VERSION "0.2"

NS_ :

BS_:

BU_: IFV_CWMP IFV_VFP External ExternalX

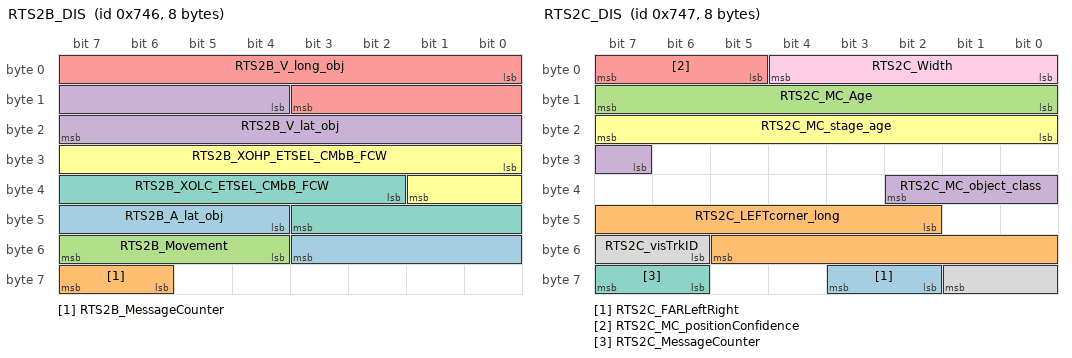
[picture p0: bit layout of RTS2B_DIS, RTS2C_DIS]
BO_ 1862 RTS2B_DIS: 8 IFV_CWMP
 SG_ RTS2B_A_lat_obj : 44|8@1+ (0.1,-10) [-10|10] "m/s^2"  External
 SG_ RTS2B_MessageCounter : 62|2@1+ (1,0) [0|3] ""  External
 SG_ RTS2B_Movement : 52|4@1+ (1,0) [0|15] ""  External
 SG_ RTS2B_V_lat_obj : 12|12@1+ (0.025,-20) [-20|20] "m/s"  External
 SG_ RTS2B_V_long_obj : 0|12@1+ (0.05,-100) [-100|100] "m/s"  External
 SG_ RTS2B_XOHP_ETSEL_CMbB_FCW : 24|10@1+ (0.1,-50) [-50|50] "m"  External
 SG_ RTS2B_XOLC_ETSEL_CMbB_FCW : 34|10@1+ (0.1,-50) [-50|50] "m"  External

BO_ 1863 RTS2C_DIS: 8 IFV_CWMP
 SG_ RTS2C_FARLeftRight : 58|2@1+ (1,0) [0|2] ""  External
 SG_ RTS2C_LEFTcorner_long : 42|12@1+ (0.1,-50) [-50|160] "m"  External
 SG_ RTS2C_MC_Age : 8|8@1+ (1,0) [0|255] ""  External
 SG_ RTS2C_MC_object_class : 31|4@1+ (1,0) [0|10] ""  External
 SG_ RTS2C_MC_positionConfidence : 5|3@1+ (1,0) [0|2] ""  External
 SG_ RTS2C_MC_stage_age : 16|8@1+ (1,0) [0|255] ""  External
 SG_ RTS2C_MessageCounter : 62|2@1+ (1,0) [0|3] ""  External
 SG_ RTS2C_visTrkID : 54|4@1+ (1,0) [0|15] ""  External
 SG_ RTS2C_Width : 0|5@1+ (0.1,0) [0|3] "m"  External

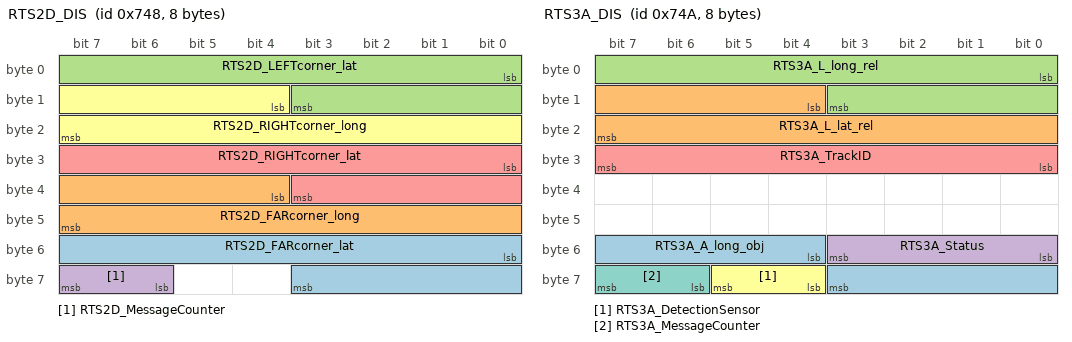
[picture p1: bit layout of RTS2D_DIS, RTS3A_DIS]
BO_ 1864 RTS2D_DIS: 8 IFV_CWMP
 SG_ RTS2D_FARcorner_lat : 48|12@1+ (0.1,-50) [-50|50] "m"  External
 SG_ RTS2D_FARcorner_long : 36|12@1+ (0.1,-50) [-50|160] "m"  External
 SG_ RTS2D_LEFTcorner_lat : 0|12@1+ (0.1,-50) [-50|50] "m"  External
 SG_ RTS2D_MessageCounter : 62|2@1+ (1,0) [0|3] ""  External
 SG_ RTS2D_RIGHTcorner_lat : 24|12@1+ (0.1,-50) [-50|50] "m"  External
 SG_ RTS2D_RIGHTcorner_long : 12|12@1+ (0.1,-50) [-50|160] "m"  External

BO_ 1866 RTS3A_DIS: 8 IFV_CWMP
 SG_ RTS3A_A_long_obj : 52|8@1+ (0.1,-12.5) [-12.5|12.5] "m/s^2"  External
 SG_ RTS3A_L_lat_rel : 12|12@1+ (0.1,-50) [-50|50] "m"  External
 SG_ RTS3A_L_long_rel : 0|12@1+ (0.1,0) [0|180] "m"  External
 SG_ RTS3A_Status : 48|4@1+ (1,0) [0|7] ""  External
 SG_ RTS3A_TrackID : 24|8@1+ (1,0) [0|64] ""  External
 SG_ RTS3A_DetectionSensor : 60|2@1+ (1,0) [0|3] ""  External
 SG_ RTS3A_MessageCounter : 62|2@1+ (1,0) [0|3] ""  External

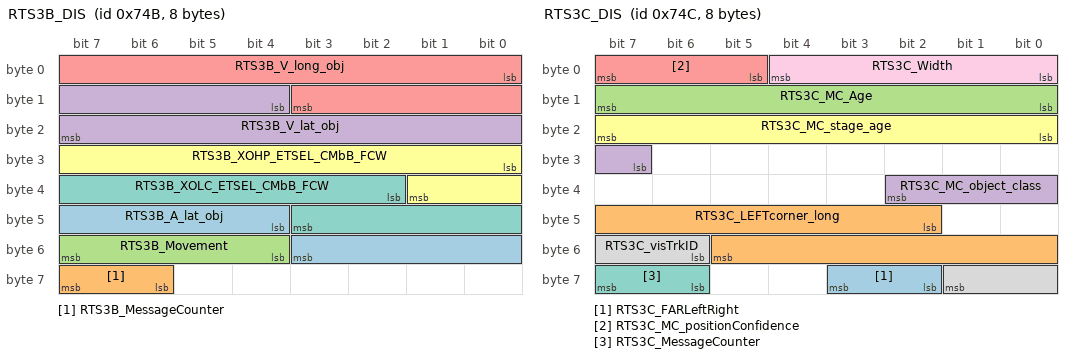
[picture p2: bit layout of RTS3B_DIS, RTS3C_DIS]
BO_ 1867 RTS3B_DIS: 8 IFV_CWMP
 SG_ RTS3B_A_lat_obj : 44|8@1+ (0.1,-10) [-10|10] "m/s^2"  External
 SG_ RTS3B_MessageCounter : 62|2@1+ (1,0) [0|3] ""  External
 SG_ RTS3B_Movement : 52|4@1+ (1,0) [0|15] ""  External
 SG_ RTS3B_V_lat_obj : 12|12@1+ (0.025,-20) [-20|20] "m/s"  External
 SG_ RTS3B_V_long_obj : 0|12@1+ (0.05,-100) [-100|100] "m/s"  External
 SG_ RTS3B_XOHP_ETSEL_CMbB_FCW : 24|10@1+ (0.1,-50) [-50|50] "m"  External
 SG_ RTS3B_XOLC_ETSEL_CMbB_FCW : 34|10@1+ (0.1,-50) [-50|50] "m"  External

BO_ 1868 RTS3C_DIS: 8 IFV_CWMP
 SG_ RTS3C_FARLeftRight : 58|2@1+ (1,0) [0|2] ""  External
 SG_ RTS3C_LEFTcorner_long : 42|12@1+ (0.1,-50) [-50|160] "m"  External
 SG_ RTS3C_MC_Age : 8|8@1+ (1,0) [0|255] ""  External
 SG_ RTS3C_MC_object_class : 31|4@1+ (1,0) [0|10] ""  External
 SG_ RTS3C_MC_positionConfidence : 5|3@1+ (1,0) [0|2] ""  External
 SG_ RTS3C_MC_stage_age : 16|8@1+ (1,0) [0|255] ""  External
 SG_ RTS3C_MessageCounter : 62|2@1+ (1,0) [0|3] ""  External
 SG_ RTS3C_visTrkID : 54|4@1+ (1,0) [0|15] ""  External
 SG_ RTS3C_Width : 0|5@1+ (0.1,0) [0|3] "m"  External

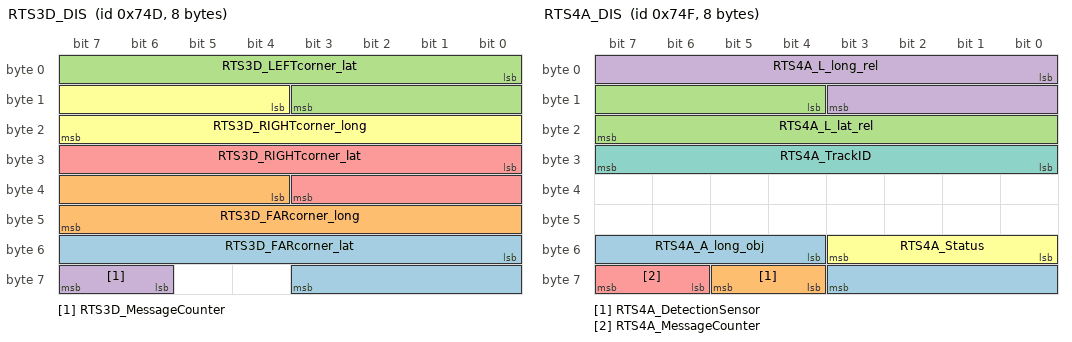
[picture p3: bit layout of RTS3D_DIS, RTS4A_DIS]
BO_ 1869 RTS3D_DIS: 8 IFV_CWMP
 SG_ RTS3D_FARcorner_lat : 48|12@1+ (0.1,-50) [-50|50] "m"  External
 SG_ RTS3D_FARcorner_long : 36|12@1+ (0.1,-50) [-50|160] "m"  External
 SG_ RTS3D_LEFTcorner_lat : 0|12@1+ (0.1,-50) [-50|50] "m"  External
 SG_ RTS3D_MessageCounter : 62|2@1+ (1,0) [0|3] ""  External
 SG_ RTS3D_RIGHTcorner_lat : 24|12@1+ (0.1,-50) [-50|50] "m"  External
 SG_ RTS3D_RIGHTcorner_long : 12|12@1+ (0.1,-50) [-50|160] "m"  External

BO_ 1871 RTS4A_DIS: 8 IFV_CWMP
 SG_ RTS4A_A_long_obj : 52|8@1+ (0.1,-12.5) [-12.5|12.5] "m/s^2"  External
 SG_ RTS4A_DetectionSensor : 60|2@1+ (1,0) [0|3] ""  External
 SG_ RTS4A_L_lat_rel : 12|12@1+ (0.1,-50) [-50|50] "m"  External
 SG_ RTS4A_L_long_rel : 0|12@1+ (0.1,0) [0|180] "m"  External
 SG_ RTS4A_MessageCounter : 62|2@1+ (1,0) [0|3] ""  External
 SG_ RTS4A_Status : 48|4@1+ (1,0) [0|7] ""  External
 SG_ RTS4A_TrackID : 24|8@1+ (1,0) [0|64] ""  External

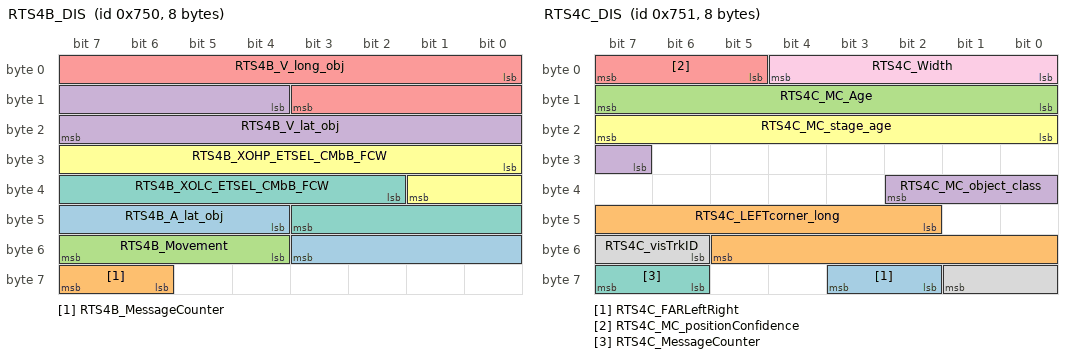
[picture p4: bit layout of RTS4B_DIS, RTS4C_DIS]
BO_ 1872 RTS4B_DIS: 8 IFV_CWMP
 SG_ RTS4B_A_lat_obj : 44|8@1+ (0.1,-10) [-10|10] "m/s^2"  External
 SG_ RTS4B_MessageCounter : 62|2@1+ (1,0) [0|3] ""  External
 SG_ RTS4B_Movement : 52|4@1+ (1,0) [0|15] ""  External
 SG_ RTS4B_V_lat_obj : 12|12@1+ (0.025,-20) [-20|20] "m/s"  External
 SG_ RTS4B_V_long_obj : 0|12@1+ (0.05,-100) [-100|100] "m/s"  External
 SG_ RTS4B_XOHP_ETSEL_CMbB_FCW : 24|10@1+ (0.1,-50) [-50|50] "m"  External
 SG_ RTS4B_XOLC_ETSEL_CMbB_FCW : 34|10@1+ (0.1,-50) [-50|50] "m"  External

BO_ 1873 RTS4C_DIS: 8 IFV_CWMP
 SG_ RTS4C_FARLeftRight : 58|2@1+ (1,0) [0|2] ""  External
 SG_ RTS4C_LEFTcorner_long : 42|12@1+ (0.1,-50) [-50|160] "m"  External
 SG_ RTS4C_MC_Age : 8|8@1+ (1,0) [0|255] ""  External
 SG_ RTS4C_MC_object_class : 31|4@1+ (1,0) [0|10] ""  External
 SG_ RTS4C_MC_positionConfidence : 5|3@1+ (1,0) [0|2] ""  External
 SG_ RTS4C_MC_stage_age : 16|8@1+ (1,0) [0|255] ""  External
 SG_ RTS4C_MessageCounter : 62|2@1+ (1,0) [0|3] ""  External
 SG_ RTS4C_visTrkID : 54|4@1+ (1,0) [0|15] ""  External
 SG_ RTS4C_Width : 0|5@1+ (0.1,0) [0|3] "m"  External

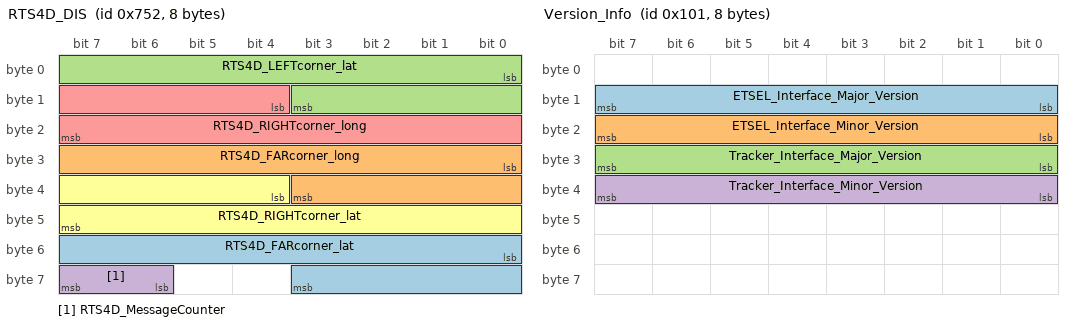
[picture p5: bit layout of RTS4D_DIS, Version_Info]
BO_ 1874 RTS4D_DIS: 8 IFV_CWMP
 SG_ RTS4D_FARcorner_lat : 48|12@1+ (0.1,-50) [-50|50] "m"  External
 SG_ RTS4D_FARcorner_long : 24|12@1+ (0.1,-50) [-50|160] "m"  External
 SG_ RTS4D_LEFTcorner_lat : 0|12@1+ (0.1,-50) [-50|50] "m"  External
 SG_ RTS4D_MessageCounter : 62|2@1+ (1,0) [0|3] ""  External
 SG_ RTS4D_RIGHTcorner_long : 12|12@1+ (0.1,-50) [-50|160] "m"  External
 SG_ RTS4D_RIGHTcorner_lat : 36|12@1+ (0.1,-50) [-50|50] "m"  External

BO_ 257 Version_Info: 8 IFV_VFP
 SG_ ETSEL_Interface_Major_Version : 8|8@1+ (1,0) [0|255] ""  External
 SG_ ETSEL_Interface_Minor_Version : 16|8@1+ (1,0) [0|255] ""  External
 SG_ Tracker_Interface_Major_Version : 24|8@1+ (1,0) [0|255] ""  External
 SG_ Tracker_Interface_Minor_Version : 32|8@1+ (1,0) [0|255] ""  External

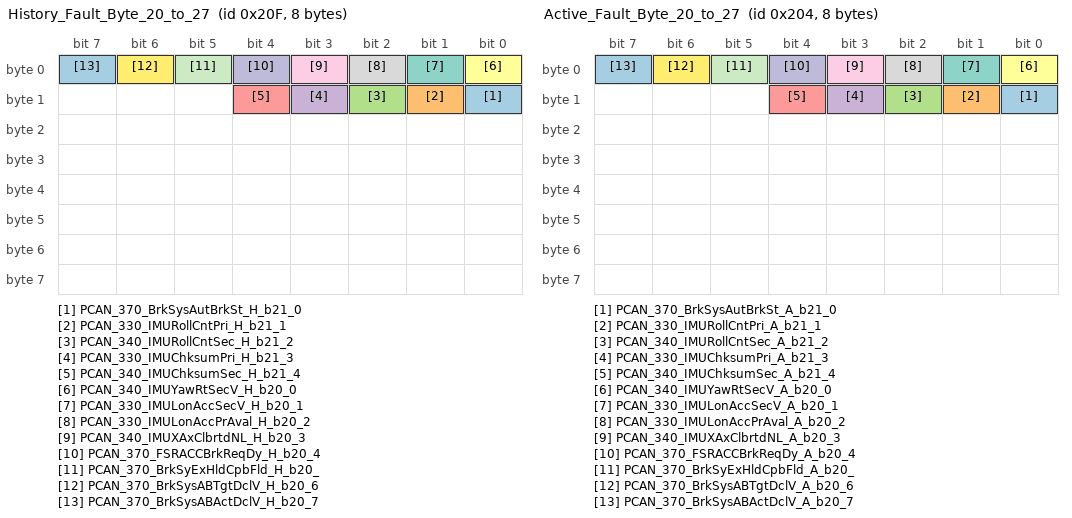
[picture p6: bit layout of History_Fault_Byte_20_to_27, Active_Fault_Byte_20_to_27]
BO_ 527 History_Fault_Byte_20_to_27: 8 IFV_CWMP
 SG_ PCAN_370_BrkSysAutBrkSt_H_b21_0 : 8|1@1+ (1,0) [0|1] ""  External
 SG_ PCAN_330_IMURollCntPri_H_b21_1 : 9|1@1+ (1,0) [0|1] ""  External
 SG_ PCAN_340_IMURollCntSec_H_b21_2 : 10|1@1+ (1,0) [0|1] ""  External
 SG_ PCAN_330_IMUChksumPri_H_b21_3 : 11|1@1+ (1,0) [0|1] ""  External
 SG_ PCAN_340_IMUChksumSec_H_b21_4 : 12|1@1+ (1,0) [0|1] ""  External
 SG_ PCAN_340_IMUYawRtSecV_H_b20_0 : 0|1@1+ (1,0) [0|1] ""  External
 SG_ PCAN_330_IMULonAccSecV_H_b20_1 : 1|1@1+ (1,0) [0|1] ""  External
 SG_ PCAN_330_IMULonAccPrAval_H_b20_2 : 2|1@1+ (1,0) [0|1] ""  External
 SG_ PCAN_340_IMUXAxClbrtdNL_H_b20_3 : 3|1@1+ (1,0) [0|1] ""  External
 SG_ PCAN_370_FSRACCBrkReqDy_H_b20_4 : 4|1@1+ (1,0) [0|1] ""  External
 SG_ PCAN_370_BrkSyExHldCpbFld_H_b20_ : 5|1@1+ (1,0) [0|1] ""  External
 SG_ PCAN_370_BrkSysABTgtDclV_H_b20_6 : 6|1@1+ (1,0) [0|1] ""  External
 SG_ PCAN_370_BrkSysABActDclV_H_b20_7 : 7|1@1+ (1,0) [0|1] ""  External

BO_ 522 History_Fault_Byte_18_to_1F: 8 IFV_CWMP
 SG_ PCAN_330_IMUYawLatAccCB_H_b1F_0 : 56|1@1+ (1,0) [0|1] ""  External
 SG_ PCAN_340_IMUYawLonAccCB_H_b1F_1 : 57|1@1+ (1,0) [0|1] ""  External
 SG_ PCAN_370_AutoBrkStatCB_H_b1F_2 : 58|1@1+ (1,0) [0|1] ""  External
 SG_ PCAN_330_IMULatAccPrimV_H_b1F_3 : 59|1@1+ (1,0) [0|1] ""  External
 SG_ PCAN_330_IMUYawRtPriV_H_b1F_4 : 60|1@1+ (1,0) [0|1] ""  External
 SG_ PCAN_340_IMULonAccPriV_H_b1F_5 : 61|1@1+ (1,0) [0|1] ""  External
 SG_ PCAN_340_IMUDataMsk_H_b1F_6 : 62|1@1+ (1,0) [0|1] ""  External
 SG_ PCAN_340_IMULatACCSecV_H_b1F_7 : 63|1@1+ (1,0) [0|1] ""  External
 SG_ PB_0F1_BrkPedPosARC_H_b1E_0 : 48|1@1+ (1,0) [0|1] ""  External
 SG_ PB_1E1_CrsCntrlSwStARC_H_b1E_1 : 49|1@1+ (1,0) [0|1] ""  External
 SG_ PB_1E1_CrsSpdLmtrSwStARC_H_b1E_2 : 50|1@1+ (1,0) [0|1] ""  External
 SG_ PB_0F1_BrkPdlInTrvPrt_H_b1E_3 : 51|1@1+ (1,0) [0|1] ""  External
 SG_ PB_0F1_BrkPdlChkData_H_b1E_4 : 52|1@1+ (1,0) [0|1] ""  External
 SG_ PB_1E1_CrsCtlSwStProtVal_H_b1E_5 : 53|1@1+ (1,0) [0|1] ""  External
 SG_ PB_1E1_CrsSpdLmtrSwStPVal_H_b1E_ : 54|1@1+ (1,0) [0|1] ""  External
 SG_ PB_12A_DDAjrSwAtvM_H_b1D_0 : 40|1@1+ (1,0) [0|1] ""  External
 SG_ PB_1F1_AirbgVDA_H_b1D_1 : 41|1@1+ (1,0) [0|1] ""  External
 SG_ PB_135_StWhAnVDA_H_b1D_2 : 42|1@1+ (1,0) [0|1] ""  External
 SG_ PB_0F1_BrkPedTrvlAchvdV_H_b1C_0 : 32|1@1+ (1,0) [0|1] ""  External
 SG_ PB_12A_DrSbltAtcV_H_b1C_1 : 33|1@1+ (1,0) [0|1] ""  External
 SG_ PB_1E1_CrsSpdLmtrSwStat_H_b1C_2 : 34|1@1+ (1,0) [0|1] ""  External
 SG_ PB_0F1_BrkAppSnsrHmPosLrnd_H_b1C : 35|1@1+ (1,0) [0|1] ""  External
 SG_ PB_12A_ChmMstrVDA_H_b1C_4 : 36|1@1+ (1,0) [0|1] ""  External
 SG_ PB_12A_IPCVDA_H_b1C_5 : 37|1@1+ (1,0) [0|1] ""  External
 SG_ PB_12A_HeadUpDispVDA_H_b1C_6 : 38|1@1+ (1,0) [0|1] ""  External
 SG_ PB_0F1_BrkAppStMiss_H_b1B_0 : 24|1@1+ (1,0) [0|1] ""  External
 SG_ PB_12A_BodyInfoMiss_H_b1B_1 : 25|1@1+ (1,0) [0|1] ""  External
 SG_ PB_135_BodyInfo2Miss_H_b1B_2 : 26|1@1+ (1,0) [0|1] ""  External
 SG_ PB_1E1_PPEICrCtSwStMiss_H_b1B_3 : 27|1@1+ (1,0) [0|1] ""  External
 SG_ PB_1F1_PPEIPlGStMiss_H_b1B_4 : 28|1@1+ (1,0) [0|1] ""  External
 SG_ PB_140_ExtLgtMiss_H_b1B_5 : 29|1@1+ (1,0) [0|1] ""  External
 SG_ PB_120_VehOdoMiss_H_b1B_6 : 30|1@1+ (1,0) [0|1] ""  External
 SG_ PB_139_BodyInfo4Miss_H_b1B_7 : 31|1@1+ (1,0) [0|1] ""  External
 SG_ PB_1E5_StrWhAngMsk_H_b1A_0 : 16|1@1+ (1,0) [0|1] ""  External
 SG_ PB_1E5_StrWhAngGrdV_H_b1A_1 : 17|1@1+ (1,0) [0|1] ""  External
 SG_ PB_1E5_StrWhlASCalNL_H_b1A_2 : 18|1@1+ (1,0) [0|1] ""  External
 SG_ PB_184_LKATrqOvrlDlvdRC_H_b1A_4 : 20|1@1+ (1,0) [0|1] ""  External
 SG_ PB_1E5_StWhlAngARC_H_b1A_5 : 21|1@1+ (1,0) [0|1] ""  External
 SG_ PB_184_LKATrqOvrlChksm_H_b1A_6 : 22|1@1+ (1,0) [0|1] ""  External
 SG_ PB_1E5_StrAngSnsChksm_H_b1A_7 : 23|1@1+ (1,0) [0|1] ""  External
 SG_ PB_184_LKAStTrqOvMiss_H_b19_0 : 8|1@1+ (1,0) [0|1] ""  External
 SG_ PB_1E5_PPEIStWhlAglMiss_H_b19_1 : 9|1@1+ (1,0) [0|1] ""  External
 SG_ PB_184_HndOffStrWhlDtStV_H_b19_2 : 10|1@1+ (1,0) [0|1] ""  External
 SG_ PB_184_LKADrvAppldTrqV_H_b19_3 : 11|1@1+ (1,0) [0|1] ""  External
 SG_ PB_184_HndsOffStrWhlDtMd_H_b19_4 : 12|1@1+ (1,0) [0|1] ""  External
 SG_ PB_184_LKATrqOvrlTrqDSt_H_b19_5 : 13|1@1+ (1,0) [0|1] ""  External
 SG_ PB_1E5_StrWhAngV_H_b19_6 : 14|1@1+ (1,0) [0|1] ""  External
 SG_ PB_1E5_StrWhAngGrdMsk_H_b19_7 : 15|1@1+ (1,0) [0|1] ""  External
 SG_ PB_0C5_WWhlDistVal_H_b18_0 : 0|1@1+ (1,0) [0|1] ""  External
 SG_ PB_0C5_WWhlDistVal_H_b18_1 : 1|1@1+ (1,0) [0|1] ""  External
 SG_ PB_230_ElecPrkBrkStat_H_b18_2 : 2|1@1+ (1,0) [0|1] ""  External
 SG_ PB_214_BPDrvAppPrsAlRC_H_b18_4 : 4|1@1+ (1,0) [0|1] ""  External
 SG_ PB_2F9_HillDCStARC_H_b18_5 : 5|1@1+ (1,0) [0|1] ""  External
 SG_ PB_214_BPDAPrsStaPVal_H_b18_6 : 6|1@1+ (1,0) [0|1] ""  External
 SG_ PB_2F9_HillDCStatPVal_H_b18_7 : 7|1@1+ (1,0) [0|1] ""  External

BO_ 521 History_Fault_Byte_10_to_17: 8 IFV_CWMP
 SG_ PB_348_WhlGVLftDrvnV_H_b17_0 : 56|1@1+ (1,0) [0|1] ""  External
 SG_ PB_348_WhlGVRtDrvnV_H_b17_1 : 57|1@1+ (1,0) [0|1] ""  External
 SG_ PB_1E9_VhDynCntlSysSt_H_b17_2 : 58|1@1+ (1,0) [0|1] ""  External
 SG_ PB_17D_TCSysOpStat_H_b17_3 : 59|1@1+ (1,0) [0|1] ""  External
 SG_ PB_17D_VehStabEnhSt_H_b17_4 : 60|1@1+ (1,0) [0|1] ""  External
 SG_ PB_214_BrkSAutBrkFld_H_b17_5 : 61|1@1+ (1,0) [0|1] ""  External
 SG_ PB_0C1_WWhlDistVal_H_b17_6 : 62|1@1+ (1,0) [0|1] ""  External
 SG_ PB_0C1_WWhlDistVal_H_b17_7 : 63|1@1+ (1,0) [0|1] ""  External
 SG_ PB_1C7_PPEIChETrq1Miss_H_b16_0 : 48|1@1+ (1,0) [0|1] ""  External
 SG_ PB_2F9_PPEIChGen2Miss_H_b16_1 : 49|1@1+ (1,0) [0|1] ""  External
 SG_ PB_17D_ActVehAccelV_H_b16_3 : 51|1@1+ (1,0) [0|1] ""  External
 SG_ PB_214_BkPDrvApPV_H_b16_4 : 52|1@1+ (1,0) [0|1] ""  External
 SG_ PB_1E9_BPDAPrsDetcdV_H_b16_5 : 53|1@1+ (1,0) [0|1] ""  External
 SG_ PB_34A_WhlGVLftNnDrvnV_H_b16_6 : 54|1@1+ (1,0) [0|1] ""  External
 SG_ PB_34A_WhlGVRtNnDrvnV_H_b16_7 : 55|1@1+ (1,0) [0|1] ""  External
 SG_ PB_17D_ABTCStMiss_H_b15_0 : 40|1@1+ (1,0) [0|1] ""  External
 SG_ PB_1E9_PPEIChsGSt1Miss_H_b15_2 : 42|1@1+ (1,0) [0|1] ""  External
 SG_ PB_214_BPDrvStMiss_H_b15_3 : 43|1@1+ (1,0) [0|1] ""  External
 SG_ PB_348_DrWhlGVelMiss_H_b15_4 : 44|1@1+ (1,0) [0|1] ""  External
 SG_ PB_34A_NDrWhlGVelMiss_H_b15_5 : 45|1@1+ (1,0) [0|1] ""  External
 SG_ PB_0C1_PPEIDrWhlRotMiss_H_b15_6 : 46|1@1+ (1,0) [0|1] ""  External
 SG_ PB_0C5_PPEINDrWhlRotMiss_H_b15_7 : 47|1@1+ (1,0) [0|1] ""  External
 SG_ PB_0C9_EngSpdStat_H_b14_0 : 32|1@1+ (1,0) [0|1] ""  External
 SG_ PB_1C4_AccPdlOvrrdAtvARC_H_b14_4 : 36|1@1+ (1,0) [0|1] ""  External
 SG_ PB_1C4_AutBrkAccActPsRC_H_b14_5 : 37|1@1+ (1,0) [0|1] ""  External
 SG_ PB_1C4_AccPdlOvAtvProtVal_H_b14_ : 38|1@1+ (1,0) [0|1] ""  External
 SG_ PB_1C4_AutBrkAccActPsPVal_H_b14_ : 39|1@1+ (1,0) [0|1] ""  External
 SG_ PB_2C3_EngTrqMinExtRngV_H_b13_0 : 24|1@1+ (1,0) [0|1] ""  External
 SG_ PB_0C9_PT_BPdDscrtInpStV_H_b13_1 : 25|1@1+ (1,0) [0|1] ""  External
 SG_ PB_1F5_TopTrvICltSwActV_H_b13_2 : 26|1@1+ (1,0) [0|1] ""  External
 SG_ PB_1F5_TransEstGearV_H_b13_3 : 27|1@1+ (1,0) [0|1] ""  External
 SG_ PB_1F5_TrnsEngdStateV_H_b13_4 : 28|1@1+ (1,0) [0|1] ""  External
 SG_ PB_3E9_VehSpdAvgDrvnV_H_b13_5 : 29|1@1+ (1,0) [0|1] ""  External
 SG_ PB_3E9_VehSpdAvgNDrvnV_H_b13_6 : 30|1@1+ (1,0) [0|1] ""  External
 SG_ PB_1C4_ACCATCS_RqStat_H_b13_7 : 31|1@1+ (1,0) [0|1] ""  External
 SG_ PB_4F3_PPEIPTCfg2Miss_H_b12_0 : 16|1@1+ (1,0) [0|1] ""  External
 SG_ PB_1C4_ABAAPS_AccPosV_H_b12_1 : 17|1@1+ (1,0) [0|1] ""  External
 SG_ PB_1C5_DrvIAxlTrqMaxV_H_b12_2 : 18|1@1+ (1,0) [0|1] ""  External
 SG_ PB_1C5_DrvIAxlTrqMinV_H_b12_3 : 19|1@1+ (1,0) [0|1] ""  External
 SG_ PB_1C5_DrvIntndAxlTrqV_H_b12_4 : 20|1@1+ (1,0) [0|1] ""  External
 SG_ PB_1C3_EngTrqActExtRngV_H_b12_5 : 21|1@1+ (1,0) [0|1] ""  External
 SG_ PB_1C3_EngTqDrRqExtRngV_H_b12_6 : 22|1@1+ (1,0) [0|1] ""  External
 SG_ PB_2C3_EngTrqMaxExtRngV_H_b12_7 : 23|1@1+ (1,0) [0|1] ""  External
 SG_ PB_0C9_PPEIEngGSt1Miss_H_b11_0 : 8|1@1+ (1,0) [0|1] ""  External
 SG_ PB_1C3_PPEIEngTrqSt2Miss_H_b11_1 : 9|1@1+ (1,0) [0|1] ""  External
 SG_ PB_1C4_PPEITrqReqStMiss_H_b11_2 : 10|1@1+ (1,0) [0|1] ""  External
 SG_ PB_1C5_PPEIDrIAxTqStMiss_H_b11_3 : 11|1@1+ (1,0) [0|1] ""  External
 SG_ PB_1F5_PPEITrGenSt2Miss_H_b11_4 : 12|1@1+ (1,0) [0|1] ""  External
 SG_ PB_2C3_PPEIEngTrqSt3Miss_H_b11_5 : 13|1@1+ (1,0) [0|1] ""  External
 SG_ PB_3E9_PPEIVehSpdDisMiss_H_b11_6 : 14|1@1+ (1,0) [0|1] ""  External
 SG_ PB_4F1_PPEIPTConfMiss_H_b11_7 : 15|1@1+ (1,0) [0|1] ""  External
 SG_ MRRPCANIntComp_H_b10_0 : 0|1@1+ (1,0) [0|1] ""  External
 SG_ PCAN_330_IMULonAccSecAval_H_b10_ : 1|1@1+ (1,0) [0|1] ""  External
 SG_ PCAN_340_IMUYawRtSecAval_H_b10_2 : 2|1@1+ (1,0) [0|1] ""  External
 SG_ PCAN_340_IMULatAccSecAval_H_b10_ : 3|1@1+ (1,0) [0|1] ""  External
 SG_ PB_1E5_StrWhlAngSenTyp_H_b10_5 : 5|1@1+ (1,0) [0|1] ""  External

BO_ 520 History_Fault_Byte_8_to_F: 8 IFV_CWMP
 SG_ FCMIndSTB_H_bF_0 : 56|1@1+ (1,0) [0|1] ""  External
 SG_ FCMIndSTGorOPN_H_bF_1 : 57|1@1+ (1,0) [0|1] ""  External
 SG_ LKASwtchSTG_H_bF_2 : 58|1@1+ (1,0) [0|1] ""  External
 SG_ MRRPCANMissingMsgHOST_H_bF_4 : 60|1@1+ (1,0) [0|1] ""  External
 SG_ MRRPCANMissingMsgVFP_H_bF_5 : 61|1@1+ (1,0) [0|1] ""  External
 SG_ MRRPCANRangeCheckVFP_H_bF_6 : 62|1@1+ (1,0) [0|1] ""  External
 SG_ MRRPCANInvalidDataVFP_H_bF_7 : 63|1@1+ (1,0) [0|1] ""  External
 SG_ VisionInternalError_H_bE_0 : 48|1@1+ (1,0) [0|1] ""  External
 SG_ VINMismatch_H_bE_1 : 49|1@1+ (1,0) [0|1] ""  External
 SG_ ECUSWCalDataSetNotProg_H_bE_2 : 50|1@1+ (1,0) [0|1] ""  External
 SG_ VehConfNotProg_H_bE_3 : 51|1@1+ (1,0) [0|1] ""  External
 SG_ VINNotProg_H_bE_4 : 52|1@1+ (1,0) [0|1] ""  External
 SG_ CameraCalNotLearnt_H_bE_5 : 53|1@1+ (1,0) [0|1] ""  External
 SG_ HostVCANBusOff_H_bE_6 : 54|1@1+ (1,0) [0|1] ""  External
 SG_ SysDisabledInfoStored_H_bE_7 : 55|1@1+ (1,0) [0|1] ""  External
 SG_ HostCoreSelftestFault_H_bD_0 : 40|1@1+ (1,0) [0|1] ""  External
 SG_ ECCSelfTestCheckFault_H_bD_1 : 41|1@1+ (1,0) [0|1] ""  External
 SG_ HostCoreExceptionFault_H_bD_2 : 42|1@1+ (1,0) [0|1] ""  External
 SG_ HostCtrConfigRegFault_H_bD_3 : 43|1@1+ (1,0) [0|1] ""  External
 SG_ HostADCSelfTestFault_H_bD_4 : 44|1@1+ (1,0) [0|1] ""  External
 SG_ HostADCMonitorFault_H_bD_5 : 45|1@1+ (1,0) [0|1] ""  External
 SG_ HostCVMResetFault_H_bD_6 : 46|1@1+ (1,0) [0|1] ""  External
 SG_ HostCVMSTsetFault_H_bD_7 : 47|1@1+ (1,0) [0|1] ""  External
 SG_ AlignAdjustIncorrect_H_bC_0 : 32|1@1+ (1,0) [0|1] ""  External
 SG_ VisionRadar_Missaligned_H_bC_1 : 33|1@1+ (1,0) [0|1] ""  External
 SG_ Vision_OutOfFocus_Fault_H_bC_2 : 34|1@1+ (1,0) [0|1] ""  External
 SG_ Vision_OutOfCalibration_H_bC_3 : 35|1@1+ (1,0) [0|1] ""  External
 SG_ HostISRConsistencyCheck_H_bC_5 : 37|1@1+ (1,0) [0|1] ""  External
 SG_ ECCSelfTest_CF_H_bC_6 : 38|1@1+ (1,0) [0|1] ""  External
 SG_ ECCSelfTest_RAM_H_bC_7 : 39|1@1+ (1,0) [0|1] ""  External
 SG_ Smeared_Spots_fault_H_bB_0 : 24|1@1+ (1,0) [0|1] ""  External
 SG_ SelfGlare_fault_H_bB_1 : 25|1@1+ (1,0) [0|1] ""  External
 SG_ Low_Visibility_fault_H_bB_2 : 26|1@1+ (1,0) [0|1] ""  External
 SG_ imager_pattern_fault_H_bB_4 : 28|1@1+ (1,0) [0|1] ""  External
 SG_ HostSWP2RAMCRCFlt_H_bB_5 : 29|1@1+ (1,0) [0|1] ""  External
 SG_ VisionAlignIncomplete_H_bB_6 : 30|1@1+ (1,0) [0|1] ""  External
 SG_ Full_Blockage_fault_H_bA_0 : 16|1@1+ (1,0) [0|1] ""  External
 SG_ Blurred_Image_fault_H_bA_1 : 17|1@1+ (1,0) [0|1] ""  External
 SG_ TD_Blockage_Fault_H_bA_2 : 18|1@1+ (1,0) [0|1] ""  External
 SG_ Splashes_fault_H_bA_3 : 19|1@1+ (1,0) [0|1] ""  External
 SG_ Low_Sun_fault_H_bA_4 : 20|1@1+ (1,0) [0|1] ""  External
 SG_ Sun_Rays_faults_H_bA_5 : 21|1@1+ (1,0) [0|1] ""  External
 SG_ Foggy_Spots_fault_H_bA_6 : 22|1@1+ (1,0) [0|1] ""  External
 SG_ Spot_Rays_fault_H_bA_7 : 23|1@1+ (1,0) [0|1] ""  External
 SG_ HostPLLStoppedFault_H_b9_0 : 8|1@1+ (1,0) [0|1] ""  External
 SG_ HostWatchDogSelftestFault_H_b9_1 : 9|1@1+ (1,0) [0|1] ""  External
 SG_ VfpCamMalFunc_H_b9_2 : 10|1@1+ (1,0) [0|1] ""  External
 SG_ VfpCamCtrlFlt_H_b9_3 : 11|1@1+ (1,0) [0|1] ""  External
 SG_ VfpCamVdoFlt_H_b9_5 : 13|1@1+ (1,0) [0|1] ""  External
 SG_ Partial_Blockage_fault_H_b9_7 : 15|1@1+ (1,0) [0|1] ""  External
 SG_ CMBB_ACC_ValFault_H_b8_2 : 2|1@1+ (1,0) [0|1] ""  External
 SG_ HostSWResetMismatchFault_H_b8_3 : 3|1@1+ (1,0) [0|1] ""  External
 SG_ CAN_BDU_Msg_Invalid_H_b8_4 : 4|1@1+ (1,0) [0|1] ""  External
 SG_ HostCSIHPeripheralFault_H_b8_5 : 5|1@1+ (1,0) [0|1] ""  External
 SG_ HostCANPeripheralFault_H_b8_6 : 6|1@1+ (1,0) [0|1] ""  External
 SG_ HostHighSpdOscStopFault_H_b8_7 : 7|1@1+ (1,0) [0|1] ""  External

BO_ 519 History_Fault_Byte_0_to_7: 8 IFV_CWMP
 SG_ grab_issue_failure_H_b7_0 : 56|1@1+ (1,0) [0|1] ""  External
 SG_ grab_acquire_failure_H_b7_1 : 57|1@1+ (1,0) [0|1] ""  External
 SG_ grab_release_failure_H_b7_2 : 58|1@1+ (1,0) [0|1] ""  External
 SG_ VFP_subsystem_comm_fault_H_b7_3 : 59|1@1+ (1,0) [0|1] ""  External
 SG_ parameters_invalid_H_b7_4 : 60|1@1+ (1,0) [0|1] ""  External
 SG_ ThermistorOutOfRange_H_b7_5 : 61|1@1+ (1,0) [0|1] ""  External
 SG_ BatteryHighFault_H_b7_6 : 62|1@1+ (1,0) [0|1] ""  External
 SG_ BatteryLowFault_H_b7_7 : 63|1@1+ (1,0) [0|1] ""  External
 SG_ VFPCoreDumpFault_H_b6_0 : 48|1@1+ (1,0) [0|1] ""  External
 SG_ DDROverTemp_H_b6_1 : 49|1@1+ (1,0) [0|1] ""  External
 SG_ BusOffPCAN_H_b6_3 : 51|1@1+ (1,0) [0|1] ""  External
 SG_ init_vdi_failure_H_b6_5 : 53|1@1+ (1,0) [0|1] ""  External
 SG_ init_I2C_failure_H_b6_6 : 54|1@1+ (1,0) [0|1] ""  External
 SG_ grab_no_free_header_failure_H_b6 : 55|1@1+ (1,0) [0|1] ""  External
 SG_ HostSpiCRC_H_b5_0 : 40|1@1+ (1,0) [0|1] ""  External
 SG_ VFPSpiFrameFormatError_H_b5_1 : 41|1@1+ (1,0) [0|1] ""  External
 SG_ VFPSpiMsgFormatError_H_b5_2 : 42|1@1+ (1,0) [0|1] ""  External
 SG_ VFPSpiMsgTimeout_H_b5_3 : 43|1@1+ (1,0) [0|1] ""  External
 SG_ VFPModeFault_H_b5_4 : 44|1@1+ (1,0) [0|1] ""  External
 SG_ VFPSpiCRC_H_b5_5 : 45|1@1+ (1,0) [0|1] ""  External
 SG_ SpiIpcCommReset_H_b5_6 : 46|1@1+ (1,0) [0|1] ""  External
 SG_ VFPInitTimeout_H_b5_7 : 47|1@1+ (1,0) [0|1] ""  External
 SG_ v2_8_ImagerInterfaceFault_H_b4_0 : 32|1@1+ (1,0) [0|1] ""  External
 SG_ v1_8_SupplyOutOfRangeFault_H_b4_ : 33|1@1+ (1,0) [0|1] ""  External
 SG_ v1_2_SupplyOutOfRangeFault_H_b4_ : 34|1@1+ (1,0) [0|1] ""  External
 SG_ HostSpiFrameFormatError_H_b4_3 : 35|1@1+ (1,0) [0|1] ""  External
 SG_ HostSpiMsgFormatError_H_b4_4 : 36|1@1+ (1,0) [0|1] ""  External
 SG_ HostSpiMsgTimeout_H_b4_5 : 37|1@1+ (1,0) [0|1] ""  External
 SG_ SPIVersionMismatch_H_b4_6 : 38|1@1+ (1,0) [0|1] ""  External
 SG_ HostSpiTxError_H_b4_7 : 39|1@1+ (1,0) [0|1] ""  External
 SG_ VFPBootOverTemp_H_b3_0 : 24|1@1+ (1,0) [0|1] ""  External
 SG_ HostRAMECC_H_b3_1 : 25|1@1+ (1,0) [0|1] ""  External
 SG_ HostInstructionSetCheckFault_H_b : 26|1@1+ (1,0) [0|1] ""  External
 SG_ VfpBistMemRFlt_H_b3_3 : 27|1@1+ (1,0) [0|1] ""  External
 SG_ HostOscillatorStopped_H_b3_4 : 28|1@1+ (1,0) [0|1] ""  External
 SG_ HostStackOverflowFault_H_b3_5 : 29|1@1+ (1,0) [0|1] ""  External
 SG_ HostCOPFault_H_b3_6 : 30|1@1+ (1,0) [0|1] ""  External
 SG_ v5_0_SupplyOutOfRangeFault_H_b3_ : 31|1@1+ (1,0) [0|1] ""  External
 SG_ VfpDDRFlt_H_b2_0 : 16|1@1+ (1,0) [0|1] ""  External
 SG_ DdrRamCrc_H_b2_1 : 17|1@1+ (1,0) [0|1] ""  External
 SG_ VfpBootFlt_H_b2_2 : 18|1@1+ (1,0) [0|1] ""  External
 SG_ VfpCoreFlt_H_b2_3 : 19|1@1+ (1,0) [0|1] ""  External
 SG_ HostCodeFlashECC_H_b2_4 : 20|1@1+ (1,0) [0|1] ""  External
 SG_ HostDataFlashECC_H_b2_5 : 21|1@1+ (1,0) [0|1] ""  External
 SG_ SerialFlashPowerUpFail_H_b2_6 : 22|1@1+ (1,0) [0|1] ""  External
 SG_ HostRamFault_H_b2_7 : 23|1@1+ (1,0) [0|1] ""  External
 SG_ KAMChecksumFault_H_b1_0 : 8|1@1+ (1,0) [0|1] ""  External
 SG_ HostApplicationCRC_H_b1_1 : 9|1@1+ (1,0) [0|1] ""  External
 SG_ HostCalibrationCRC_H_b1_2 : 10|1@1+ (1,0) [0|1] ""  External
 SG_ VFPApplicationChecksum_H_b1_3 : 11|1@1+ (1,0) [0|1] ""  External
 SG_ VFPCalibrationChecksum_H_b1_4 : 12|1@1+ (1,0) [0|1] ""  External
 SG_ HostCalComplAndCompat_H_b1_5 : 13|1@1+ (1,0) [0|1] ""  External
 SG_ VFPAppComplAndCompat_H_b1_6 : 14|1@1+ (1,0) [0|1] ""  External
 SG_ InvalidAHBCSensParams_H_b1_7 : 15|1@1+ (1,0) [0|1] ""  External
 SG_ VFPCalComplCompatSWP3_H_b0_1 : 1|1@1+ (1,0) [0|1] ""  External
 SG_ VFPCalComplCompatSWP5_H_b0_2 : 2|1@1+ (1,0) [0|1] ""  External
 SG_ SystemOverTemperature_H_b0_3 : 3|1@1+ (1,0) [0|1] ""  External
 SG_ OnBdThermOvrTemp_H_b0_4 : 4|1@1+ (1,0) [0|1] ""  External
 SG_ VFPMIPSOverTemp_H_b0_5 : 5|1@1+ (1,0) [0|1] ""  External
 SG_ VFPVMPOverTemp_H_b0_6 : 6|1@1+ (1,0) [0|1] ""  External
 SG_ VFPImagerOverTemp_H_b0_7 : 7|1@1+ (1,0) [0|1] ""  External

BO_ 516 Active_Fault_Byte_20_to_27: 8 IFV_CWMP
 SG_ PCAN_370_BrkSysAutBrkSt_A_b21_0 : 8|1@1+ (1,0) [0|1] ""  External
 SG_ PCAN_330_IMURollCntPri_A_b21_1 : 9|1@1+ (1,0) [0|1] ""  External
 SG_ PCAN_340_IMURollCntSec_A_b21_2 : 10|1@1+ (1,0) [0|1] ""  External
 SG_ PCAN_330_IMUChksumPri_A_b21_3 : 11|1@1+ (1,0) [0|1] ""  External
 SG_ PCAN_340_IMUChksumSec_A_b21_4 : 12|1@1+ (1,0) [0|1] ""  External
 SG_ PCAN_340_IMUYawRtSecV_A_b20_0 : 0|1@1+ (1,0) [0|1] ""  External
 SG_ PCAN_330_IMULonAccSecV_A_b20_1 : 1|1@1+ (1,0) [0|1] ""  External
 SG_ PCAN_330_IMULonAccPrAval_A_b20_2 : 2|1@1+ (1,0) [0|1] ""  External
 SG_ PCAN_340_IMUXAxClbrtdNL_A_b20_3 : 3|1@1+ (1,0) [0|1] ""  External
 SG_ PCAN_370_FSRACCBrkReqDy_A_b20_4 : 4|1@1+ (1,0) [0|1] ""  External
 SG_ PCAN_370_BrkSyExHldCpbFld_A_b20_ : 5|1@1+ (1,0) [0|1] ""  External
 SG_ PCAN_370_BrkSysABTgtDclV_A_b20_6 : 6|1@1+ (1,0) [0|1] ""  External
 SG_ PCAN_370_BrkSysABActDclV_A_b20_7 : 7|1@1+ (1,0) [0|1] ""  External

BO_ 515 Active_Fault_Byte_18_to_1F: 8 IFV_CWMP
 SG_ PCAN_330_IMUYawLatAccCB_A_b1F_0 : 56|1@1+ (1,0) [0|1] ""  External
 SG_ PCAN_340_IMUYawLonAccCB_A_b1F_1 : 57|1@1+ (1,0) [0|1] ""  External
 SG_ PCAN_370_AutoBrkStatCB_A_b1F_2 : 58|1@1+ (1,0) [0|1] ""  External
 SG_ PCAN_330_IMULatAccPrimV_A_b1F_3 : 59|1@1+ (1,0) [0|1] ""  External
 SG_ PCAN_330_IMUYawRtPriV_A_b1F_4 : 60|1@1+ (1,0) [0|1] ""  External
 SG_ PCAN_340_IMULonAccPriV_A_b1F_5 : 61|1@1+ (1,0) [0|1] ""  External
 SG_ PCAN_340_IMUDataMsk_A_b1F_6 : 62|1@1+ (1,0) [0|1] ""  External
 SG_ PCAN_340_IMULatACCSecV_A_b1F_7 : 63|1@1+ (1,0) [0|1] ""  External
 SG_ PB_0F1_BrkPedPosARC_A_b1E_0 : 48|1@1+ (1,0) [0|1] ""  External
 SG_ PB_1E1_CrsCntrlSwStARC_A_b1E_1 : 49|1@1+ (1,0) [0|1] ""  External
 SG_ PB_1E1_CrsSpdLmtrSwStARC_A_b1E_2 : 50|1@1+ (1,0) [0|1] ""  External
 SG_ PB_0F1_BrkPdlInTrvPrt_A_b1E_3 : 51|1@1+ (1,0) [0|1] ""  External
 SG_ PB_0F1_BrkPdlChkData_A_b1E_4 : 52|1@1+ (1,0) [0|1] ""  External
 SG_ PB_1E1_CrsCtlSwStProtVal_A_b1E_5 : 53|1@1+ (1,0) [0|1] ""  External
 SG_ PB_1E1_CrsSpdLmtrSwStPVal_A_b1E_ : 54|1@1+ (1,0) [0|1] ""  External
 SG_ PB_12A_DDAjrSwAtvM_A_b1D_0 : 40|1@1+ (1,0) [0|1] ""  External
 SG_ PB_1F1_AirbgVDA_A_b1D_1 : 41|1@1+ (1,0) [0|1] ""  External
 SG_ PB_135_StWhAnVDA_A_b1D_2 : 42|1@1+ (1,0) [0|1] ""  External
 SG_ PB_0F1_BrkPedTrvlAchvdV_A_b1C_0 : 32|1@1+ (1,0) [0|1] ""  External
 SG_ PB_12A_DrSbltAtcV_A_b1C_1 : 33|1@1+ (1,0) [0|1] ""  External
 SG_ PB_1E1_CrsSpdLmtrSwStat_A_b1C_2 : 34|1@1+ (1,0) [0|1] ""  External
 SG_ PB_0F1_BrkAppSnsrHmPosLrnd_A_b1C : 35|1@1+ (1,0) [0|1] ""  External
 SG_ PB_12A_ChmMstrVDA_A_b1C_4 : 36|1@1+ (1,0) [0|1] ""  External
 SG_ PB_12A_IPCVDA_A_b1C_5 : 37|1@1+ (1,0) [0|1] ""  External
 SG_ PB_12A_HeadUpDispVDA_A_b1C_6 : 38|1@1+ (1,0) [0|1] ""  External
 SG_ PB_0F1_BrkAppStMiss_A_b1B_0 : 24|1@1+ (1,0) [0|1] ""  External
 SG_ PB_12A_BodyInfoMiss_A_b1B_1 : 25|1@1+ (1,0) [0|1] ""  External
 SG_ PB_135_BodyInfo2Miss_A_b1B_2 : 26|1@1+ (1,0) [0|1] ""  External
 SG_ PB_1E1_PPEICrCtSwStMiss_A_b1B_3 : 27|1@1+ (1,0) [0|1] ""  External
 SG_ PB_1F1_PPEIPlGStMiss_A_b1B_4 : 28|1@1+ (1,0) [0|1] ""  External
 SG_ PB_140_ExtLgtMiss_A_b1B_5 : 29|1@1+ (1,0) [0|1] ""  External
 SG_ PB_120_VehOdoMiss_A_b1B_6 : 30|1@1+ (1,0) [0|1] ""  External
 SG_ PB_139_BodyInfo4Miss_A_b1B_7 : 31|1@1+ (1,0) [0|1] ""  External
 SG_ PB_1E5_StrWhAngMsk_A_b1A_0 : 16|1@1+ (1,0) [0|1] ""  External
 SG_ PB_1E5_StrWhAngGrdV_A_b1A_1 : 17|1@1+ (1,0) [0|1] ""  External
 SG_ PB_1E5_StrWhlASCalNL_A_b1A_2 : 18|1@1+ (1,0) [0|1] ""  External
 SG_ PB_184_LKATrqOvrlDlvdRC_A_b1A_4 : 20|1@1+ (1,0) [0|1] ""  External
 SG_ PB_1E5_StWhlAngARC_A_b1A_5 : 21|1@1+ (1,0) [0|1] ""  External
 SG_ PB_184_LKATrqOvrlChksm_A_b1A_6 : 22|1@1+ (1,0) [0|1] ""  External
 SG_ PB_1E5_StrAngSnsChksm_A_b1A_7 : 23|1@1+ (1,0) [0|1] ""  External
 SG_ PB_184_LKAStTrqOvMiss_A_b19_0 : 8|1@1+ (1,0) [0|1] ""  External
 SG_ PB_1E5_PPEIStWhlAglMiss_A_b19_1 : 9|1@1+ (1,0) [0|1] ""  External
 SG_ PB_184_HndOffStrWhlDtStV_A_b19_2 : 10|1@1+ (1,0) [0|1] ""  External
 SG_ PB_184_LKADrvAppldTrqV_A_b19_3 : 11|1@1+ (1,0) [0|1] ""  External
 SG_ PB_184_HndsOffStrWhlDtMd_A_b19_4 : 12|1@1+ (1,0) [0|1] ""  External
 SG_ PB_184_LKATrqOvrlTrqDSt_A_b19_5 : 13|1@1+ (1,0) [0|1] ""  External
 SG_ PB_1E5_StrWhAngV_A_b19_6 : 14|1@1+ (1,0) [0|1] ""  External
 SG_ PB_1E5_StrWhAngGrdMsk_A_b19_7 : 15|1@1+ (1,0) [0|1] ""  External
 SG_ PB_0C5_WWhlDistVal_A_b18_0 : 0|1@1+ (1,0) [0|1] ""  External
 SG_ PB_0C5_WWhlDistVal_A_b18_1 : 1|1@1+ (1,0) [0|1] ""  External
 SG_ PB_230_ElecPrkBrkStat_A_b18_2 : 2|1@1+ (1,0) [0|1] ""  External
 SG_ PB_214_BPDrvAppPrsAlRC_A_b18_4 : 4|1@1+ (1,0) [0|1] ""  External
 SG_ PB_2F9_HillDCStARC_A_b18_5 : 5|1@1+ (1,0) [0|1] ""  External
 SG_ PB_214_BPDAPrsStaPVal_A_b18_6 : 6|1@1+ (1,0) [0|1] ""  External
 SG_ PB_2F9_HillDCStatPVal_A_b18_7 : 7|1@1+ (1,0) [0|1] ""  External

BO_ 514 Active_Fault_Byte_10_to_17: 8 IFV_CWMP
 SG_ PB_348_WhlGVLftDrvnV_A_b17_0 : 56|1@1+ (1,0) [0|1] ""  External
 SG_ PB_348_WhlGVRtDrvnV_A_b17_1 : 57|1@1+ (1,0) [0|1] ""  External
 SG_ PB_1E9_VhDynCntlSysSt_A_b17_2 : 58|1@1+ (1,0) [0|1] ""  External
 SG_ PB_17D_TCSysOpStat_A_b17_3 : 59|1@1+ (1,0) [0|1] ""  External
 SG_ PB_17D_VehStabEnhSt_A_b17_4 : 60|1@1+ (1,0) [0|1] ""  External
 SG_ PB_214_BrkSAutBrkFld_A_b17_5 : 61|1@1+ (1,0) [0|1] ""  External
 SG_ PB_0C1_WWhlDistVal_A_b17_6 : 62|1@1+ (1,0) [0|1] ""  External
 SG_ PB_0C1_WWhlDistVal_A_b17_7 : 63|1@1+ (1,0) [0|1] ""  External
 SG_ PB_1C7_PPEIChETrq1Miss_A_b16_0 : 48|1@1+ (1,0) [0|1] ""  External
 SG_ PB_2F9_PPEIChGen2Miss_A_b16_1 : 49|1@1+ (1,0) [0|1] ""  External
 SG_ PB_17D_ActVehAccelV_A_b16_3 : 51|1@1+ (1,0) [0|1] ""  External
 SG_ PB_214_BkPDrvApPV_A_b16_4 : 52|1@1+ (1,0) [0|1] ""  External
 SG_ PB_1E9_BPDAPrsDetcdV_A_b16_5 : 53|1@1+ (1,0) [0|1] ""  External
 SG_ PB_34A_WhlGVLftNnDrvnV_A_b16_6 : 54|1@1+ (1,0) [0|1] ""  External
 SG_ PB_34A_WhlGVRtNnDrvnV_A_b16_7 : 55|1@1+ (1,0) [0|1] ""  External
 SG_ PB_17D_ABTCStMiss_A_b15_0 : 40|1@1+ (1,0) [0|1] ""  External
 SG_ PB_1E9_PPEIChsGSt1Miss_A_b15_2 : 42|1@1+ (1,0) [0|1] ""  External
 SG_ PB_214_BPDrvStMiss_A_b15_3 : 43|1@1+ (1,0) [0|1] ""  External
 SG_ PB_348_DrWhlGVelMiss_A_b15_4 : 44|1@1+ (1,0) [0|1] ""  External
 SG_ PB_34A_NDrWhlGVelMiss_A_b15_5 : 45|1@1+ (1,0) [0|1] ""  External
 SG_ PB_0C1_PPEIDrWhlRotMiss_A_b15_6 : 46|1@1+ (1,0) [0|1] ""  External
 SG_ PB_0C5_PPEINDrWhlRotMiss_A_b15_7 : 47|1@1+ (1,0) [0|1] ""  External
 SG_ PB_0C9_EngSpdStat_A_b14_0 : 32|1@1+ (1,0) [0|1] ""  External
 SG_ PB_1C4_AccPdlOvrrdAtvARC_A_b14_4 : 36|1@1+ (1,0) [0|1] ""  External
 SG_ PB_1C4_AutBrkAccActPsRC_A_b14_5 : 37|1@1+ (1,0) [0|1] ""  External
 SG_ PB_1C4_AccPdlOvAtvProtVal_A_b14_ : 38|1@1+ (1,0) [0|1] ""  External
 SG_ PB_1C4_AutBrkAccActPsPVal_A_b14_ : 39|1@1+ (1,0) [0|1] ""  External
 SG_ PB_2C3_EngTrqMinExtRngV_A_b13_0 : 24|1@1+ (1,0) [0|1] ""  External
 SG_ PB_0C9_PT_BPdDscrtInpStV_A_b13_1 : 25|1@1+ (1,0) [0|1] ""  External
 SG_ PB_1F5_TopTrvICltSwActV_A_b13_2 : 26|1@1+ (1,0) [0|1] ""  External
 SG_ PB_1F5_TransEstGearV_A_b13_3 : 27|1@1+ (1,0) [0|1] ""  External
 SG_ PB_1F5_TrnsEngdStateV_A_b13_4 : 28|1@1+ (1,0) [0|1] ""  External
 SG_ PB_3E9_VehSpdAvgDrvnV_A_b13_5 : 29|1@1+ (1,0) [0|1] ""  External
 SG_ PB_3E9_VehSpdAvgNDrvnV_A_b13_6 : 30|1@1+ (1,0) [0|1] ""  External
 SG_ PB_1C4_ACCATCS_RqStat_A_b13_7 : 31|1@1+ (1,0) [0|1] ""  External
 SG_ PB_4F3_PPEIPTCfg2Miss_A_b12_0 : 16|1@1+ (1,0) [0|1] ""  External
 SG_ PB_1C4_ABAAPS_AccPosV_A_b12_1 : 17|1@1+ (1,0) [0|1] ""  External
 SG_ PB_1C5_DrvIAxlTrqMaxV_A_b12_2 : 18|1@1+ (1,0) [0|1] ""  External
 SG_ PB_1C5_DrvIAxlTrqMinV_A_b12_3 : 19|1@1+ (1,0) [0|1] ""  External
 SG_ PB_1C5_DrvIntndAxlTrqV_A_b12_4 : 20|1@1+ (1,0) [0|1] ""  External
 SG_ PB_1C3_EngTrqActExtRngV_A_b12_5 : 21|1@1+ (1,0) [0|1] "" Vector__XXX
 SG_ PB_1C3_EngTqDrRqExtRngV_A_b12_6 : 22|1@1+ (1,0) [0|1] ""  External
 SG_ PB_2C3_EngTrqMaxExtRngV_A_b12_7 : 23|1@1+ (1,0) [0|1] ""  External
 SG_ PB_0C9_PPEIEngGSt1Miss_A_b11_0 : 8|1@1+ (1,0) [0|1] ""  External
 SG_ PB_1C3_PPEIEngTrqSt2Miss_A_b11_1 : 9|1@1+ (1,0) [0|1] ""  External
 SG_ PB_1C4_PPEITrqReqStMiss_A_b11_2 : 10|1@1+ (1,0) [0|1] ""  External
 SG_ PB_1C5_PPEIDrIAxTqStMiss_A_b11_3 : 11|1@1+ (1,0) [0|1] ""  External
 SG_ PB_1F5_PPEITrGenSt2Miss_A_b11_4 : 12|1@1+ (1,0) [0|1] ""  External
 SG_ PB_2C3_PPEIEngTrqSt3Miss_A_b11_5 : 13|1@1+ (1,0) [0|1] ""  External
 SG_ PB_3E9_PPEIVehSpdDisMiss_A_b11_6 : 14|1@1+ (1,0) [0|1] ""  External
 SG_ PB_4F1_PPEIPTConfMiss_A_b11_7 : 15|1@1+ (1,0) [0|1] ""  External
 SG_ MRRPCANIntComp_A_b10_0 : 0|1@1+ (1,0) [0|1] ""  External
 SG_ PCAN_330_IMULonAccSecAval_A_b10_ : 1|1@1+ (1,0) [0|1] ""  External
 SG_ PCAN_340_IMUYawRtSecAval_A_b10_2 : 2|1@1+ (1,0) [0|1] ""  External
 SG_ PCAN_340_IMULatAccSecAval_A_b10_ : 3|1@1+ (1,0) [0|1] ""  External
 SG_ PB_1E5_StrWhlAngSenTyp_A_b10_5 : 5|1@1+ (1,0) [0|1] ""  External

BO_ 513 Active_Fault_Byte_8_to_F: 8 IFV_CWMP
 SG_ FCMIndSTB_A_bF_0 : 56|1@1+ (1,0) [0|1] ""  External
 SG_ FCMIndSTGorOPN_A_bF_1 : 57|1@1+ (1,0) [0|1] ""  External
 SG_ LKASwtchSTG_A_bF_2 : 58|1@1+ (1,0) [0|1] ""  External
 SG_ MRRPCANMissingMsgHOST_A_bF_4 : 60|1@1+ (1,0) [0|1] ""  External
 SG_ MRRPCANMissingMsgVFP_A_bF_5 : 61|1@1+ (1,0) [0|1] ""  External
 SG_ MRRPCANRangeCheckVFP_A_bF_6 : 62|1@1+ (1,0) [0|1] ""  External
 SG_ MRRPCANInvalidDataVFP_A_bF_7 : 63|1@1+ (1,0) [0|1] ""  External
 SG_ VisionInternalError_A_bE_0 : 48|1@1+ (1,0) [0|1] ""  External
 SG_ VINMismatch_A_bE_1 : 49|1@1+ (1,0) [0|1] ""  External
 SG_ ECUSWCalDataSetNotProg_A_bE_2 : 50|1@1+ (1,0) [0|1] ""  External
 SG_ VehConfNotProg_A_bE_3 : 51|1@1+ (1,0) [0|1] ""  External
 SG_ VINNotProg_A_bE_4 : 52|1@1+ (1,0) [0|1] ""  External
 SG_ CameraCalNotLearnt_A_bE_5 : 53|1@1+ (1,0) [0|1] ""  External
 SG_ HostVCANBusOff_A_bE_6 : 54|1@1+ (1,0) [0|1] ""  External
 SG_ SysDisabledInfoStored_A_bE_7 : 55|1@1+ (1,0) [0|1] ""  External
 SG_ HostCoreSelftestFault_A_bD_0 : 40|1@1+ (1,0) [0|1] ""  External
 SG_ ECCSelfTestCheckFault_A_bD_1 : 41|1@1+ (1,0) [0|1] ""  External
 SG_ HostCoreExceptionFault_A_bD_2 : 42|1@1+ (1,0) [0|1] ""  External
 SG_ HostCtrConfigRegFault_A_bD_3 : 43|1@1+ (1,0) [0|1] ""  External
 SG_ HostADCSelfTestFault_A_bD_4 : 44|1@1+ (1,0) [0|1] ""  External
 SG_ HostADCMonitorFault_A_bD_5 : 45|1@1+ (1,0) [0|1] ""  External
 SG_ HostCVMResetFault_A_bD_6 : 46|1@1+ (1,0) [0|1] ""  External
 SG_ HostCVMSTsetFault_A_bD_7 : 47|1@1+ (1,0) [0|1] ""  External
 SG_ AlignAdjustIncorrect_A_bC_0 : 32|1@1+ (1,0) [0|1] ""  External
 SG_ VisionRadar_Missaligned_A_bC_1 : 33|1@1+ (1,0) [0|1] ""  External
 SG_ Vision_OutOfFocus_Fault_A_bC_2 : 34|1@1+ (1,0) [0|1] ""  External
 SG_ Vision_OutOfCalibration_A_bC_3 : 35|1@1+ (1,0) [0|1] ""  External
 SG_ HostISRConsistencyCheck_A_bC_5 : 37|1@1+ (1,0) [0|1] ""  External
 SG_ ECCSelfTest_CF_A_bC_6 : 38|1@1+ (1,0) [0|1] ""  External
 SG_ ECCSelfTest_RAM_A_bC_7 : 39|1@1+ (1,0) [0|1] ""  External
 SG_ Smeared_Spots_fault_A_bB_0 : 24|1@1+ (1,0) [0|1] ""  External
 SG_ SelfGlare_fault_A_bB_1 : 25|1@1+ (1,0) [0|1] ""  External
 SG_ Low_Visibility_fault_A_bB_2 : 26|1@1+ (1,0) [0|1] ""  External
 SG_ imager_pattern_fault_A_bB_4 : 28|1@1+ (1,0) [0|1] ""  External
 SG_ HostSWP2RAMCRCFlt_A_bB_5 : 29|1@1+ (1,0) [0|1] ""  External
 SG_ VisionAlignIncomplete_A_bB_6 : 30|1@1+ (1,0) [0|1] ""  External
 SG_ Full_Blockage_fault_A_bA_0 : 16|1@1+ (1,0) [0|1] ""  External
 SG_ Blurred_Image_fault_A_bA_1 : 17|1@1+ (1,0) [0|1] ""  External
 SG_ TD_Blockage_Fault_A_bA_2 : 18|1@1+ (1,0) [0|1] ""  External
 SG_ Splashes_fault_A_bA_3 : 19|1@1+ (1,0) [0|1] ""  External
 SG_ Low_Sun_fault_A_bA_4 : 20|1@1+ (1,0) [0|1] ""  External
 SG_ Sun_Rays_faults_A_bA_5 : 21|1@1+ (1,0) [0|1] ""  External
 SG_ Foggy_Spots_fault_A_bA_6 : 22|1@1+ (1,0) [0|1] ""  External
 SG_ Spot_Rays_fault_A_bA_7 : 23|1@1+ (1,0) [0|1] ""  External
 SG_ HostPLLStoppedFault_A_b9_0 : 8|1@1+ (1,0) [0|1] ""  External
 SG_ HostWatchDogSelftestFault_A_b9_1 : 9|1@1+ (1,0) [0|1] ""  External
 SG_ VfpCamMalFunc_A_b9_2 : 10|1@1+ (1,0) [0|1] ""  External
 SG_ VfpCamCtrlFlt_A_b9_3 : 11|1@1+ (1,0) [0|1] ""  External
 SG_ VfpCamVdoFlt_A_b9_5 : 13|1@1+ (1,0) [0|1] ""  External
 SG_ Partial_Blockage_fault_A_b9_7 : 15|1@1+ (1,0) [0|1] ""  External
 SG_ CMBB_ACC_ValFault_A_b8_2 : 2|1@1+ (1,0) [0|1] ""  External
 SG_ HostSWResetMismatchFault_A_b8_3 : 3|1@1+ (1,0) [0|1] ""  External
 SG_ CAN_BDU_Msg_Invalid_A_b8_4 : 4|1@1+ (1,0) [0|1] ""  External
 SG_ HostCSIHPeripheralFault_A_b8_5 : 5|1@1+ (1,0) [0|1] ""  External
 SG_ HostCANPeripheralFault_A_b8_6 : 6|1@1+ (1,0) [0|1] ""  External
 SG_ HostHighSpdOscStopFault_A_b8_7 : 7|1@1+ (1,0) [0|1] ""  External

BO_ 512 Active_Fault_Byte_0_to_7: 8 IFV_CWMP
 SG_ grab_issue_failure_A_b7_0 : 56|1@1+ (1,0) [0|1] ""  External
 SG_ grab_acquire_failure_A_b7_1 : 57|1@1+ (1,0) [0|1] ""  External
 SG_ grab_release_failure_A_b7_2 : 58|1@1+ (1,0) [0|1] ""  External
 SG_ VFP_subsystem_comm_fault_A_b7_3 : 59|1@1+ (1,0) [0|1] ""  External
 SG_ parameters_invalid_A_b7_4 : 60|1@1+ (1,0) [0|1] ""  External
 SG_ ThermistorOutOfRange_A_b7_5 : 61|1@1+ (1,0) [0|1] ""  External
 SG_ BatteryHighFault_Act_A_b7_6 : 62|1@1+ (1,0) [0|1] ""  External
 SG_ BatteryLowFault_Act_A_b7_7 : 63|1@1+ (1,0) [0|1] ""  External
 SG_ VFPCoreDumpFault_A_b6_0 : 48|1@1+ (1,0) [0|1] ""  External
 SG_ DDROverTemp_A_b6_1 : 49|1@1+ (1,0) [0|1] ""  External
 SG_ BusOffPCAN_A_b6_3 : 51|1@1+ (1,0) [0|1] ""  External
 SG_ init_vdi_failure_A_b6_5 : 53|1@1+ (1,0) [0|1] ""  External
 SG_ init_I2C_failure_A_b6_6 : 54|1@1+ (1,0) [0|1] ""  External
 SG_ grab_no_free_header_failure_A_b6 : 55|1@1+ (1,0) [0|1] ""  External
 SG_ HostSpiCRC_A_b5_0 : 40|1@1+ (1,0) [0|1] ""  External
 SG_ VFPSpiFrameFormatError_A_b5_1 : 41|1@1+ (1,0) [0|1] ""  External
 SG_ VFPSpiMsgFormatError_A_b5_2 : 42|1@1+ (1,0) [0|1] ""  External
 SG_ VFPSpiMsgTimeout_A_b5_3 : 43|1@1+ (1,0) [0|1] ""  External
 SG_ VFPModeFault_A_b5_4 : 44|1@1+ (1,0) [0|1] ""  External
 SG_ VFPSpiCRC_A_b5_5 : 45|1@1+ (1,0) [0|1] ""  External
 SG_ SpiIpcCommReset_A_b5_6 : 46|1@1+ (1,0) [0|1] ""  External
 SG_ VFPInitTimeout_A_b5_7 : 47|1@1+ (1,0) [0|1] ""  External
 SG_ v2_8_ImagerInterfaceFault_A_b4_0 : 32|1@1+ (1,0) [0|1] ""  External
 SG_ v1_8_SupplyOutOfRangeFault_A_b4_ : 33|1@1+ (1,0) [0|1] ""  External
 SG_ v1_2_SupplyOutOfRangeFault_A_b4_ : 34|1@1+ (1,0) [0|1] ""  External
 SG_ HostSpiFrameFormatError_A_b4_3 : 35|1@1+ (1,0) [0|1] ""  External
 SG_ HostSpiMsgFormatError_A_b4_4 : 36|1@1+ (1,0) [0|1] ""  External
 SG_ HostSpiMsgTimeout_A_b4_5 : 37|1@1+ (1,0) [0|1] ""  External
 SG_ SPIVersionMismatch_A_b4_6 : 38|1@1+ (1,0) [0|1] ""  External
 SG_ HostSpiTxError_A_b4_7 : 39|1@1+ (1,0) [0|1] ""  External
 SG_ VFPBootOverTemp_A_b3_0 : 24|1@1+ (1,0) [0|1] ""  External
 SG_ HostRAMECC_A_b3_1 : 25|1@1+ (1,0) [0|1] ""  External
 SG_ HostInstructionSetCheckFault_A_b : 26|1@1+ (1,0) [0|1] ""  External
 SG_ VfpBistMemRFlt_A_b3_3 : 27|1@1+ (1,0) [0|1] ""  External
 SG_ HostOscillatorStopped_A_b3_4 : 28|1@1+ (1,0) [0|1] ""  External
 SG_ HostStackOverflowFault_A_b3_5 : 29|1@1+ (1,0) [0|1] ""  External
 SG_ HostCOPFault_A_b3_6 : 30|1@1+ (1,0) [0|1] ""  External
 SG_ v5_0_SupplyOutOfRangeFault_A_b3_ : 31|1@1+ (1,0) [0|1] ""  External
 SG_ VfpDDRFlt_A_b2_0 : 16|1@1+ (1,0) [0|1] ""  External
 SG_ DdrRamCrc_A_b2_1 : 17|1@1+ (1,0) [0|1] ""  External
 SG_ VfpBootFlt_A_b2_2 : 18|1@1+ (1,0) [0|1] ""  External
 SG_ VfpCoreFlt_A_b2_3 : 19|1@1+ (1,0) [0|1] ""  External
 SG_ HostCodeFlashECC_A_b2_4 : 20|1@1+ (1,0) [0|1] ""  External
 SG_ HostDataFlashECC_A_b2_5 : 21|1@1+ (1,0) [0|1] ""  External
 SG_ SerialFlashPowerUpFail_A_b2_6 : 22|1@1+ (1,0) [0|1] ""  External
 SG_ HostRamFault_A_b2_7 : 23|1@1+ (1,0) [0|1] ""  External
 SG_ KAMChecksumFault_A_b1_0 : 8|1@1+ (1,0) [0|1] ""  External
 SG_ HostApplicationCRC_A_b1_1 : 9|1@1+ (1,0) [0|1] ""  External
 SG_ HostCalibrationCRC_A_b1_2 : 10|1@1+ (1,0) [0|1] ""  External
 SG_ VFPApplicationChecksum_A_b1_3 : 11|1@1+ (1,0) [0|1] ""  External
 SG_ VFPCalibrationChecksum_A_b1_4 : 12|1@1+ (1,0) [0|1] ""  External
 SG_ HostCalComplAndCompat_A_b1_5 : 13|1@1+ (1,0) [0|1] ""  External
 SG_ VFPAppComplAndCompat_A_b1_6 : 14|1@1+ (1,0) [0|1] ""  External
 SG_ InvalidAHBCSensParams_A_b1_7 : 15|1@1+ (1,0) [0|1] ""  External
 SG_ VFPCalComplCompatSWP3_A_b0_1 : 1|1@1+ (1,0) [0|1] ""  External
 SG_ VFPCalComplCompatSWP5_A_b0_2 : 2|1@1+ (1,0) [0|1] ""  External
 SG_ SystemOverTemperature_A_b0_3 : 3|1@1+ (1,0) [0|1] ""  External
 SG_ OnBdThermOvrTemp_A_b0_4 : 4|1@1+ (1,0) [0|1] ""  External
 SG_ VFPMIPSOverTemp_A_b0_5 : 5|1@1+ (1,0) [0|1] ""  External
 SG_ VFPVMPOverTemp_A_b0_6 : 6|1@1+ (1,0) [0|1] ""  External
 SG_ VFPImagerOverTemp_A_b0_7 : 7|1@1+ (1,0) [0|1] ""  External

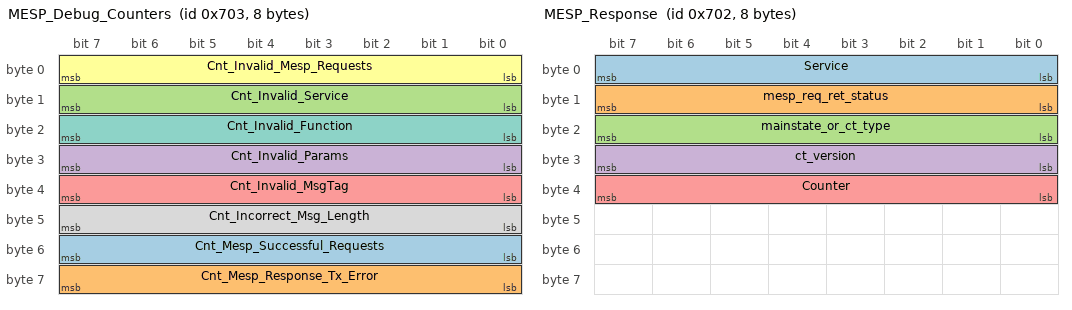
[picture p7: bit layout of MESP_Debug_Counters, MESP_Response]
BO_ 1795 MESP_Debug_Counters: 8 IFV_VFP
 SG_ Cnt_Mesp_Successful_Requests : 48|8@1+ (1,0) [0|255] ""  External
 SG_ Cnt_Mesp_Response_Tx_Error : 56|8@1+ (1,0) [0|255] ""  External
 SG_ Cnt_Invalid_Service : 8|8@1+ (1,0) [0|255] ""  External
 SG_ Cnt_Invalid_Params : 24|8@1+ (1,0) [0|255] ""  External
 SG_ Cnt_Invalid_MsgTag : 32|8@1+ (1,0) [0|255] ""  External
 SG_ Cnt_Invalid_Mesp_Requests : 0|8@1+ (1,0) [0|255] ""  External
 SG_ Cnt_Invalid_Function : 16|8@1+ (1,0) [0|255] ""  External
 SG_ Cnt_Incorrect_Msg_Length : 40|8@1+ (1,0) [0|255] ""  External

BO_ 1794 MESP_Response: 8 IFV_VFP
 SG_ Service : 0|8@1+ (1,0) [0|255] ""  External
 SG_ mesp_req_ret_status : 8|8@1+ (1,0) [0|255] ""  External
 SG_ mainstate_or_ct_type : 16|8@1+ (1,0) [0|255] ""  External
 SG_ ct_version : 24|8@1+ (1,0) [0|255] ""  External
 SG_ Counter : 32|8@1+ (1,0) [0|255] ""  External

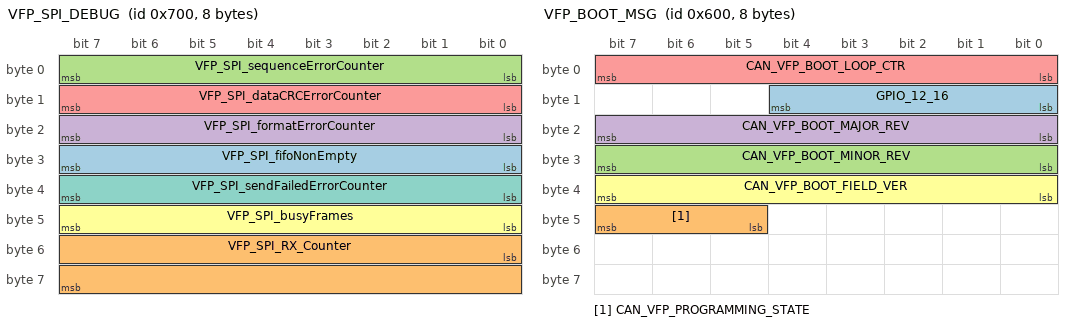
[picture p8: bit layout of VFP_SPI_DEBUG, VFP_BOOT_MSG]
BO_ 1792 VFP_SPI_DEBUG: 8 IFV_VFP
 SG_ VFP_SPI_fifoNonEmpty : 24|8@1+ (1,0) [0|255] ""  External
 SG_ VFP_SPI_RX_Counter : 48|16@1+ (1,0) [0|65535] ""  External
 SG_ VFP_SPI_sequenceErrorCounter : 0|8@1+ (1,0) [0|255] ""  External
 SG_ VFP_SPI_formatErrorCounter : 16|8@1+ (1,0) [0|255] ""  External
 SG_ VFP_SPI_dataCRCErrorCounter : 8|8@1+ (1,0) [0|255] ""  External
 SG_ VFP_SPI_busyFrames : 40|8@1+ (1,0) [0|255] ""  External
 SG_ VFP_SPI_sendFailedErrorCounter : 32|8@1+ (1,0) [0|255] ""  External

BO_ 1536 VFP_BOOT_MSG: 8 IFV_VFP
 SG_ GPIO_12_16 : 8|5@1+ (1,0) [0|31] ""  External
 SG_ CAN_VFP_PROGRAMMING_STATE : 45|3@1+ (1,0) [0|7] ""  External
 SG_ CAN_VFP_BOOT_MINOR_REV : 24|8@1+ (1,0) [0|255] ""  External
 SG_ CAN_VFP_BOOT_MAJOR_REV : 16|8@1+ (1,0) [0|255] ""  External
 SG_ CAN_VFP_BOOT_LOOP_CTR : 0|8@1+ (1,0) [0|255] ""  External
 SG_ CAN_VFP_BOOT_FIELD_VER : 32|8@1+ (1,0) [0|255] ""  External

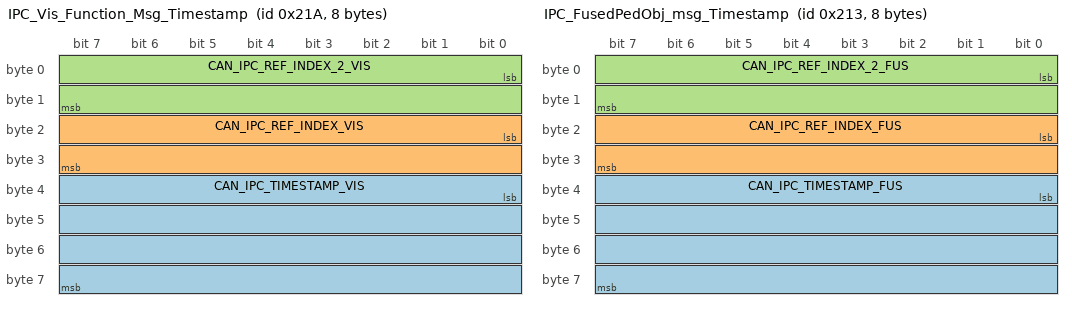
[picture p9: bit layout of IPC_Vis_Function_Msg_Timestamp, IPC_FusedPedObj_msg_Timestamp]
BO_ 538 IPC_Vis_Function_Msg_Timestamp: 8 IFV_VFP
 SG_ CAN_IPC_TIMESTAMP_VIS : 32|32@1+ (1,0) [0|4294967295] "ms"  External
 SG_ CAN_IPC_REF_INDEX_VIS : 16|16@1+ (1,0) [0|65535] ""  External
 SG_ CAN_IPC_REF_INDEX_2_VIS : 0|16@1+ (1,0) [0|65535] ""  External

BO_ 531 IPC_FusedPedObj_msg_Timestamp: 8 IFV_VFP
 SG_ CAN_IPC_TIMESTAMP_FUS : 32|32@1+ (1,0) [0|4294967295] "ms"  External
 SG_ CAN_IPC_REF_INDEX_FUS : 16|16@1+ (1,0) [0|65535] ""  External
 SG_ CAN_IPC_REF_INDEX_2_FUS : 0|16@1+ (1,0) [0|65535] ""  External

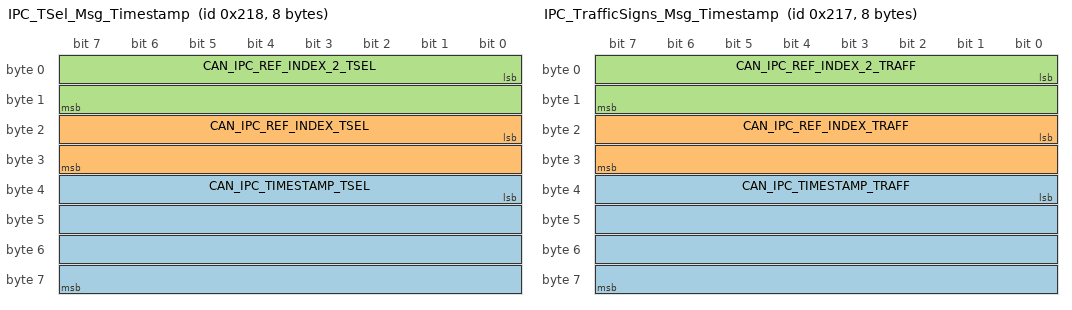
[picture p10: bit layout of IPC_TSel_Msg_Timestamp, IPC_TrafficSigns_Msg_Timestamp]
BO_ 536 IPC_TSel_Msg_Timestamp: 8 IFV_VFP
 SG_ CAN_IPC_TIMESTAMP_TSEL : 32|32@1+ (1,0) [0|4294967295] "ms"  External
 SG_ CAN_IPC_REF_INDEX_TSEL : 16|16@1+ (1,0) [0|65535] ""  External
 SG_ CAN_IPC_REF_INDEX_2_TSEL : 0|16@1+ (1,0) [0|65535] ""  External

BO_ 533 IPC_Objects_Msg_Timestamp: 8 IFV_VFP
 SG_ CAN_IPC_TIMESTAMP_OBJ : 32|32@1+ (1,0) [0|4294967295] "ms"  External
 SG_ CAN_IPC_REF_INDEX_OBJ : 16|16@1+ (1,0) [0|65535] ""  External

BO_ 535 IPC_TrafficSigns_Msg_Timestamp: 8 IFV_VFP
 SG_ CAN_IPC_TIMESTAMP_TRAFF : 32|32@1+ (1,0) [0|4294967295] "ms"  External
 SG_ CAN_IPC_REF_INDEX_TRAFF : 16|16@1+ (1,0) [0|65535] ""  External
 SG_ CAN_IPC_REF_INDEX_2_TRAFF : 0|16@1+ (1,0) [0|65535] ""  External

BO_ 532 IPC_LightSenData_Msg_Timestamp: 8 IFV_VFP
 SG_ CAN_IPC_TIMESTAMP_LIGHT : 32|32@1+ (1,0) [0|4294967295] "ms"  External
 SG_ CAN_IPC_REF_INDEX_LIGHT : 16|16@1+ (1,0) [0|65535] ""  External

BO_ 534 IPC_RoadData_Msg_Timestamp: 8 IFV_VFP
 SG_ CAN_IPC_TIMESTAMP_ROAD : 32|32@1+ (1,0) [0|4294967295] "ms"  External
 SG_ CAN_IPC_REF_INDEX_ROAD : 16|16@1+ (1,0) [0|65535] ""  External

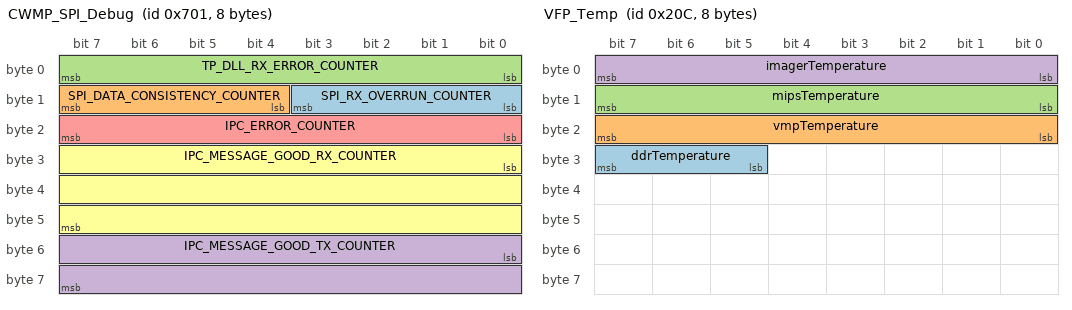
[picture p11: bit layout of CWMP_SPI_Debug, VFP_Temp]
BO_ 1793 CWMP_SPI_Debug: 8 IFV_CWMP
 SG_ SPI_RX_OVERRUN_COUNTER : 8|4@1+ (1,0) [0|15] ""  External
 SG_ SPI_DATA_CONSISTENCY_COUNTER : 12|4@1+ (1,0) [0|15] ""  External
 SG_ TP_DLL_RX_ERROR_COUNTER : 0|8@1+ (1,0) [0|255] ""  External
 SG_ IPC_MESSAGE_GOOD_TX_COUNTER : 48|16@1+ (1,0) [0|65535] ""  External
 SG_ IPC_ERROR_COUNTER : 16|8@1+ (1,0) [0|255] ""  External
 SG_ IPC_MESSAGE_GOOD_RX_COUNTER : 24|24@1+ (1,0) [0|16777215] ""  External

BO_ 523 VFP_SW_Version: 8 IFV_VFP
 SG_ CAN_VFP_SW_PATCH_REV : 16|8@1+ (1,0) [0|153] ""  External
 SG_ CAN_VFP_SW_MINOR_REV : 8|8@1+ (1,0) [0|153] ""  External
 SG_ CAN_VFP_SW_MAJOR_REV : 0|8@1+ (1,0) [0|153] ""  External

BO_ 524 VFP_Temp: 8 IFV_CWMP
 SG_ ddrTemperature : 29|3@1+ (1,0) [0|7] "C"  External
 SG_ vmpTemperature : 16|8@1- (1,0) [-55|127] "C"  External
 SG_ mipsTemperature : 8|8@1- (1,0) [-40|125] "C"  External
 SG_ imagerTemperature : 0|8@1- (1,0) [-55|127] "C"  External

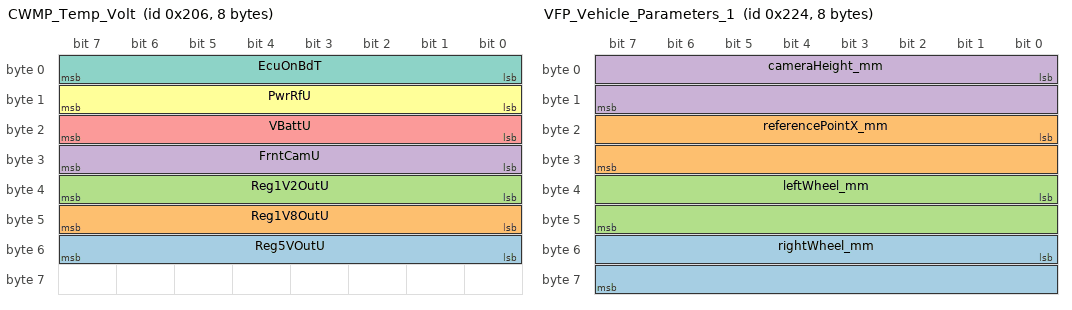
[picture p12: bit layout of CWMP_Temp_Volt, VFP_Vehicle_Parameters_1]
BO_ 518 CWMP_Temp_Volt: 8 IFV_CWMP
 SG_ Reg5VOutU : 48|8@1+ (0.08,0) [0|20.4] "V"  External
 SG_ Reg1V8OutU : 40|8@1+ (0.08,0) [0|20.4] "V"  External
 SG_ Reg1V2OutU : 32|8@1+ (0.08,0) [0|20.4] "V"  External
 SG_ FrntCamU : 24|8@1+ (0.08,0) [0|20.4] "V"  External
 SG_ VBattU : 16|8@1+ (0.08,0) [0|20.4] "V"  External
 SG_ PwrRfU : 8|8@1+ (0.08,0) [0|20.4] "V"  External
 SG_ EcuOnBdT : 0|8@1- (1,0) [-40|125] "C"  External

BO_ 542 VFP_Vision_Trigger_Timestamp: 8 Vector__XXX
 SG_ CAN_VISION_TRIGGER_TIMESTAMP : 32|32@1+ (1,0) [0|4294967295] "ms" Vector__XXX
 SG_ CAN_CAMERA_IMAGE_INDEX_VFP : 0|16@1+ (1,0) [0|65535] "" Vector__XXX

BO_ 544 VFP_Alignment_Data_Msg1: 8 IFV_VFP
 SG_ Vision_VFP_Mode : 8|3@1+ (1,0) [0|7] ""  External
 SG_ Internal_VFP_mode : 0|2@1+ (1,0) [0|3] ""  External

BO_ 549 VFP_Vehicle_Parameters_2: 8 IFV_VFP
 SG_ topOffsetAngle : 0|32@1+ (1.52587890625E-005,0.14) [0.14|0.27] "radians"  External
 SG_ bottomOffsetAngle : 32|32@1+ (1.52587890625E-005,0) [0|0.35] "rad"  External

BO_ 548 VFP_Vehicle_Parameters_1: 8 IFV_VFP
 SG_ rightWheel_mm : 48|16@1+ (1,0) [0|65535] "mm"  External
 SG_ referencePointX_mm : 16|16@1+ (1,0) [0|65535] "mm"  External
 SG_ leftWheel_mm : 32|16@1+ (1,0) [0|65535] "mm"  External
 SG_ cameraHeight_mm : 0|16@1+ (1,0) [0|65535] "mm"  External

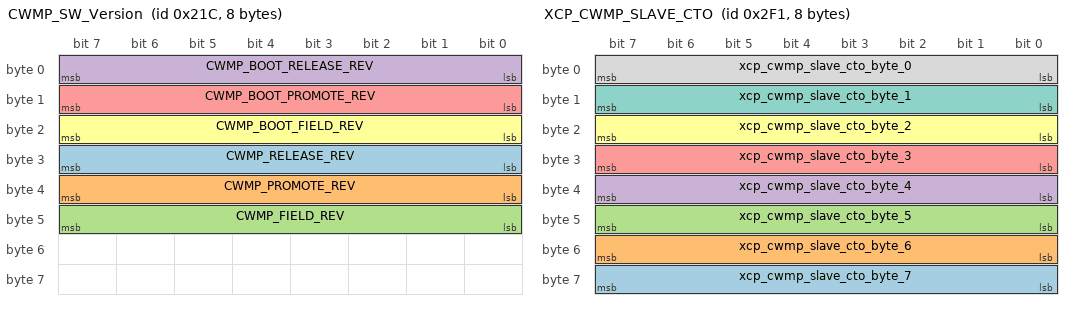
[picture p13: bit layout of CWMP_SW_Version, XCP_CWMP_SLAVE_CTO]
BO_ 540 CWMP_SW_Version: 8 IFV_CWMP
 SG_ CWMP_RELEASE_REV : 24|8@1+ (1,0) [0|255] ""  External
 SG_ CWMP_PROMOTE_REV : 32|8@1+ (1,0) [0|255] ""  External
 SG_ CWMP_FIELD_REV : 40|8@1+ (1,0) [0|255] ""  External
 SG_ CWMP_BOOT_RELEASE_REV : 0|8@1+ (1,0) [0|255] ""  External
 SG_ CWMP_BOOT_PROMOTE_REV : 8|8@1+ (1,0) [0|255] ""  External
 SG_ CWMP_BOOT_FIELD_REV : 16|8@1+ (1,0) [0|255] ""  External

BO_ 1029 Camera_VSYNC_CWMP_Timestamp: 8 Vector__XXX
 SG_ CAN_CAMERA_IMAGE_TIMESTAMP_CWMP : 16|32@1+ (1,0) [0|4294967295] "ms" Vector__XXX
 SG_ CAN_CAMERA_IMAGE_INDEX_CWMP : 0|16@1+ (1,0) [0|65535] "" Vector__XXX

BO_ 753 XCP_CWMP_SLAVE_CTO: 8 IFV_CWMP
 SG_ xcp_cwmp_slave_cto_byte_7 : 63|8@0+ (1,0) [0|255] ""  External
 SG_ xcp_cwmp_slave_cto_byte_6 : 55|8@0+ (1,0) [0|255] ""  External
 SG_ xcp_cwmp_slave_cto_byte_5 : 47|8@0+ (1,0) [0|255] ""  External
 SG_ xcp_cwmp_slave_cto_byte_4 : 39|8@0+ (1,0) [0|255] ""  External
 SG_ xcp_cwmp_slave_cto_byte_3 : 31|8@0+ (1,0) [0|255] ""  External
 SG_ xcp_cwmp_slave_cto_byte_2 : 23|8@0+ (1,0) [0|255] ""  External
 SG_ xcp_cwmp_slave_cto_byte_1 : 15|8@0+ (1,0) [0|255] ""  External
 SG_ xcp_cwmp_slave_cto_byte_0 : 7|8@0+ (1,0) [0|255] ""  External

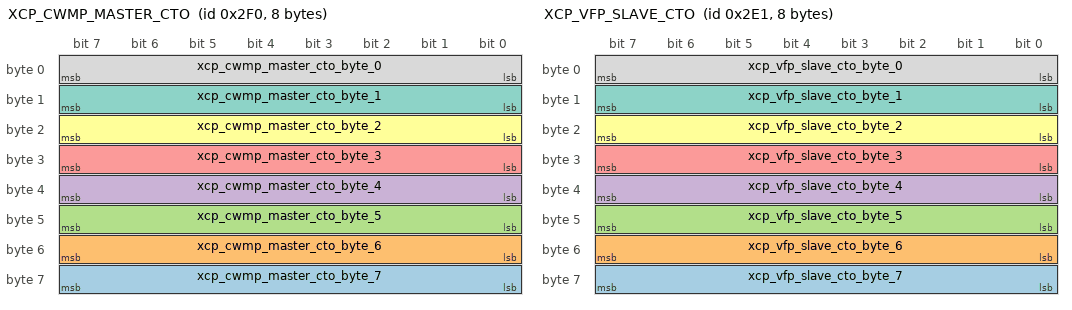
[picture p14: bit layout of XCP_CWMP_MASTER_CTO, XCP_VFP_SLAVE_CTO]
BO_ 752 XCP_CWMP_MASTER_CTO: 8 External
 SG_ xcp_cwmp_master_cto_byte_7 : 63|8@0+ (1,0) [0|255] ""  External,IFV_CWMP
 SG_ xcp_cwmp_master_cto_byte_6 : 55|8@0+ (1,0) [0|255] ""  External,IFV_CWMP
 SG_ xcp_cwmp_master_cto_byte_5 : 47|8@0+ (1,0) [0|255] ""  External,IFV_CWMP
 SG_ xcp_cwmp_master_cto_byte_4 : 39|8@0+ (1,0) [0|255] ""  External,IFV_CWMP
 SG_ xcp_cwmp_master_cto_byte_3 : 31|8@0+ (1,0) [0|255] ""  External,IFV_CWMP
 SG_ xcp_cwmp_master_cto_byte_2 : 23|8@0+ (1,0) [0|255] ""  External,IFV_CWMP
 SG_ xcp_cwmp_master_cto_byte_1 : 15|8@0+ (1,0) [0|255] ""  External,IFV_CWMP
 SG_ xcp_cwmp_master_cto_byte_0 : 7|8@0+ (1,0) [0|255] ""  External,IFV_CWMP

BO_ 737 XCP_VFP_SLAVE_CTO: 8 IFV_VFP
 SG_ xcp_vfp_slave_cto_byte_7 : 63|8@0+ (1,0) [0|255] ""  External
 SG_ xcp_vfp_slave_cto_byte_6 : 55|8@0+ (1,0) [0|255] ""  External
 SG_ xcp_vfp_slave_cto_byte_5 : 47|8@0+ (1,0) [0|255] ""  External
 SG_ xcp_vfp_slave_cto_byte_4 : 39|8@0+ (1,0) [0|255] ""  External
 SG_ xcp_vfp_slave_cto_byte_3 : 31|8@0+ (1,0) [0|255] ""  External
 SG_ xcp_vfp_slave_cto_byte_2 : 23|8@0+ (1,0) [0|255] ""  External
 SG_ xcp_vfp_slave_cto_byte_1 : 15|8@0+ (1,0) [0|255] ""  External
 SG_ xcp_vfp_slave_cto_byte_0 : 7|8@0+ (1,0) [0|255] ""  External

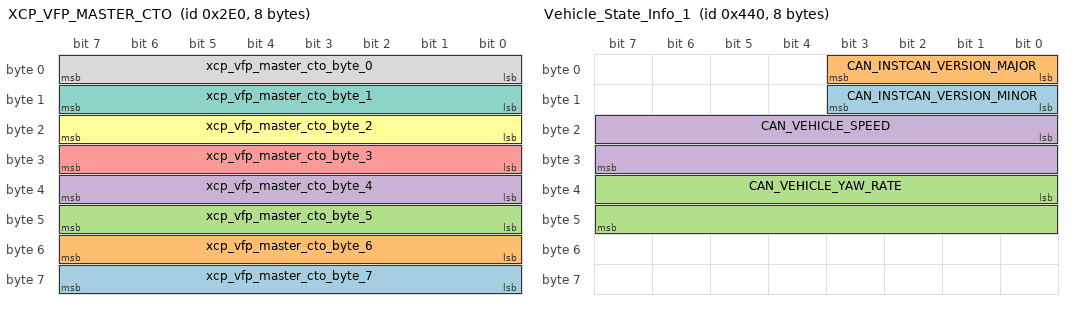
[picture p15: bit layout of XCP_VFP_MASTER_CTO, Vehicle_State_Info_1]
BO_ 736 XCP_VFP_MASTER_CTO: 8 External
 SG_ xcp_vfp_master_cto_byte_7 : 63|8@0+ (1,0) [0|255] ""  External,IFV_VFP
 SG_ xcp_vfp_master_cto_byte_6 : 55|8@0+ (1,0) [0|255] ""  External,IFV_VFP
 SG_ xcp_vfp_master_cto_byte_5 : 47|8@0+ (1,0) [0|255] ""  External,IFV_VFP
 SG_ xcp_vfp_master_cto_byte_4 : 39|8@0+ (1,0) [0|255] ""  External,IFV_VFP
 SG_ xcp_vfp_master_cto_byte_3 : 31|8@0+ (1,0) [0|255] ""  External,IFV_VFP
 SG_ xcp_vfp_master_cto_byte_2 : 23|8@0+ (1,0) [0|255] ""  External,IFV_VFP
 SG_ xcp_vfp_master_cto_byte_1 : 15|8@0+ (1,0) [0|255] ""  External,IFV_VFP
 SG_ xcp_vfp_master_cto_byte_0 : 7|8@0+ (1,0) [0|255] ""  External,IFV_VFP

BO_ 1088 Vehicle_State_Info_1: 8 IFV_VFP
 SG_ CAN_INSTCAN_VERSION_MINOR : 8|4@1+ (1,0) [0|15] ""  External
 SG_ CAN_INSTCAN_VERSION_MAJOR : 0|4@1+ (1,0) [0|15] ""  External
 SG_ CAN_VEHICLE_YAW_RATE : 32|16@1- (0.0001220703125,0) [-4|3.9998779297] "rad/s"  External
 SG_ CAN_VEHICLE_SPEED : 16|16@1- (0.0078125,0) [-256|255.9921875] "m/s"  External

BO_ 517 CWMP_Cycle_Msg: 8 IFV_CWMP
 SG_ CWMP_CPU_IDLE_TIME : 32|16@1+ (1,0) [0|65535] "usec"  External
 SG_ CAN_CWMP_CYCLE_INDEX_CYCLE : 0|16@1+ (1,0) [0|65535] ""  External
 SG_ CAN_CAMERA_IMAGE_INDEX_USED : 16|16@1+ (1,0) [0|65535] ""  External

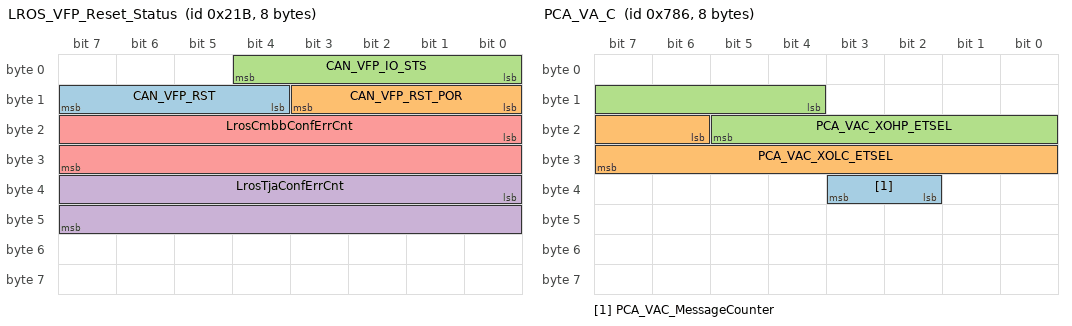
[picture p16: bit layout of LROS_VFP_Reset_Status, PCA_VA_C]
BO_ 539 LROS_VFP_Reset_Status: 8 IFV_CWMP
 SG_ CAN_VFP_RST : 12|4@1+ (1,0) [0|1] ""  External
 SG_ CAN_VFP_RST_POR : 8|4@1+ (1,0) [0|1] ""  External
 SG_ CAN_VFP_IO_STS : 0|5@1+ (1,0) [0|31] ""  External
 SG_ LrosTjaConfErrCnt : 32|16@1+ (1,0) [0|65535] ""  External
 SG_ LrosCmbbConfErrCnt : 16|16@1+ (1,0) [0|65535] ""  External

BO_ 1028 Camera_VSYNC_Timestamp: 8 Vector__XXX
 SG_ CAN_CAMERA_IMAGE_TIMESTAMP_SYNC : 16|32@1+ (1,0) [0|4294967295] "ms" Vector__XXX
 SG_ CAN_CAMERA_IMAGE_INDEX_SYNC : 0|16@1+ (1,0) [0|65535] "" Vector__XXX

BO_ 1024 VFP_CWMP_SYNC_Timestamps: 8 IFV_VFP
 SG_ CAN_VFP_TIMESTAMP : 32|32@1+ (1,0) [0|4294967295] "ms"  External
 SG_ CAN_CWMP_TIMESTAMP : 0|32@1+ (1,0) [0|4294967295] "ms"  External

BO_ 1926 PCA_VA_C: 8 IFV_CWMP
 SG_ PCA_VAC_MessageCounter : 34|2@1+ (1,0) [0|3] ""  External
 SG_ PCA_VAC_XOLC_ETSEL : 22|10@1+ (0.1,-50) [-50|50] "m"  External
 SG_ PCA_VAC_XOHP_ETSEL : 12|10@1+ (0.1,-50) [-50|50] "m"  External

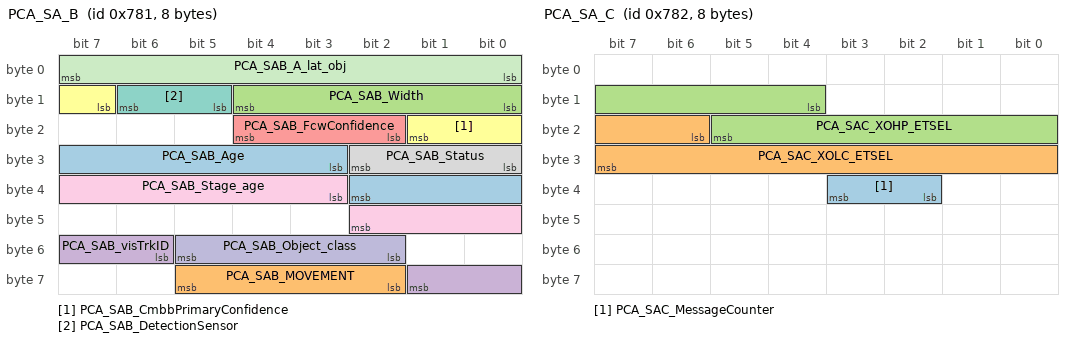
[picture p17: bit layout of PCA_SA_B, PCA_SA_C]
BO_ 1921 PCA_SA_B: 8 IFV_CWMP
 SG_ PCA_SAB_Age : 27|8@1+ (1,0) [0|255] ""  External
 SG_ PCA_SAB_MOVEMENT : 58|4@1+ (1,0) [0|15] ""  External
 SG_ PCA_SAB_Width : 8|5@1+ (0.1,0) [0|3] "m"  External
 SG_ PCA_SAB_visTrkID : 54|4@1+ (1,0) [0|15] ""  External
 SG_ PCA_SAB_FcwConfidence : 18|3@1+ (1,0) [0|1] ""  External
 SG_ PCA_SAB_CmbbPrimaryConfidence : 15|3@1+ (1,0) [0|3] ""  External
 SG_ PCA_SAB_DetectionSensor : 13|2@1+ (1,0) [0|3] ""  External
 SG_ PCA_SAB_Status : 24|3@1+ (1,0) [0|7] ""  External
 SG_ PCA_SAB_Stage_age : 35|8@1+ (1,0) [0|255] ""  External
 SG_ PCA_SAB_Object_class : 50|4@1+ (1,0) [0|10] ""  External
 SG_ PCA_SAB_A_lat_obj : 0|8@1+ (0.1,-10) [-10|10] "m/s^2"  External

BO_ 1922 PCA_SA_C: 8 IFV_CWMP
 SG_ PCA_SAC_MessageCounter : 34|2@1+ (1,0) [0|3] ""  External
 SG_ PCA_SAC_XOLC_ETSEL : 22|10@1+ (0.1,-50) [-50|50] "m"  External
 SG_ PCA_SAC_XOHP_ETSEL : 12|10@1+ (0.1,-50) [-50|50] "m"  External

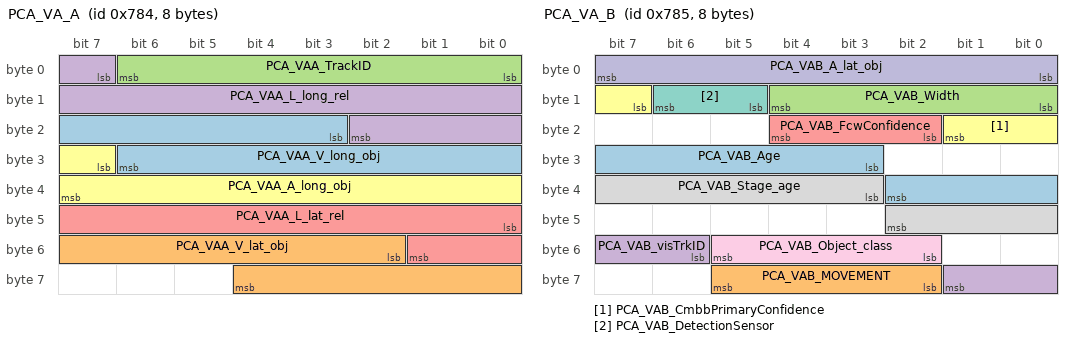
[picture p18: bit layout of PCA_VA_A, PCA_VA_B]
BO_ 1924 PCA_VA_A: 8 IFV_CWMP
 SG_ PCA_VAA_V_long_obj : 19|12@1+ (0.05,-100) [-100|100] "m/s"  External
 SG_ PCA_VAA_V_lat_obj : 50|11@1+ (0.025,-20) [-20|20] "m/s"  External
 SG_ PCA_VAA_TrackID : 0|7@1+ (1,0) [0|64] ""  External
 SG_ PCA_VAA_L_long_rel : 7|12@1+ (0.1,0) [0|180] "m"  External
 SG_ PCA_VAA_L_lat_rel : 40|10@1+ (0.1,-50) [-50|50] "m"  External
 SG_ PCA_VAA_A_long_obj : 31|9@1+ (0.1,-12.5) [-12.5|12.5] "m/s^2"  External

BO_ 1925 PCA_VA_B: 8 IFV_CWMP
 SG_ PCA_VAB_Age : 27|8@1+ (1,0) [0|255] ""  External
 SG_ PCA_VAB_MOVEMENT : 58|4@1+ (1,0) [0|15] ""  External
 SG_ PCA_VAB_Width : 8|5@1+ (0.1,0) [0|3] "m"  External
 SG_ PCA_VAB_visTrkID : 54|4@1+ (1,0) [0|15] ""  External
 SG_ PCA_VAB_FcwConfidence : 18|3@1+ (1,0) [0|1] ""  External
 SG_ PCA_VAB_CmbbPrimaryConfidence : 15|3@1+ (1,0) [0|3] ""  External
 SG_ PCA_VAB_DetectionSensor : 13|2@1+ (1,0) [0|3] ""  External
 SG_ PCA_VAB_Stage_age : 35|8@1+ (1,0) [0|255] ""  External
 SG_ PCA_VAB_Object_class : 50|4@1+ (1,0) [0|10] ""  External
 SG_ PCA_VAB_A_lat_obj : 0|8@1+ (0.1,-10) [-10|10] "m/s^2"  External

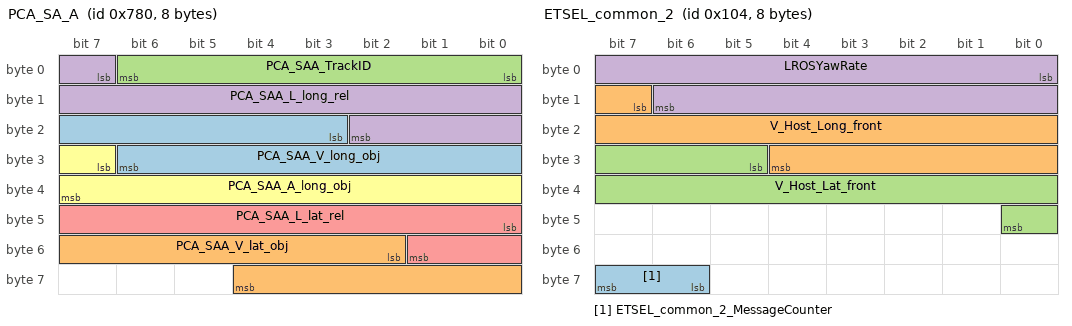
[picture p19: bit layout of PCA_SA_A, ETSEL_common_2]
BO_ 1920 PCA_SA_A: 8 IFV_CWMP
 SG_ PCA_SAA_V_long_obj : 19|12@1+ (0.05,-100) [-100|100] "m/s"  External
 SG_ PCA_SAA_V_lat_obj : 50|11@1+ (0.025,-20) [-20|20] "m/s"  External
 SG_ PCA_SAA_TrackID : 0|7@1+ (1,0) [0|64] ""  External
 SG_ PCA_SAA_L_long_rel : 7|12@1+ (0.1,0) [0|180] "m"  External
 SG_ PCA_SAA_L_lat_rel : 40|10@1+ (0.1,-50) [-50|50] "m"  External
 SG_ PCA_SAA_A_long_obj : 31|9@1+ (0.1,-12.5) [-12.5|12.5] "m/s^2"  External

BO_ 260 ETSEL_common_2: 8 IFV_CWMP
 SG_ ETSEL_common_2_MessageCounter : 62|2@1+ (1,0) [0|3] ""  External
 SG_ V_Host_Long_front : 15|14@1+ (0.01,-20) [-20|100] "m/s"  External
 SG_ V_Host_Lat_front : 29|12@1+ (0.01,-20) [-20|20] "m/s"  External
 SG_ LROSYawRate : 0|15@1+ (0.000174533,-2) [-2|2] "rad/s"  External

CM_ SG_ 549 topOffsetAngle "Internal value of topOffset converted to pixels in reduced image coordinates";
CM_ SG_ 548 referencePointX_mm "distance from camera to front bumper ";
CM_ SG_ 548 cameraHeight_mm "debug message TAC alignment";
CM_ SG_ 539 LrosTjaConfErrCnt "Debug signal to detect illegal Tja confidence values passed to LROS";
CM_ SG_ 539 LrosCmbbConfErrCnt "Debug signal to detect illegal primary CMbB confidence values passed to LROS";
BA_DEF_ SG_  "GenSigVtName" STRING ;
BA_DEF_ SG_  "GenSigVtIndex" STRING ;
BA_DEF_ SG_  "GenSigVtEn" STRING ;
BA_DEF_ SG_  "GenSigCmt" STRING ;
BA_DEF_ SG_  "GenSigStartValue" INT 0 1000000000;
BA_DEF_ SG_  "UsedOnPgmDBC" ENUM  "No","Yes";
BA_DEF_ SG_  "GenSigMissingSourceValue" INT 0 1000000000;
BA_DEF_ SG_  "GenSigInactiveValue" INT 0 100000;
BA_DEF_ SG_  "GenSigSendType" ENUM  "Cyclic","OnWrite","vector_leerstring","OnChange","vector_leerstring","IfActive","vector_leerstring","NoSigSendType";
BA_DEF_ BO_  "FrameGatewayMS1" HEX 0 1407;
BA_DEF_ BO_  "NetworkInitialization" ENUM  "No","Yes";
BA_DEF_ BO_  "EventRateOfChange" INT 10 10000;
BA_DEF_ BO_  "GenMsgStartDelayTime" INT 0 10000;
BA_DEF_ BO_  "GenMsgNrOfRepetition" INT 0 100;
BA_DEF_ BO_  "GenMsgDelayTime" INT 0 1000;
BA_DEF_ BO_  "GenMsgCycleTimeFast" INT 0 100000;
BA_DEF_ BO_  "GenMsgCycleTime" INT 0 100000;
BA_DEF_ BO_  "GenMsgSendType" ENUM  "FixedPeriodic","Event","EnabledPeriodic","NotUsed","NotUsed","EventPeriodic","NotUsed","NotUsed","NoMsgSendType";
BA_DEF_ BO_  "GenMsgILSupport" ENUM  "No","Yes";
BA_DEF_ SG_  "SystemSignalLongSymbol" STRING ;
BA_DEF_DEF_  "GenSigVtName" "";
BA_DEF_DEF_  "GenSigVtIndex" "";
BA_DEF_DEF_  "GenSigVtEn" "";
BA_DEF_DEF_  "GenSigCmt" "";
BA_DEF_DEF_  "GenSigStartValue" 0;
BA_DEF_DEF_  "UsedOnPgmDBC" "Yes";
BA_DEF_DEF_  "GenSigMissingSourceValue" 0;
BA_DEF_DEF_  "GenSigInactiveValue" 0;
BA_DEF_DEF_  "GenSigSendType" "NoSigSendType";
BA_DEF_DEF_  "FrameGatewayMS1" 0;
BA_DEF_DEF_  "NetworkInitialization" "Yes";
BA_DEF_DEF_  "EventRateOfChange" 10000;
BA_DEF_DEF_  "GenMsgStartDelayTime" 0;
BA_DEF_DEF_  "GenMsgNrOfRepetition" 0;
BA_DEF_DEF_  "GenMsgDelayTime" 0;
BA_DEF_DEF_  "GenMsgCycleTimeFast" 0;
BA_DEF_DEF_  "GenMsgCycleTime" 0;
BA_DEF_DEF_  "GenMsgSendType" "NoMsgSendType";
BA_DEF_DEF_  "GenMsgILSupport" "Yes";
BA_DEF_DEF_  "SystemSignalLongSymbol" "";
BA_ "NetworkInitialization" BO_ 1862 0;
BA_ "GenMsgSendType" BO_ 1862 1;
BA_ "NetworkInitialization" BO_ 1863 0;
BA_ "GenMsgSendType" BO_ 1863 1;
BA_ "NetworkInitialization" BO_ 1864 0;
BA_ "GenMsgSendType" BO_ 1864 1;
BA_ "NetworkInitialization" BO_ 1866 0;
BA_ "GenMsgSendType" BO_ 1866 1;
BA_ "NetworkInitialization" BO_ 1867 0;
BA_ "GenMsgSendType" BO_ 1867 1;
BA_ "NetworkInitialization" BO_ 1868 0;
BA_ "GenMsgSendType" BO_ 1868 1;
BA_ "NetworkInitialization" BO_ 1869 0;
BA_ "GenMsgSendType" BO_ 1869 1;
BA_ "NetworkInitialization" BO_ 1871 0;
BA_ "GenMsgSendType" BO_ 1871 1;
BA_ "NetworkInitialization" BO_ 1872 0;
BA_ "GenMsgSendType" BO_ 1872 1;
BA_ "NetworkInitialization" BO_ 1873 0;
BA_ "GenMsgSendType" BO_ 1873 1;
BA_ "NetworkInitialization" BO_ 1874 0;
BA_ "GenMsgSendType" BO_ 1874 1;
BA_ "NetworkInitialization" BO_ 257 0;
BA_ "GenMsgCycleTime" BO_ 257 1000;
BA_ "GenMsgSendType" BO_ 257 0;
BA_ "GenMsgSendType" BO_ 527 0;
BA_ "GenMsgCycleTime" BO_ 527 1000;
BA_ "GenMsgSendType" BO_ 522 0;
BA_ "GenMsgCycleTime" BO_ 522 1000;
BA_ "NetworkInitialization" BO_ 521 0;
BA_ "GenMsgSendType" BO_ 521 0;
BA_ "GenMsgCycleTime" BO_ 521 1000;
BA_ "NetworkInitialization" BO_ 520 0;
BA_ "GenMsgSendType" BO_ 520 0;
BA_ "GenMsgCycleTime" BO_ 520 1000;
BA_ "NetworkInitialization" BO_ 519 0;
BA_ "GenMsgSendType" BO_ 519 0;
BA_ "GenMsgCycleTime" BO_ 519 1000;
BA_ "GenMsgSendType" BO_ 516 0;
BA_ "GenMsgCycleTime" BO_ 516 100;
BA_ "GenMsgSendType" BO_ 515 0;
BA_ "GenMsgCycleTime" BO_ 515 100;
BA_ "NetworkInitialization" BO_ 514 0;
BA_ "GenMsgSendType" BO_ 514 0;
BA_ "GenMsgDelayTime" BO_ 514 200;
BA_ "GenMsgCycleTime" BO_ 514 100;
BA_ "NetworkInitialization" BO_ 513 0;
BA_ "GenMsgSendType" BO_ 513 0;
BA_ "GenMsgDelayTime" BO_ 513 100;
BA_ "GenMsgCycleTime" BO_ 513 100;
BA_ "NetworkInitialization" BO_ 512 0;
BA_ "GenMsgSendType" BO_ 512 0;
BA_ "GenMsgCycleTime" BO_ 512 100;
BA_ "NetworkInitialization" BO_ 1795 0;
BA_ "GenMsgSendType" BO_ 1795 1;
BA_ "NetworkInitialization" BO_ 1794 0;
BA_ "GenMsgSendType" BO_ 1794 1;
BA_ "NetworkInitialization" BO_ 1792 0;
BA_ "GenMsgSendType" BO_ 1792 0;
BA_ "GenMsgCycleTime" BO_ 1792 1000;
BA_ "NetworkInitialization" BO_ 1536 0;
BA_ "GenMsgSendType" BO_ 1536 1;
BA_ "NetworkInitialization" BO_ 538 0;
BA_ "GenMsgSendType" BO_ 538 1;
BA_ "NetworkInitialization" BO_ 531 0;
BA_ "GenMsgSendType" BO_ 531 1;
BA_ "NetworkInitialization" BO_ 536 0;
BA_ "GenMsgSendType" BO_ 536 1;
BA_ "NetworkInitialization" BO_ 533 0;
BA_ "GenMsgSendType" BO_ 533 1;
BA_ "NetworkInitialization" BO_ 535 0;
BA_ "GenMsgSendType" BO_ 535 1;
BA_ "NetworkInitialization" BO_ 532 0;
BA_ "GenMsgSendType" BO_ 532 1;
BA_ "NetworkInitialization" BO_ 534 0;
BA_ "GenMsgSendType" BO_ 534 1;
BA_ "GenMsgCycleTime" BO_ 1793 1000;
BA_ "NetworkInitialization" BO_ 1793 0;
BA_ "GenMsgSendType" BO_ 1793 0;
BA_ "NetworkInitialization" BO_ 523 0;
BA_ "GenMsgCycleTime" BO_ 523 1000;
BA_ "GenMsgSendType" BO_ 523 0;
BA_ "NetworkInitialization" BO_ 524 0;
BA_ "GenMsgCycleTime" BO_ 524 1000;
BA_ "GenMsgSendType" BO_ 524 0;
BA_ "NetworkInitialization" BO_ 518 0;
BA_ "GenMsgSendType" BO_ 518 0;
BA_ "GenMsgCycleTime" BO_ 518 25;
BA_ "NetworkInitialization" BO_ 542 0;
BA_ "GenMsgCycleTime" BO_ 542 55;
BA_ "GenMsgSendType" BO_ 542 0;
BA_ "NetworkInitialization" BO_ 544 0;
BA_ "GenMsgCycleTime" BO_ 544 50;
BA_ "GenMsgSendType" BO_ 544 0;
BA_ "NetworkInitialization" BO_ 549 0;
BA_ "GenMsgCycleTime" BO_ 549 50;
BA_ "GenMsgSendType" BO_ 549 0;
BA_ "NetworkInitialization" BO_ 548 0;
BA_ "GenMsgCycleTime" BO_ 548 50;
BA_ "GenMsgSendType" BO_ 548 0;
BA_ "NetworkInitialization" BO_ 540 0;
BA_ "GenMsgSendType" BO_ 540 0;
BA_ "GenMsgCycleTime" BO_ 540 1000;
BA_ "NetworkInitialization" BO_ 1029 0;
BA_ "GenMsgCycleTime" BO_ 1029 55;
BA_ "GenMsgSendType" BO_ 1029 0;
BA_ "NetworkInitialization" BO_ 753 0;
BA_ "GenMsgSendType" BO_ 753 1;
BA_ "NetworkInitialization" BO_ 752 0;
BA_ "GenMsgSendType" BO_ 752 1;
BA_ "NetworkInitialization" BO_ 737 0;
BA_ "GenMsgSendType" BO_ 737 1;
BA_ "NetworkInitialization" BO_ 736 0;
BA_ "GenMsgSendType" BO_ 736 1;
BA_ "NetworkInitialization" BO_ 1088 0;
BA_ "GenMsgCycleTime" BO_ 1088 25;
BA_ "GenMsgSendType" BO_ 1088 0;
BA_ "NetworkInitialization" BO_ 517 0;
BA_ "GenMsgSendType" BO_ 517 0;
BA_ "GenMsgCycleTime" BO_ 517 25;
BA_ "NetworkInitialization" BO_ 539 0;
BA_ "GenMsgCycleTime" BO_ 539 25;
BA_ "GenMsgSendType" BO_ 539 0;
BA_ "NetworkInitialization" BO_ 1028 0;
BA_ "GenMsgCycleTime" BO_ 1028 55;
BA_ "GenMsgSendType" BO_ 1028 0;
BA_ "NetworkInitialization" BO_ 1024 0;
BA_ "GenMsgCycleTime" BO_ 1024 25;
BA_ "GenMsgSendType" BO_ 1024 0;
BA_ "NetworkInitialization" BO_ 1926 0;
BA_ "GenMsgSendType" BO_ 1926 1;
BA_ "NetworkInitialization" BO_ 1921 0;
BA_ "GenMsgSendType" BO_ 1921 1;
BA_ "NetworkInitialization" BO_ 1922 0;
BA_ "GenMsgSendType" BO_ 1922 1;
BA_ "NetworkInitialization" BO_ 1924 0;
BA_ "GenMsgSendType" BO_ 1924 1;
BA_ "NetworkInitialization" BO_ 1925 0;
BA_ "GenMsgSendType" BO_ 1925 1;
BA_ "NetworkInitialization" BO_ 1920 0;
BA_ "GenMsgSendType" BO_ 1920 1;
BA_ "NetworkInitialization" BO_ 260 0;
BA_ "GenMsgSendType" BO_ 260 1;
BA_ "GenSigSendType" SG_ 1862 RTS2B_A_lat_obj 1;
BA_ "GenSigSendType" SG_ 1862 RTS2B_MessageCounter 1;
BA_ "GenSigSendType" SG_ 1862 RTS2B_Movement 1;
BA_ "GenSigSendType" SG_ 1862 RTS2B_V_lat_obj 1;
BA_ "GenSigSendType" SG_ 1862 RTS2B_V_long_obj 1;
BA_ "GenSigSendType" SG_ 1862 RTS2B_XOHP_ETSEL_CMbB_FCW 1;
BA_ "GenSigSendType" SG_ 1862 RTS2B_XOLC_ETSEL_CMbB_FCW 1;
BA_ "GenSigSendType" SG_ 1863 RTS2C_FARLeftRight 1;
BA_ "GenSigSendType" SG_ 1863 RTS2C_LEFTcorner_long 1;
BA_ "GenSigSendType" SG_ 1863 RTS2C_MC_Age 1;
BA_ "GenSigVtEn" SG_ 1863 RTS2C_MC_object_class "TRUE";
BA_ "GenSigVtName" SG_ 1863 RTS2C_MC_object_class "VtSig_RTS2C_MC_object_class";
BA_ "GenSigSendType" SG_ 1863 RTS2C_MC_object_class 1;
BA_ "GenSigSendType" SG_ 1863 RTS2C_MC_positionConfidence 1;
BA_ "GenSigSendType" SG_ 1863 RTS2C_MC_stage_age 1;
BA_ "GenSigSendType" SG_ 1863 RTS2C_MessageCounter 1;
BA_ "GenSigSendType" SG_ 1863 RTS2C_visTrkID 1;
BA_ "GenSigSendType" SG_ 1863 RTS2C_Width 1;
BA_ "GenSigSendType" SG_ 1864 RTS2D_FARcorner_lat 1;
BA_ "GenSigSendType" SG_ 1864 RTS2D_FARcorner_long 1;
BA_ "GenSigSendType" SG_ 1864 RTS2D_LEFTcorner_lat 1;
BA_ "GenSigSendType" SG_ 1864 RTS2D_MessageCounter 1;
BA_ "GenSigSendType" SG_ 1864 RTS2D_RIGHTcorner_lat 1;
BA_ "GenSigSendType" SG_ 1864 RTS2D_RIGHTcorner_long 1;
BA_ "GenSigSendType" SG_ 1866 RTS3A_A_long_obj 1;
BA_ "GenSigSendType" SG_ 1866 RTS3A_L_lat_rel 1;
BA_ "GenSigSendType" SG_ 1866 RTS3A_L_long_rel 1;
BA_ "GenSigVtEn" SG_ 1866 RTS3A_Status "TRUE";
BA_ "GenSigVtName" SG_ 1866 RTS3A_Status "VtSig_RTS3A_Status";
BA_ "GenSigSendType" SG_ 1866 RTS3A_Status 1;
BA_ "GenSigSendType" SG_ 1866 RTS3A_TrackID 1;
BA_ "GenSigVtEn" SG_ 1866 RTS3A_DetectionSensor "TRUE";
BA_ "GenSigVtName" SG_ 1866 RTS3A_DetectionSensor "VtSig_RTS3A_DetectionSensor";
BA_ "GenSigSendType" SG_ 1866 RTS3A_DetectionSensor 1;
BA_ "GenSigSendType" SG_ 1866 RTS3A_MessageCounter 1;
BA_ "GenSigSendType" SG_ 1867 RTS3B_A_lat_obj 1;
BA_ "GenSigSendType" SG_ 1867 RTS3B_MessageCounter 1;
BA_ "GenSigSendType" SG_ 1867 RTS3B_Movement 1;
BA_ "GenSigSendType" SG_ 1867 RTS3B_V_lat_obj 1;
BA_ "GenSigSendType" SG_ 1867 RTS3B_V_long_obj 1;
BA_ "GenSigSendType" SG_ 1867 RTS3B_XOHP_ETSEL_CMbB_FCW 1;
BA_ "GenSigSendType" SG_ 1867 RTS3B_XOLC_ETSEL_CMbB_FCW 1;
BA_ "GenSigSendType" SG_ 1868 RTS3C_FARLeftRight 1;
BA_ "GenSigSendType" SG_ 1868 RTS3C_LEFTcorner_long 1;
BA_ "GenSigSendType" SG_ 1868 RTS3C_MC_Age 1;
BA_ "GenSigVtEn" SG_ 1868 RTS3C_MC_object_class "TRUE";
BA_ "GenSigVtName" SG_ 1868 RTS3C_MC_object_class "VtSig_RTS3C_MC_object_class";
BA_ "GenSigSendType" SG_ 1868 RTS3C_MC_object_class 1;
BA_ "GenSigSendType" SG_ 1868 RTS3C_MC_positionConfidence 1;
BA_ "GenSigSendType" SG_ 1868 RTS3C_MC_stage_age 1;
BA_ "GenSigSendType" SG_ 1868 RTS3C_MessageCounter 1;
BA_ "GenSigSendType" SG_ 1868 RTS3C_visTrkID 1;
BA_ "GenSigSendType" SG_ 1868 RTS3C_Width 1;
BA_ "GenSigSendType" SG_ 1869 RTS3D_FARcorner_lat 1;
BA_ "GenSigSendType" SG_ 1869 RTS3D_FARcorner_long 1;
BA_ "GenSigSendType" SG_ 1869 RTS3D_LEFTcorner_lat 1;
BA_ "GenSigSendType" SG_ 1869 RTS3D_MessageCounter 1;
BA_ "GenSigSendType" SG_ 1869 RTS3D_RIGHTcorner_lat 1;
BA_ "GenSigSendType" SG_ 1869 RTS3D_RIGHTcorner_long 1;
BA_ "GenSigSendType" SG_ 1871 RTS4A_A_long_obj 1;
BA_ "GenSigVtEn" SG_ 1871 RTS4A_DetectionSensor "TRUE";
BA_ "GenSigVtName" SG_ 1871 RTS4A_DetectionSensor "VtSig_RTS4A_DetectionSensor";
BA_ "GenSigSendType" SG_ 1871 RTS4A_DetectionSensor 1;
BA_ "GenSigSendType" SG_ 1871 RTS4A_L_lat_rel 1;
BA_ "GenSigSendType" SG_ 1871 RTS4A_L_long_rel 1;
BA_ "GenSigSendType" SG_ 1871 RTS4A_MessageCounter 1;
BA_ "GenSigVtEn" SG_ 1871 RTS4A_Status "TRUE";
BA_ "GenSigVtName" SG_ 1871 RTS4A_Status "VtSig_RTS4A_Status";
BA_ "GenSigSendType" SG_ 1871 RTS4A_Status 1;
BA_ "GenSigSendType" SG_ 1871 RTS4A_TrackID 1;
BA_ "GenSigSendType" SG_ 1872 RTS4B_A_lat_obj 1;
BA_ "GenSigSendType" SG_ 1872 RTS4B_MessageCounter 1;
BA_ "GenSigSendType" SG_ 1872 RTS4B_Movement 1;
BA_ "GenSigSendType" SG_ 1872 RTS4B_V_lat_obj 1;
BA_ "GenSigSendType" SG_ 1872 RTS4B_V_long_obj 1;
BA_ "GenSigSendType" SG_ 1872 RTS4B_XOHP_ETSEL_CMbB_FCW 1;
BA_ "GenSigSendType" SG_ 1872 RTS4B_XOLC_ETSEL_CMbB_FCW 1;
BA_ "GenSigSendType" SG_ 1873 RTS4C_FARLeftRight 1;
BA_ "GenSigSendType" SG_ 1873 RTS4C_LEFTcorner_long 1;
BA_ "GenSigSendType" SG_ 1873 RTS4C_MC_Age 1;
BA_ "GenSigVtEn" SG_ 1873 RTS4C_MC_object_class "TRUE";
BA_ "GenSigVtName" SG_ 1873 RTS4C_MC_object_class "VtSig_RTS4C_MC_object_class";
BA_ "GenSigSendType" SG_ 1873 RTS4C_MC_object_class 1;
BA_ "GenSigSendType" SG_ 1873 RTS4C_MC_positionConfidence 1;
BA_ "GenSigSendType" SG_ 1873 RTS4C_MC_stage_age 1;
BA_ "GenSigSendType" SG_ 1873 RTS4C_MessageCounter 1;
BA_ "GenSigSendType" SG_ 1873 RTS4C_visTrkID 1;
BA_ "GenSigSendType" SG_ 1873 RTS4C_Width 1;
BA_ "GenSigSendType" SG_ 1874 RTS4D_FARcorner_lat 1;
BA_ "GenSigSendType" SG_ 1874 RTS4D_FARcorner_long 1;
BA_ "GenSigSendType" SG_ 1874 RTS4D_LEFTcorner_lat 1;
BA_ "GenSigSendType" SG_ 1874 RTS4D_MessageCounter 1;
BA_ "GenSigSendType" SG_ 1874 RTS4D_RIGHTcorner_long 1;
BA_ "GenSigSendType" SG_ 1874 RTS4D_RIGHTcorner_lat 1;
BA_ "GenSigSendType" SG_ 257 ETSEL_Interface_Major_Version 1;
BA_ "GenSigSendType" SG_ 257 ETSEL_Interface_Minor_Version 1;
BA_ "GenSigSendType" SG_ 257 Tracker_Interface_Major_Version 1;
BA_ "GenSigSendType" SG_ 257 Tracker_Interface_Minor_Version 1;
BA_ "SystemSignalLongSymbol" SG_ 527 PCAN_370_BrkSyExHldCpbFld_H_b20_ "PCAN_370_BrkSyExHldCpbFld_H_b20_5";
BA_ "SystemSignalLongSymbol" SG_ 522 PB_1E1_CrsSpdLmtrSwStPVal_H_b1E_ "PB_1E1_CrsSpdLmtrSwStPVal_H_b1E_6";
BA_ "SystemSignalLongSymbol" SG_ 522 PB_0F1_BrkAppSnsrHmPosLrnd_H_b1C "PB_0F1_BrkAppSnsrHmPosLrnd_H_b1C_3";
BA_ "SystemSignalLongSymbol" SG_ 521 PB_1C4_AccPdlOvAtvProtVal_H_b14_ "PB_1C4_AccPdlOvAtvProtVal_H_b14_6";
BA_ "SystemSignalLongSymbol" SG_ 521 PB_1C4_AutBrkAccActPsPVal_H_b14_ "PB_1C4_AutBrkAccActPsPVal_H_b14_7";
BA_ "GenSigVtEn" SG_ 521 PB_2C3_EngTrqMinExtRngV_H_b13_0 "TRUE";
BA_ "GenSigVtName" SG_ 521 PB_2C3_EngTrqMinExtRngV_H_b13_0 "VtSig_PB_2C3_EngTrqMinExtRngV_H_b13_0";
BA_ "GenSigCmt" SG_ 521 PB_2C3_EngTrqMinExtRngV_H_b13_0 "VehOverGnd_V_EST QF Error (ABS)";
BA_ "GenSigVtEn" SG_ 521 PB_0C9_PT_BPdDscrtInpStV_H_b13_1 "TRUE";
BA_ "GenSigVtName" SG_ 521 PB_0C9_PT_BPdDscrtInpStV_H_b13_1 "VtSig_PB_0C9_PT_BPdDscrtInpStV_H_b13_1";
BA_ "GenSigCmt" SG_ 521 PB_0C9_PT_BPdDscrtInpStV_H_b13_1 "VehYawComp_W_Actl QF Error (ABS)";
BA_ "GenSigVtEn" SG_ 521 PB_1F5_TopTrvICltSwActV_H_b13_2 "TRUE";
BA_ "GenSigVtName" SG_ 521 PB_1F5_TopTrvICltSwActV_H_b13_2 "VtSig_PB_1F5_TopTrvICltSwActV_H_b13_2";
BA_ "GenSigCmt" SG_ 521 PB_1F5_TopTrvICltSwActV_H_b13_2 "PB_1F5_TopTrvICltSwActV_H_b13_2 (ABS)";
BA_ "GenSigVtEn" SG_ 521 PB_1F5_TransEstGearV_H_b13_3 "TRUE";
BA_ "GenSigVtName" SG_ 521 PB_1F5_TransEstGearV_H_b13_3 "VtSig_PB_1F5_TransEstGearV_H_b13_3";
BA_ "GenSigCmt" SG_ 521 PB_1F5_TransEstGearV_H_b13_3 "PB_1F5_TransEstGearV_H_b13_3 (ABS)";
BA_ "GenSigVtEn" SG_ 521 PB_1F5_TrnsEngdStateV_H_b13_4 "TRUE";
BA_ "GenSigVtName" SG_ 521 PB_1F5_TrnsEngdStateV_H_b13_4 "VtSig_CcAslButtnDeny_B_Actl_QF_E";
BA_ "GenSigCmt" SG_ 521 PB_1F5_TrnsEngdStateV_H_b13_4 "CcAslButtnDeny_B_Actl QF Error (SCCM)";
BA_ "GenSigVtEn" SG_ 521 PB_3E9_VehSpdAvgDrvnV_H_b13_5 "TRUE";
BA_ "GenSigVtName" SG_ 521 PB_3E9_VehSpdAvgDrvnV_H_b13_5 "VtSig_PB_3E9_VehSpdAvgDrvnV_H_b13_5";
BA_ "GenSigCmt" SG_ 521 PB_3E9_VehSpdAvgDrvnV_H_b13_5 "LaSwtchPos_D_Stat QF Error (SCCM)";
BA_ "GenSigCmt" SG_ 521 PB_3E9_VehSpdAvgNDrvnV_H_b13_6 "LaActDeny_B_Actl QF Error (SCCM)";
BA_ "GenSigVtEn" SG_ 521 PB_3E9_VehSpdAvgNDrvnV_H_b13_6 "TRUE";
BA_ "GenSigVtName" SG_ 521 PB_3E9_VehSpdAvgNDrvnV_H_b13_6 "VtSig_PB_3E9_VehSpdAvgNDrvnV_H_b13_6";
BA_ "GenSigVtEn" SG_ 521 PB_1C4_ACCATCS_RqStat_H_b13_7 "TRUE";
BA_ "GenSigVtName" SG_ 521 PB_1C4_ACCATCS_RqStat_H_b13_7 "VtSig_PB_1C4_ACCATCS_RqStat_H_b13_7";
BA_ "GenSigCmt" SG_ 521 PB_1C4_ACCATCS_RqStat_H_b13_7 "VehYaw_W_Actl QF Error (RCM)";
BA_ "GenSigVtEn" SG_ 521 PB_4F3_PPEIPTCfg2Miss_H_b12_0 "TRUE";
BA_ "GenSigVtName" SG_ 521 PB_4F3_PPEIPTCfg2Miss_H_b12_0 "VtSig_PB_4F3_PPEIPTCfg2Miss_H_b12_0";
BA_ "GenSigCmt" SG_ 521 PB_4F3_PPEIPTCfg2Miss_H_b12_0 "SCCM_5 Missing Msg (LaSwtchPos_D_Stat)";
BA_ "GenSigVtEn" SG_ 521 PB_1C4_ABAAPS_AccPosV_H_b12_1 "TRUE";
BA_ "GenSigVtName" SG_ 521 PB_1C4_ABAAPS_AccPosV_H_b12_1 "VtSig_PB_1C4_ABAAPS_AccPosV_H_b12_1";
BA_ "GenSigCmt" SG_ 521 PB_1C4_ABAAPS_AccPosV_H_b12_1 "PB_1C4_ABAAPS_AccPosV_H_b12_1 (DrQltyDrv_D_StatGsm)";
BA_ "GenSigVtEn" SG_ 521 PB_1C5_DrvIAxlTrqMaxV_H_b12_2 "TRUE";
BA_ "GenSigVtName" SG_ 521 PB_1C5_DrvIAxlTrqMaxV_H_b12_2 "VtSig_ApedposPcActl_D_Qf_QF_Er";
BA_ "GenSigCmt" SG_ 521 PB_1C5_DrvIAxlTrqMaxV_H_b12_2 "ApedposPcActl_D_Qf QF Error (ECM)";
BA_ "GenSigVtEn" SG_ 521 PB_1C5_DrvIAxlTrqMinV_H_b12_3 "TRUE";
BA_ "GenSigVtName" SG_ 521 PB_1C5_DrvIAxlTrqMinV_H_b12_3 "VtSig_PB_1C5_DrvIAxlTrqMinV_H_b12_3";
BA_ "GenSigCmt" SG_ 521 PB_1C5_DrvIAxlTrqMinV_H_b12_3 "GearRvrse_D_Actl QF Error(ECM)";
BA_ "GenSigVtEn" SG_ 521 PB_1C5_DrvIntndAxlTrqV_H_b12_4 "TRUE";
BA_ "GenSigVtName" SG_ 521 PB_1C5_DrvIntndAxlTrqV_H_b12_4 "VtSig_PB_1C5_DrvIntndAxlTrqV_H_b12_4";
BA_ "GenSigCmt" SG_ 521 PB_1C5_DrvIntndAxlTrqV_H_b12_4 "VehVActlEng_D_Qf QF Error(ECM)";
BA_ "GenSigVtEn" SG_ 521 PB_1C3_EngTrqActExtRngV_H_b12_5 "TRUE";
BA_ "GenSigVtName" SG_ 521 PB_1C3_EngTrqActExtRngV_H_b12_5 "VtSig_PB_1C3_EngTrqActExtRngV_H_b12_5";
BA_ "GenSigCmt" SG_ 521 PB_1C3_EngTrqActExtRngV_H_b12_5 "CcStat_D_Actl QF Error (ECM)";
BA_ "GenSigVtEn" SG_ 521 PB_1C3_EngTqDrRqExtRngV_H_b12_6 "TRUE";
BA_ "GenSigVtName" SG_ 521 PB_1C3_EngTqDrRqExtRngV_H_b12_6 "VtSig_PB_1C3_EngTqDrRqExtRngV_H_b12_6";
BA_ "GenSigCmt" SG_ 521 PB_1C3_EngTqDrRqExtRngV_H_b12_6 "GearLvrPos_D_Actl QF Error (TCM)";
BA_ "GenSigVtEn" SG_ 521 PB_2C3_EngTrqMaxExtRngV_H_b12_7 "TRUE";
BA_ "GenSigVtName" SG_ 521 PB_2C3_EngTrqMaxExtRngV_H_b12_7 "VtSig_SteWhlCompAnEst_D_Qf_QF_E";
BA_ "GenSigCmt" SG_ 521 PB_2C3_EngTrqMaxExtRngV_H_b12_7 "SteWhlCompAnEst_D_Qf QF Error (ABS)";
BA_ "GenSigVtEn" SG_ 521 PB_0C9_PPEIEngGSt1Miss_H_b11_0 "TRUE";
BA_ "GenSigVtName" SG_ 521 PB_0C9_PPEIEngGSt1Miss_H_b11_0 "VtSig_PB_2C3_PPEIEngTorqMiss_H_b11_0";
BA_ "GenSigCmt" SG_ 521 PB_0C9_PPEIEngGSt1Miss_H_b11_0 "IPC_2 Missing Msg (MsgCntrDsplyOp_D_Rq)";
BA_ "GenSigVtEn" SG_ 521 PB_1C3_PPEIEngTrqSt2Miss_H_b11_1 "TRUE";
BA_ "GenSigVtName" SG_ 521 PB_1C3_PPEIEngTrqSt2Miss_H_b11_1 "VtSig_PB_3E9_PPEIVehSpdMiss_H_b11_1";
BA_ "GenSigCmt" SG_ 521 PB_1C3_PPEIEngTrqSt2Miss_H_b11_1 "HUD Missing Msg (Hud_B_Falt)";
BA_ "GenSigVtEn" SG_ 521 PB_1C4_PPEITrqReqStMiss_H_b11_2 "TRUE";
BA_ "GenSigVtName" SG_ 521 PB_1C4_PPEITrqReqStMiss_H_b11_2 "VtSig_SSysDisabledInfoStored";
BA_ "GenSigCmt" SG_ 521 PB_1C4_PPEITrqReqStMiss_H_b11_2 "SECM Missing Msg (LaActDeny_B_Actl)";
BA_ "GenSigVtEn" SG_ 521 PB_1C5_PPEIDrIAxTqStMiss_H_b11_3 "TRUE";
BA_ "GenSigVtName" SG_ 521 PB_1C5_PPEIDrIAxTqStMiss_H_b11_3 "VtSig_PB_4F3_PPEIPTConfigMiss_H_b11_3";
BA_ "GenSigCmt" SG_ 521 PB_1C5_PPEIDrIAxTqStMiss_H_b11_3 "PSCM Missing Msg (LaActDeny_B_Actl)";
BA_ "GenSigVtEn" SG_ 521 PB_1F5_PPEITrGenSt2Miss_H_b11_4 "TRUE";
BA_ "GenSigVtName" SG_ 521 PB_1F5_PPEITrGenSt2Miss_H_b11_4 "VtSig_PB_1C4_ABAAPSAccPosV_H_b11_4";
BA_ "GenSigCmt" SG_ 521 PB_1F5_PPEITrGenSt2Miss_H_b11_4 "SCCM Missing Msg (CcAslButtnDeny_B_Actl)";
BA_ "GenSigVtEn" SG_ 521 PB_2C3_PPEIEngTrqSt3Miss_H_b11_5 "TRUE";
BA_ "GenSigVtName" SG_ 521 PB_2C3_PPEIEngTrqSt3Miss_H_b11_5 "VtSig_PB_1C5_DrvIntndAxlTrqMaxV_H_b11_5";
BA_ "GenSigCmt" SG_ 521 PB_2C3_PPEIEngTrqSt3Miss_H_b11_5 "SCCM_2 Missing Msg (SteWhlRelInit2_An_Sns)";
BA_ "GenSigVtEn" SG_ 521 PB_3E9_PPEIVehSpdDisMiss_H_b11_6 "TRUE";
BA_ "GenSigVtName" SG_ 521 PB_3E9_PPEIVehSpdDisMiss_H_b11_6 "VtSig_PB_1C5_DrvIntndAxlTrqMinV_H_b11_6";
BA_ "GenSigCmt" SG_ 521 PB_3E9_PPEIVehSpdDisMiss_H_b11_6 "SCCM_3 Missing Msg (TurnLghtSwtch_D_Stat)";
BA_ "GenSigVtEn" SG_ 521 PB_4F1_PPEIPTConfMiss_H_b11_7 "TRUE";
BA_ "GenSigVtName" SG_ 521 PB_4F1_PPEIPTConfMiss_H_b11_7 "VtSig_PB_1C5_DrvIntndAxlTrqV_H_b11_7";
BA_ "GenSigCmt" SG_ 521 PB_4F1_PPEIPTConfMiss_H_b11_7 "SCCM_4 Missing Msg (LaActDeny_B_Actl)";
BA_ "GenSigVtEn" SG_ 521 MRRPCANIntComp_H_b10_0 "TRUE";
BA_ "GenSigVtName" SG_ 521 MRRPCANIntComp_H_b10_0 "VtSig_MRRPCANIntComp_H_b10_0";
BA_ "GenSigCmt" SG_ 521 MRRPCANIntComp_H_b10_0 "MRRPCANIntComp_H_b10_0";
BA_ "GenSigVtEn" SG_ 521 PCAN_330_IMULonAccSecAval_H_b10_ "TRUE";
BA_ "GenSigVtName" SG_ 521 PCAN_330_IMULonAccSecAval_H_b10_ "VtSig_PCAN_330_IMUYawRtSecAval_H_b10_1";
BA_ "GenSigCmt" SG_ 521 PCAN_330_IMULonAccSecAval_H_b10_ "RCM  Missing Message (VehYaw_W_Actl)";
BA_ "SystemSignalLongSymbol" SG_ 521 PCAN_330_IMULonAccSecAval_H_b10_ "PCAN_330_IMULonAccSecAval_H_b10_1";
BA_ "GenSigVtEn" SG_ 521 PCAN_340_IMUYawRtSecAval_H_b10_2 "TRUE";
BA_ "GenSigVtName" SG_ 521 PCAN_340_IMUYawRtSecAval_H_b10_2 "VtSig_PCAN_340_IMULatAccSecAval_H_b10_2";
BA_ "GenSigCmt" SG_ 521 PCAN_340_IMUYawRtSecAval_H_b10_2 "RCM_2 Missing Msg (VehLat2_A_Actl)";
BA_ "GenSigVtEn" SG_ 521 PCAN_340_IMULatAccSecAval_H_b10_ "TRUE";
BA_ "GenSigVtName" SG_ 521 PCAN_340_IMULatAccSecAval_H_b10_ "VtSig_PB_0C9_PPEIEngGenMiss_H_b10_3";
BA_ "GenSigCmt" SG_ 521 PCAN_340_IMULatAccSecAval_H_b10_ "RCM_3 Missing Msg (VehLong2_A_Actl)";
BA_ "SystemSignalLongSymbol" SG_ 521 PCAN_340_IMULatAccSecAval_H_b10_ "PCAN_340_IMULatAccSecAval_H_b10_3";
BA_ "GenSigVtEn" SG_ 521 PB_1E5_StrWhlAngSenTyp_H_b10_5 "TRUE";
BA_ "GenSigVtName" SG_ 521 PB_1E5_StrWhlAngSenTyp_H_b10_5 "VtSig_PB_1C4_PPEITorqReqMiss_H_b10_5";
BA_ "GenSigCmt" SG_ 521 PB_1E5_StrWhlAngSenTyp_H_b10_5 "BCM_2 Missing Msg (DrStatDrv_B_Actl)";
BA_ "GenSigVtEn" SG_ 520 FCMIndSTB_H_bF_0 "TRUE";
BA_ "GenSigVtName" SG_ 520 FCMIndSTB_H_bF_0 "VtSig_FCMIndSTB_H_bF_0";
BA_ "GenSigCmt" SG_ 520 FCMIndSTB_H_bF_0 "ECM_9 Missing Msg (Veh_V_ActlEng)";
BA_ "GenSigVtEn" SG_ 520 FCMIndSTGorOPN_H_bF_1 "TRUE";
BA_ "GenSigVtName" SG_ 520 FCMIndSTGorOPN_H_bF_1 "VtSig_FCMIndSTGorOPN_H_bF_1";
BA_ "GenSigCmt" SG_ 520 FCMIndSTGorOPN_H_bF_1 "TCM Missing Msg (GearLvrPos_D_Actl)";
BA_ "GenSigVtEn" SG_ 520 LKASwtchSTG_H_bF_2 "TRUE";
BA_ "GenSigVtName" SG_ 520 LKASwtchSTG_H_bF_2 "VtSig_LKAStchSTG";
BA_ "GenSigCmt" SG_ 520 LKASwtchSTG_H_bF_2 "ABS Missing Msg  (VehOverGnd_V_Est)";
BA_ "GenSigCmt" SG_ 520 MRRPCANMissingMsgHOST_H_bF_4 "MRRPCANMissingMsgHOST_H_bF_4";
BA_ "GenSigCmt" SG_ 520 MRRPCANMissingMsgVFP_H_bF_5 "MRRPCANMissingMsgVFP_H_bF_5";
BA_ "GenSigCmt" SG_ 520 MRRPCANRangeCheckVFP_H_bF_6 "MRRPCANRangeCheckVFP_H_bF_6";
BA_ "GenSigCmt" SG_ 520 MRRPCANInvalidDataVFP_H_bF_7 "MRRPCANInvalidDataVFP_H_bF_7";
BA_ "GenSigCmt" SG_ 520 VisionInternalError_H_bE_0 "VisionInternalError_H_bE_0";
BA_ "GenSigVtEn" SG_ 520 VINMismatch_H_bE_1 "TRUE";
BA_ "GenSigVtName" SG_ 520 VINMismatch_H_bE_1 "VtSig_VINMismatch";
BA_ "GenSigCmt" SG_ 520 VINMismatch_H_bE_1 "ECM_2 Missing Msg (GearRvrse_D_Actl)";
BA_ "GenSigVtEn" SG_ 520 ECUSWCalDataSetNotProg_H_bE_2 "TRUE";
BA_ "GenSigVtName" SG_ 520 ECUSWCalDataSetNotProg_H_bE_2 "VtSig_ECUSWCalDataSetNotProg";
BA_ "GenSigCmt" SG_ 520 ECUSWCalDataSetNotProg_H_bE_2 "ECM_3 Missing Msg (ApedPos_Pc_ActlArb)";
BA_ "GenSigVtEn" SG_ 520 VehConfNotProg_H_bE_3 "TRUE";
BA_ "GenSigVtName" SG_ 520 VehConfNotProg_H_bE_3 "VtSig_VehConfNotProg_H";
BA_ "GenSigCmt" SG_ 520 VehConfNotProg_H_bE_3 "ECM_4 Missing Msg (BpedDrvAppl_D_Actl)";
BA_ "GenSigVtEn" SG_ 520 VINNotProg_H_bE_4 "TRUE";
BA_ "GenSigVtName" SG_ 520 VINNotProg_H_bE_4 "VtSig_VINNotProg_H";
BA_ "GenSigCmt" SG_ 520 VINNotProg_H_bE_4 "ECM_5 Missing Msg (PrplTqMnSat_B_Actl)";
BA_ "GenSigVtEn" SG_ 520 CameraCalNotLearnt_H_bE_5 "TRUE";
BA_ "GenSigVtName" SG_ 520 CameraCalNotLearnt_H_bE_5 "VtSig_CameraCalNotLearnt_H_bE_5";
BA_ "GenSigCmt" SG_ 520 CameraCalNotLearnt_H_bE_5 "ECM_7 Missing Msg (CcStat_D_Actl)";
BA_ "GenSigVtEn" SG_ 520 HostVCANBusOff_H_bE_6 "TRUE";
BA_ "GenSigVtName" SG_ 520 HostVCANBusOff_H_bE_6 "VtSig_HostVCANBusOff_H_bE_7";
BA_ "GenSigCmt" SG_ 520 HostVCANBusOff_H_bE_6 "ECM_8 Missing Msg (AirAmb_Te_ActlFilt)";
BA_ "GenSigVtEn" SG_ 520 SysDisabledInfoStored_H_bE_7 "TRUE";
BA_ "GenSigVtName" SG_ 520 SysDisabledInfoStored_H_bE_7 "VtSig_SysDisabledInfoStored";
BA_ "GenSigCmt" SG_ 520 SysDisabledInfoStored_H_bE_7 "ECM Missing Msg (AccEngStat_D_Actl)";
BA_ "GenSigCmt" SG_ 520 HostCoreSelftestFault_H_bD_0 "HostCoreSelftestFault_H_bD_0";
BA_ "GenSigCmt" SG_ 520 ECCSelfTestCheckFault_H_bD_1 "ECCSelfTestCheckFault_H_bD_1";
BA_ "GenSigCmt" SG_ 520 HostCoreExceptionFault_H_bD_2 "HostCoreExceptionFault_H_bD_2";
BA_ "GenSigCmt" SG_ 520 HostCtrConfigRegFault_H_bD_3 "HostCtrConfigRegFault_H_bD_3";
BA_ "GenSigCmt" SG_ 520 HostADCSelfTestFault_H_bD_4 "HostADCSelfTestFault_H_bD_4";
BA_ "GenSigCmt" SG_ 520 HostADCMonitorFault_H_bD_5 "HostADCMonitorFault_H_bD_5";
BA_ "GenSigCmt" SG_ 520 HostCVMResetFault_H_bD_6 "HostCVMResetFault_H_bD_6";
BA_ "GenSigCmt" SG_ 520 HostCVMSTsetFault_H_bD_7 "HostCVMSTsetFault_H_bD_7";
BA_ "GenSigVtEn" SG_ 520 AlignAdjustIncorrect_H_bC_0 "TRUE";
BA_ "GenSigVtName" SG_ 520 AlignAdjustIncorrect_H_bC_0 "VtSig_alignadjustincorr_H_bC_0";
BA_ "GenSigCmt" SG_ 520 AlignAdjustIncorrect_H_bC_0 "flr_alignadjustincorr";
BA_ "GenSigVtEn" SG_ 520 VisionRadar_Missaligned_H_bC_1 "TRUE";
BA_ "GenSigVtName" SG_ 520 VisionRadar_Missaligned_H_bC_1 "VtSig_flr_misalignment_H_bC_1";
BA_ "GenSigCmt" SG_ 520 VisionRadar_Missaligned_H_bC_1 "flr_misalignment";
BA_ "GenSigVtEn" SG_ 520 Vision_OutOfFocus_Fault_H_bC_2 "TRUE";
BA_ "GenSigVtName" SG_ 520 Vision_OutOfFocus_Fault_H_bC_2 "VtSig_Vision_OutOfFocus_H_bC_2";
BA_ "GenSigCmt" SG_ 520 Vision_OutOfFocus_Fault_H_bC_2 "Vision_OutOfFocus";
BA_ "GenSigVtEn" SG_ 520 Vision_OutOfCalibration_H_bC_3 "TRUE";
BA_ "GenSigVtName" SG_ 520 Vision_OutOfCalibration_H_bC_3 "VtSig_CameraAlignIncomplete_H_bC_3";
BA_ "GenSigCmt" SG_ 520 Vision_OutOfCalibration_H_bC_3 "CameraAlignIncomplete";
BA_ "GenSigCmt" SG_ 520 HostISRConsistencyCheck_H_bC_5 "HostISRConsistencyCheck_H_bC_5";
BA_ "GenSigCmt" SG_ 520 ECCSelfTest_CF_H_bC_6 "ECCSelfTest_CF_H_bC_6";
BA_ "GenSigCmt" SG_ 520 ECCSelfTest_RAM_H_bC_7 "ECCSelfTest_RAM_H_bC_7";
BA_ "GenSigVtEn" SG_ 520 Smeared_Spots_fault_H_bB_0 "TRUE";
BA_ "GenSigVtName" SG_ 520 Smeared_Spots_fault_H_bB_0 "VtSig_Image_smearedSpots_fault_H_bB_0";
BA_ "GenSigCmt" SG_ 520 Smeared_Spots_fault_H_bB_0 "Image_smearedSpots";
BA_ "GenSigVtEn" SG_ 520 SelfGlare_fault_H_bB_1 "TRUE";
BA_ "GenSigVtName" SG_ 520 SelfGlare_fault_H_bB_1 "VtSig_Image_SelfGlare";
BA_ "GenSigCmt" SG_ 520 SelfGlare_fault_H_bB_1 "Image_SelfGlare";
BA_ "GenSigVtEn" SG_ 520 Low_Visibility_fault_H_bB_2 "TRUE";
BA_ "GenSigVtName" SG_ 520 Low_Visibility_fault_H_bB_2 "VtSig_Image_Low_visibility";
BA_ "GenSigCmt" SG_ 520 Low_Visibility_fault_H_bB_2 "Image_Low visibility";
BA_ "GenSigVtEn" SG_ 520 imager_pattern_fault_H_bB_4 "TRUE";
BA_ "GenSigVtName" SG_ 520 imager_pattern_fault_H_bB_4 "VtSig_imager_pattern_fault";
BA_ "GenSigCmt" SG_ 520 imager_pattern_fault_H_bB_4 "imager_pattern_fault";
BA_ "GenSigVtEn" SG_ 520 HostSWP2RAMCRCFlt_H_bB_5 "TRUE";
BA_ "GenSigVtName" SG_ 520 HostSWP2RAMCRCFlt_H_bB_5 "VtSig_HostSWP2RAMCRCFlt";
BA_ "GenSigCmt" SG_ 520 HostSWP2RAMCRCFlt_H_bB_5 "HostSWP2RAMCRCFlt";
BA_ "GenSigCmt" SG_ 520 VisionAlignIncomplete_H_bB_6 "VisionAlignIncomplete_H_bB_6";
BA_ "GenSigVtEn" SG_ 520 Full_Blockage_fault_H_bA_0 "TRUE";
BA_ "GenSigVtName" SG_ 520 Full_Blockage_fault_H_bA_0 "VtSig_vision_full_blockage";
BA_ "GenSigCmt" SG_ 520 Full_Blockage_fault_H_bA_0 "vision_full_blockage";
BA_ "GenSigVtEn" SG_ 520 Blurred_Image_fault_H_bA_1 "TRUE";
BA_ "GenSigVtName" SG_ 520 Blurred_Image_fault_H_bA_1 "VtSig_blur_image_failsafe";
BA_ "GenSigCmt" SG_ 520 Blurred_Image_fault_H_bA_1 "blur_image_failsafe";
BA_ "GenSigVtEn" SG_ 520 TD_Blockage_Fault_H_bA_2 "TRUE";
BA_ "GenSigVtName" SG_ 520 TD_Blockage_Fault_H_bA_2 "VtSig_TD_Blockage_Fault";
BA_ "GenSigCmt" SG_ 520 TD_Blockage_Fault_H_bA_2 "TD_Blockage_Fault";
BA_ "GenSigVtEn" SG_ 520 Splashes_fault_H_bA_3 "TRUE";
BA_ "GenSigVtName" SG_ 520 Splashes_fault_H_bA_3 "VtSig_Image_splashes";
BA_ "GenSigCmt" SG_ 520 Splashes_fault_H_bA_3 "Image_splashes";
BA_ "GenSigVtEn" SG_ 520 Low_Sun_fault_H_bA_4 "TRUE";
BA_ "GenSigVtName" SG_ 520 Low_Sun_fault_H_bA_4 "VtSig_Image_low_sun";
BA_ "GenSigCmt" SG_ 520 Low_Sun_fault_H_bA_4 "Image_low sun";
BA_ "GenSigVtEn" SG_ 520 Sun_Rays_faults_H_bA_5 "TRUE";
BA_ "GenSigVtName" SG_ 520 Sun_Rays_faults_H_bA_5 "VtSig_Image_SunRay";
BA_ "GenSigCmt" SG_ 520 Sun_Rays_faults_H_bA_5 "Image_SunRay";
BA_ "GenSigVtEn" SG_ 520 Foggy_Spots_fault_H_bA_6 "TRUE";
BA_ "GenSigVtName" SG_ 520 Foggy_Spots_fault_H_bA_6 "VtSig_Image_FoggySpots";
BA_ "GenSigCmt" SG_ 520 Foggy_Spots_fault_H_bA_6 "Image_FoggySpots";
BA_ "GenSigVtEn" SG_ 520 Spot_Rays_fault_H_bA_7 "TRUE";
BA_ "GenSigVtName" SG_ 520 Spot_Rays_fault_H_bA_7 "VtSig_Image_SpotRay";
BA_ "GenSigCmt" SG_ 520 Spot_Rays_fault_H_bA_7 "Image_SpotRay";
BA_ "GenSigCmt" SG_ 520 HostPLLStoppedFault_H_b9_0 "Reserved";
BA_ "GenSigCmt" SG_ 520 HostWatchDogSelftestFault_H_b9_1 "Reserved";
BA_ "GenSigVtEn" SG_ 520 VfpCamMalFunc_H_b9_2 "TRUE";
BA_ "GenSigVtName" SG_ 520 VfpCamMalFunc_H_b9_2 "VtSig_VfpCamMalFunc";
BA_ "GenSigCmt" SG_ 520 VfpCamMalFunc_H_b9_2 "VfpCamMalFunc";
BA_ "GenSigVtEn" SG_ 520 VfpCamCtrlFlt_H_b9_3 "TRUE";
BA_ "GenSigVtName" SG_ 520 VfpCamCtrlFlt_H_b9_3 "VtSig_VfpCamCtrlFlt";
BA_ "GenSigCmt" SG_ 520 VfpCamCtrlFlt_H_b9_3 "VfpCamCtrlFlt";
BA_ "GenSigVtEn" SG_ 520 VfpCamVdoFlt_H_b9_5 "TRUE";
BA_ "GenSigVtName" SG_ 520 VfpCamVdoFlt_H_b9_5 "VtSig_VfpCamVdoFlt";
BA_ "GenSigCmt" SG_ 520 VfpCamVdoFlt_H_b9_5 "VfpCamVdoFlt";
BA_ "GenSigVtEn" SG_ 520 Partial_Blockage_fault_H_b9_7 "TRUE";
BA_ "GenSigVtName" SG_ 520 Partial_Blockage_fault_H_b9_7 "VtSig_Image_Partial_blockage";
BA_ "GenSigCmt" SG_ 520 Partial_Blockage_fault_H_b9_7 "Image_Partial_blockage";
BA_ "GenSigVtEn" SG_ 520 CMBB_ACC_ValFault_H_b8_2 "TRUE";
BA_ "GenSigVtName" SG_ 520 CMBB_ACC_ValFault_H_b8_2 "VtSig_CMBB_ACC_ValFault";
BA_ "GenSigCmt" SG_ 520 CMBB_ACC_ValFault_H_b8_2 "CMBB_ACC_ValFault";
BA_ "GenSigCmt" SG_ 520 HostSWResetMismatchFault_H_b8_3 "HostSWResetMismatchFault";
BA_ "GenSigCmt" SG_ 520 CAN_BDU_Msg_Invalid_H_b8_4 "CAN_BDU_Msg_Invalid";
BA_ "GenSigCmt" SG_ 520 HostCSIHPeripheralFault_H_b8_5 "Reserved";
BA_ "GenSigCmt" SG_ 520 HostCANPeripheralFault_H_b8_6 "Reserved";
BA_ "GenSigCmt" SG_ 520 HostHighSpdOscStopFault_H_b8_7 "Reserved";
BA_ "GenSigVtEn" SG_ 519 grab_issue_failure_H_b7_0 "TRUE";
BA_ "GenSigVtName" SG_ 519 grab_issue_failure_H_b7_0 "VtSig_grab_issue_failure_H_b7_0";
BA_ "GenSigCmt" SG_ 519 grab_issue_failure_H_b7_0 "grab_issue_failure_H_b7_0";
BA_ "GenSigVtEn" SG_ 519 grab_acquire_failure_H_b7_1 "TRUE";
BA_ "GenSigVtName" SG_ 519 grab_acquire_failure_H_b7_1 "VtSig_grab_acquire_failure_H_b7_1";
BA_ "GenSigCmt" SG_ 519 grab_acquire_failure_H_b7_1 "grab_acquire_failure_H_b7_1";
BA_ "GenSigVtEn" SG_ 519 grab_release_failure_H_b7_2 "TRUE";
BA_ "GenSigVtName" SG_ 519 grab_release_failure_H_b7_2 "VtSig_grab_release_failure_H_b7_2";
BA_ "GenSigCmt" SG_ 519 grab_release_failure_H_b7_2 "grab_release_failure_H_b7_2";
BA_ "GenSigVtEn" SG_ 519 VFP_subsystem_comm_fault_H_b7_3 "TRUE";
BA_ "GenSigVtName" SG_ 519 VFP_subsystem_comm_fault_H_b7_3 "VtSig_subsystem_comm_fault_H_b7_3";
BA_ "GenSigCmt" SG_ 519 VFP_subsystem_comm_fault_H_b7_3 "subsystem_comm_fault_H_b7_3";
BA_ "GenSigVtEn" SG_ 519 parameters_invalid_H_b7_4 "TRUE";
BA_ "GenSigVtName" SG_ 519 parameters_invalid_H_b7_4 "VtSig_parameters_invalid_H_b7_4";
BA_ "GenSigCmt" SG_ 519 parameters_invalid_H_b7_4 "parameters_invalid_H_b7_4";
BA_ "GenSigVtEn" SG_ 519 ThermistorOutOfRange_H_b7_5 "TRUE";
BA_ "GenSigVtName" SG_ 519 ThermistorOutOfRange_H_b7_5 "VtSig_ThermistorOutOfRange_H_b7_5";
BA_ "GenSigCmt" SG_ 519 ThermistorOutOfRange_H_b7_5 "ThermistorOutOfRange_H_b7_5";
BA_ "GenSigVtEn" SG_ 519 BatteryHighFault_H_b7_6 "TRUE";
BA_ "GenSigVtName" SG_ 519 BatteryHighFault_H_b7_6 "VtSig_BatteryHighFault_H_b7_6";
BA_ "GenSigCmt" SG_ 519 BatteryHighFault_H_b7_6 "Battery High Fault_H_b7_6";
BA_ "GenSigVtEn" SG_ 519 BatteryLowFault_H_b7_7 "TRUE";
BA_ "GenSigVtName" SG_ 519 BatteryLowFault_H_b7_7 "VtSig_BatteryLowFault_H_b7_7";
BA_ "GenSigCmt" SG_ 519 BatteryLowFault_H_b7_7 "Battery Low Fault";
BA_ "GenSigVtEn" SG_ 519 VFPCoreDumpFault_H_b6_0 "TRUE";
BA_ "GenSigVtName" SG_ 519 VFPCoreDumpFault_H_b6_0 "VtSig_VFPCoreDumpFault_H_b6_0";
BA_ "GenSigCmt" SG_ 519 VFPCoreDumpFault_H_b6_0 "VFPCoreDumpFault_H_b6_0";
BA_ "GenSigCmt" SG_ 519 DDROverTemp_H_b6_1 "Reserved";
BA_ "GenSigVtEn" SG_ 519 BusOffPCAN_H_b6_3 "TRUE";
BA_ "GenSigVtName" SG_ 519 BusOffPCAN_H_b6_3 "VtSig_BusOffPCAN_H_b6_3";
BA_ "GenSigCmt" SG_ 519 BusOffPCAN_H_b6_3 "Bus off PCAN";
BA_ "GenSigVtEn" SG_ 519 init_vdi_failure_H_b6_5 "TRUE";
BA_ "GenSigVtName" SG_ 519 init_vdi_failure_H_b6_5 "VtSig_init_vdi_failure_H_b6_5";
BA_ "GenSigCmt" SG_ 519 init_vdi_failure_H_b6_5 "init_vdi_failure_H_b6_5";
BA_ "GenSigVtEn" SG_ 519 init_I2C_failure_H_b6_6 "TRUE";
BA_ "GenSigVtName" SG_ 519 init_I2C_failure_H_b6_6 "VtSig_init_I2C_failure_H_b6_6";
BA_ "GenSigCmt" SG_ 519 init_I2C_failure_H_b6_6 "init_I2C_failure_H_b6_6";
BA_ "GenSigVtEn" SG_ 519 grab_no_free_header_failure_H_b6 "TRUE";
BA_ "GenSigVtName" SG_ 519 grab_no_free_header_failure_H_b6 "VtSig_grab_no_free_header_fail_H_b6_7";
BA_ "GenSigCmt" SG_ 519 grab_no_free_header_failure_H_b6 "grab_no_free_header_failure";
BA_ "SystemSignalLongSymbol" SG_ 519 grab_no_free_header_failure_H_b6 "grab_no_free_header_failure_H_b6_7";
BA_ "GenSigVtEn" SG_ 519 HostSpiCRC_H_b5_0 "TRUE";
BA_ "GenSigVtName" SG_ 519 HostSpiCRC_H_b5_0 "VtSig_HostSpiCRC_H_b5_0";
BA_ "GenSigCmt" SG_ 519 HostSpiCRC_H_b5_0 "HostSpiCRC_H_b5_0";
BA_ "GenSigVtEn" SG_ 519 VFPSpiFrameFormatError_H_b5_1 "TRUE";
BA_ "GenSigVtName" SG_ 519 VFPSpiFrameFormatError_H_b5_1 "VtSig_VFPSpiFrameFormatError_H_b5_1";
BA_ "GenSigCmt" SG_ 519 VFPSpiFrameFormatError_H_b5_1 "VFPSpiFrameFormatError_H_b5_1";
BA_ "GenSigVtEn" SG_ 519 VFPSpiMsgFormatError_H_b5_2 "TRUE";
BA_ "GenSigVtName" SG_ 519 VFPSpiMsgFormatError_H_b5_2 "VtSig_VFPSpiMsgFormalError_H_b5_2";
BA_ "GenSigCmt" SG_ 519 VFPSpiMsgFormatError_H_b5_2 "VFPSpiMsgFormatError_H_b5_2";
BA_ "GenSigVtEn" SG_ 519 VFPSpiMsgTimeout_H_b5_3 "TRUE";
BA_ "GenSigVtName" SG_ 519 VFPSpiMsgTimeout_H_b5_3 "VtSig_VFPSpiMsgTimeout_H_b5_3";
BA_ "GenSigCmt" SG_ 519 VFPSpiMsgTimeout_H_b5_3 "VFPSpiMsgTimeout_H_b5_3";
BA_ "GenSigVtEn" SG_ 519 VFPModeFault_H_b5_4 "TRUE";
BA_ "GenSigVtName" SG_ 519 VFPModeFault_H_b5_4 "VtSig_VFPModeFault_H_b5_4";
BA_ "GenSigCmt" SG_ 519 VFPModeFault_H_b5_4 "VFPModeFault_H_b5_4";
BA_ "GenSigVtEn" SG_ 519 VFPSpiCRC_H_b5_5 "TRUE";
BA_ "GenSigVtName" SG_ 519 VFPSpiCRC_H_b5_5 "VtSig_VFPSpiCRC_H_b5_5";
BA_ "GenSigCmt" SG_ 519 VFPSpiCRC_H_b5_5 "VFPSpiCRC_H_b5_5";
BA_ "GenSigVtEn" SG_ 519 SpiIpcCommReset_H_b5_6 "TRUE";
BA_ "GenSigVtName" SG_ 519 SpiIpcCommReset_H_b5_6 "VtSig_SpiIpcCommReset_H_b5_6";
BA_ "GenSigCmt" SG_ 519 SpiIpcCommReset_H_b5_6 "SpiIpcCommReset_H_b5_6";
BA_ "GenSigVtEn" SG_ 519 VFPInitTimeout_H_b5_7 "TRUE";
BA_ "GenSigVtName" SG_ 519 VFPInitTimeout_H_b5_7 "VtSig_VFPInitTimeout_H_b5_7";
BA_ "GenSigCmt" SG_ 519 VFPInitTimeout_H_b5_7 "VFPInitTimeout_H_b5_7";
BA_ "GenSigVtEn" SG_ 519 v2_8_ImagerInterfaceFault_H_b4_0 "TRUE";
BA_ "GenSigVtName" SG_ 519 v2_8_ImagerInterfaceFault_H_b4_0 "VtSig_v2.8_ImagerInterfaceFault_H_b4_0";
BA_ "GenSigCmt" SG_ 519 v2_8_ImagerInterfaceFault_H_b4_0 "2.8V_ImagerInterfaceFault_H_b4_0";
BA_ "GenSigVtEn" SG_ 519 v1_8_SupplyOutOfRangeFault_H_b4_ "TRUE";
BA_ "GenSigVtName" SG_ 519 v1_8_SupplyOutOfRangeFault_H_b4_ "VtSig_v1_8_SupplyOutOfRangeFault_H_b4_1";
BA_ "GenSigCmt" SG_ 519 v1_8_SupplyOutOfRangeFault_H_b4_ "1.8 Supply out of range Fault";
BA_ "SystemSignalLongSymbol" SG_ 519 v1_8_SupplyOutOfRangeFault_H_b4_ "v1_8_SupplyOutOfRangeFault_H_b4_1";
BA_ "GenSigVtEn" SG_ 519 v1_2_SupplyOutOfRangeFault_H_b4_ "TRUE";
BA_ "GenSigVtName" SG_ 519 v1_2_SupplyOutOfRangeFault_H_b4_ "VtSig_v1_2_SupplyOutOfRangeFault_H_b4_2";
BA_ "GenSigCmt" SG_ 519 v1_2_SupplyOutOfRangeFault_H_b4_ "1.2 Supply out of range Fault";
BA_ "SystemSignalLongSymbol" SG_ 519 v1_2_SupplyOutOfRangeFault_H_b4_ "v1_2_SupplyOutOfRangeFault_H_b4_2";
BA_ "GenSigVtEn" SG_ 519 HostSpiFrameFormatError_H_b4_3 "TRUE";
BA_ "GenSigVtName" SG_ 519 HostSpiFrameFormatError_H_b4_3 "VtSig_HostSpiFrameFormatError_H_b4_3";
BA_ "GenSigCmt" SG_ 519 HostSpiFrameFormatError_H_b4_3 "HostSpiFrameFormatError_H_b4_3";
BA_ "GenSigVtEn" SG_ 519 HostSpiMsgFormatError_H_b4_4 "TRUE";
BA_ "GenSigVtName" SG_ 519 HostSpiMsgFormatError_H_b4_4 "VtSig_HostSpiMsgFomatError_H_b4_4";
BA_ "GenSigCmt" SG_ 519 HostSpiMsgFormatError_H_b4_4 "HostSpiMsgFormatError_H_b4_4";
BA_ "GenSigVtEn" SG_ 519 HostSpiMsgTimeout_H_b4_5 "TRUE";
BA_ "GenSigVtName" SG_ 519 HostSpiMsgTimeout_H_b4_5 "VtSig_HostSpiMsgTimeout_H_b4_5";
BA_ "GenSigCmt" SG_ 519 HostSpiMsgTimeout_H_b4_5 "HostSpiMsgTimeout_H_b4_5";
BA_ "GenSigVtEn" SG_ 519 SPIVersionMismatch_H_b4_6 "TRUE";
BA_ "GenSigVtName" SG_ 519 SPIVersionMismatch_H_b4_6 "VtSig_SPIVersionMismatch_H_b4_6";
BA_ "GenSigCmt" SG_ 519 SPIVersionMismatch_H_b4_6 "Control Module Software #3 not programmed";
BA_ "GenSigVtEn" SG_ 519 HostSpiTxError_H_b4_7 "TRUE";
BA_ "GenSigVtName" SG_ 519 HostSpiTxError_H_b4_7 "VtSig_HostSpiTxError_H_b4_7";
BA_ "GenSigCmt" SG_ 519 HostSpiTxError_H_b4_7 "HostSpiTxError_H_b4_7";
BA_ "GenSigCmt" SG_ 519 VFPBootOverTemp_H_b3_0 "Reserved";
BA_ "GenSigVtEn" SG_ 519 HostRAMECC_H_b3_1 "TRUE";
BA_ "GenSigVtName" SG_ 519 HostRAMECC_H_b3_1 "VtSig_HostRAMECC";
BA_ "GenSigCmt" SG_ 519 HostRAMECC_H_b3_1 "Host RAM ECC [continuous]";
BA_ "GenSigVtEn" SG_ 519 HostInstructionSetCheckFault_H_b "TRUE";
BA_ "GenSigVtName" SG_ 519 HostInstructionSetCheckFault_H_b "VtSig_HostInstructionSetCheckF_H_b3_2";
BA_ "GenSigCmt" SG_ 519 HostInstructionSetCheckFault_H_b "Host Instruction Set Check Fault";
BA_ "SystemSignalLongSymbol" SG_ 519 HostInstructionSetCheckFault_H_b "HostInstructionSetCheckFault_H_b3_2";
BA_ "GenSigVtEn" SG_ 519 VfpBistMemRFlt_H_b3_3 "TRUE";
BA_ "GenSigVtName" SG_ 519 VfpBistMemRFlt_H_b3_3 "VtSig_VfpBistMemRFlt";
BA_ "GenSigCmt" SG_ 519 VfpBistMemRFlt_H_b3_3 "VfpBistMemRFlt   [vfp+flr]";
BA_ "GenSigVtEn" SG_ 519 HostOscillatorStopped_H_b3_4 "TRUE";
BA_ "GenSigVtName" SG_ 519 HostOscillatorStopped_H_b3_4 "VtSig_HostOscillatorStopped";
BA_ "GenSigCmt" SG_ 519 HostOscillatorStopped_H_b3_4 "HostOscillatorStopped";
BA_ "GenSigVtEn" SG_ 519 HostStackOverflowFault_H_b3_5 "TRUE";
BA_ "GenSigVtName" SG_ 519 HostStackOverflowFault_H_b3_5 "VtSig_HostStackoverflowFault_H_b3_5";
BA_ "GenSigCmt" SG_ 519 HostStackOverflowFault_H_b3_5 "HostStackOverflowFault_H_b3_5";
BA_ "GenSigVtEn" SG_ 519 HostCOPFault_H_b3_6 "TRUE";
BA_ "GenSigVtName" SG_ 519 HostCOPFault_H_b3_6 "VtSig_HostCOPFault_H_b3_6";
BA_ "GenSigCmt" SG_ 519 HostCOPFault_H_b3_6 "Host COP Fault";
BA_ "GenSigVtEn" SG_ 519 v5_0_SupplyOutOfRangeFault_H_b3_ "TRUE";
BA_ "GenSigVtName" SG_ 519 v5_0_SupplyOutOfRangeFault_H_b3_ "VtSig_v5_0_SupplyOutOfRangeFault_H_b3_7";
BA_ "GenSigCmt" SG_ 519 v5_0_SupplyOutOfRangeFault_H_b3_ "5.0 Supply out of range Fault";
BA_ "SystemSignalLongSymbol" SG_ 519 v5_0_SupplyOutOfRangeFault_H_b3_ "v5_0_SupplyOutOfRangeFault_H_b3_7";
BA_ "GenSigVtEn" SG_ 519 VfpDDRFlt_H_b2_0 "TRUE";
BA_ "GenSigVtName" SG_ 519 VfpDDRFlt_H_b2_0 "VtSig_VfpDDRFlt_H_b2_0";
BA_ "GenSigCmt" SG_ 519 VfpDDRFlt_H_b2_0 "VfpDDRFlt_H_b2_0   [vfp+flr]";
BA_ "GenSigVtEn" SG_ 519 DdrRamCrc_H_b2_1 "TRUE";
BA_ "GenSigVtName" SG_ 519 DdrRamCrc_H_b2_1 "VtSig_DdrRamCrc_H_b2_1";
BA_ "GenSigCmt" SG_ 519 DdrRamCrc_H_b2_1 "DdrRamCrc_H_b2_1  [vfp+flr]";
BA_ "GenSigVtEn" SG_ 519 VfpBootFlt_H_b2_2 "TRUE";
BA_ "GenSigVtName" SG_ 519 VfpBootFlt_H_b2_2 "VtSig_VfpBootFlt_H_b2_2";
BA_ "GenSigCmt" SG_ 519 VfpBootFlt_H_b2_2 "VfpBootFlt_H_b2_2   [vfp+flr]";
BA_ "GenSigVtEn" SG_ 519 VfpCoreFlt_H_b2_3 "TRUE";
BA_ "GenSigVtName" SG_ 519 VfpCoreFlt_H_b2_3 "VtSig_VfpCoreFlt_H_b2_3";
BA_ "GenSigCmt" SG_ 519 VfpCoreFlt_H_b2_3 "VfpCoreFlt_H_b2_3   [vfp+flr]";
BA_ "GenSigVtEn" SG_ 519 HostCodeFlashECC_H_b2_4 "TRUE";
BA_ "GenSigVtName" SG_ 519 HostCodeFlashECC_H_b2_4 "VtSig_HostCodeFlashECC_H_b2_4";
BA_ "GenSigCmt" SG_ 519 HostCodeFlashECC_H_b2_4 "Host Code Flash ECC  [continuous]";
BA_ "GenSigVtEn" SG_ 519 HostDataFlashECC_H_b2_5 "TRUE";
BA_ "GenSigVtName" SG_ 519 HostDataFlashECC_H_b2_5 "VtSig_HostDataFlashECC_H_b2_5";
BA_ "GenSigCmt" SG_ 519 HostDataFlashECC_H_b2_5 "Host Data Flash ECC  [continuous]";
BA_ "GenSigVtEn" SG_ 519 SerialFlashPowerUpFail_H_b2_6 "TRUE";
BA_ "GenSigVtName" SG_ 519 SerialFlashPowerUpFail_H_b2_6 "VtSig_SerialFlashPowerUpFail_H_b2_6";
BA_ "GenSigCmt" SG_ 519 SerialFlashPowerUpFail_H_b2_6 "SerialFlashPowerUpFail_H_b2_6";
BA_ "GenSigVtEn" SG_ 519 HostRamFault_H_b2_7 "TRUE";
BA_ "GenSigVtName" SG_ 519 HostRamFault_H_b2_7 "VtSig_HostRamFault_H_b2_7";
BA_ "GenSigCmt" SG_ 519 HostRamFault_H_b2_7 "HostRamFault [start up]";
BA_ "GenSigVtEn" SG_ 519 KAMChecksumFault_H_b1_0 "TRUE";
BA_ "GenSigVtName" SG_ 519 KAMChecksumFault_H_b1_0 "VtSig_KAMChecksumFault_H_b1_0";
BA_ "GenSigCmt" SG_ 519 KAMChecksumFault_H_b1_0 "KAMChecksumFault_H_b1_0";
BA_ "GenSigVtEn" SG_ 519 HostApplicationCRC_H_b1_1 "TRUE";
BA_ "GenSigVtName" SG_ 519 HostApplicationCRC_H_b1_1 "VtSig_HostApplicationCRC_H_b1_1";
BA_ "GenSigCmt" SG_ 519 HostApplicationCRC_H_b1_1 "HostApplicationCRC_H_b1_1";
BA_ "GenSigVtEn" SG_ 519 HostCalibrationCRC_H_b1_2 "TRUE";
BA_ "GenSigVtName" SG_ 519 HostCalibrationCRC_H_b1_2 "VtSig_HostCalibrationCRC_H_b1_2";
BA_ "GenSigCmt" SG_ 519 HostCalibrationCRC_H_b1_2 "HostCalibrationCRC_H_b1_2";
BA_ "GenSigVtEn" SG_ 519 VFPApplicationChecksum_H_b1_3 "TRUE";
BA_ "GenSigVtName" SG_ 519 VFPApplicationChecksum_H_b1_3 "VtSig_VFPApplicationChecksum_H_b1_3";
BA_ "GenSigCmt" SG_ 519 VFPApplicationChecksum_H_b1_3 "VFPApplicationChecksum_H_b1_3";
BA_ "GenSigVtEn" SG_ 519 VFPCalibrationChecksum_H_b1_4 "TRUE";
BA_ "GenSigVtName" SG_ 519 VFPCalibrationChecksum_H_b1_4 "VtSig_VFPCalibrationChecksum_H_b1_4";
BA_ "GenSigCmt" SG_ 519 VFPCalibrationChecksum_H_b1_4 "VFPCalibrationChecksum_H_b1_4";
BA_ "GenSigVtEn" SG_ 519 HostCalComplAndCompat_H_b1_5 "TRUE";
BA_ "GenSigVtName" SG_ 519 HostCalComplAndCompat_H_b1_5 "VtSig_HostCalCompleteAndComp";
BA_ "GenSigCmt" SG_ 519 HostCalComplAndCompat_H_b1_5 "HostCalComplAndCompat_H_b1_5";
BA_ "GenSigVtEn" SG_ 519 VFPAppComplAndCompat_H_b1_6 "TRUE";
BA_ "GenSigVtName" SG_ 519 VFPAppComplAndCompat_H_b1_6 "VtSig_VFPAppCompleteAndComp_H_b1_6";
BA_ "GenSigCmt" SG_ 519 VFPAppComplAndCompat_H_b1_6 "VFPAppComplAndCompat_H_b1_6";
BA_ "GenSigVtEn" SG_ 519 InvalidAHBCSensParams_H_b1_7 "TRUE";
BA_ "GenSigVtName" SG_ 519 InvalidAHBCSensParams_H_b1_7 "VtSig_InvalidAHBCSensParams_H_b1_7";
BA_ "GenSigCmt" SG_ 519 InvalidAHBCSensParams_H_b1_7 "InvalidAHBCSensParams_H_b1_7";
BA_ "GenSigVtEn" SG_ 519 VFPCalComplCompatSWP3_H_b0_1 "TRUE";
BA_ "GenSigVtName" SG_ 519 VFPCalComplCompatSWP3_H_b0_1 "VtSig_VFPCalComplCompatSWP3_H_b0_1";
BA_ "GenSigCmt" SG_ 519 VFPCalComplCompatSWP3_H_b0_1 "VFPCalComplCompatSWP3_H_b0_1";
BA_ "GenSigVtEn" SG_ 519 VFPCalComplCompatSWP5_H_b0_2 "TRUE";
BA_ "GenSigVtName" SG_ 519 VFPCalComplCompatSWP5_H_b0_2 "VtSig_VFPCalComplCompatSWP5_H_b0_2";
BA_ "GenSigCmt" SG_ 519 VFPCalComplCompatSWP5_H_b0_2 "VFPCalComplCompatSWP5_H_b0_2";
BA_ "GenSigVtEn" SG_ 519 SystemOverTemperature_H_b0_3 "TRUE";
BA_ "GenSigVtName" SG_ 519 SystemOverTemperature_H_b0_3 "VtSig_SystemOverTemperature_H_b0_3";
BA_ "GenSigCmt" SG_ 519 SystemOverTemperature_H_b0_3 "SystemOverTemperature_H_b0_3";
BA_ "GenSigVtEn" SG_ 519 OnBdThermOvrTemp_H_b0_4 "TRUE";
BA_ "GenSigVtName" SG_ 519 OnBdThermOvrTemp_H_b0_4 "VtSig_OnBdThermOvrTemp_H_b0_4";
BA_ "GenSigCmt" SG_ 519 OnBdThermOvrTemp_H_b0_4 "OnBdThermOvrTemp_H_b0_4";
BA_ "GenSigVtEn" SG_ 519 VFPMIPSOverTemp_H_b0_5 "TRUE";
BA_ "GenSigVtName" SG_ 519 VFPMIPSOverTemp_H_b0_5 "VtSig_VFPMIPSOverTemp_H_b0_5";
BA_ "GenSigCmt" SG_ 519 VFPMIPSOverTemp_H_b0_5 "VFPMIPSOverTemp_H_b0_5";
BA_ "GenSigVtEn" SG_ 519 VFPVMPOverTemp_H_b0_6 "TRUE";
BA_ "GenSigVtName" SG_ 519 VFPVMPOverTemp_H_b0_6 "VtSig_VFPVMPOverTemp_H_b0_6";
BA_ "GenSigCmt" SG_ 519 VFPVMPOverTemp_H_b0_6 "VFPVMPOverTemp_H_b0_6";
BA_ "GenSigVtEn" SG_ 519 VFPImagerOverTemp_H_b0_7 "TRUE";
BA_ "GenSigVtName" SG_ 519 VFPImagerOverTemp_H_b0_7 "VtSig_VFPImageroverTemp_H_b0_7";
BA_ "GenSigCmt" SG_ 519 VFPImagerOverTemp_H_b0_7 "VFPImagerOverTemp_H_b0_7";
BA_ "SystemSignalLongSymbol" SG_ 516 PCAN_370_BrkSyExHldCpbFld_A_b20_ "PCAN_370_BrkSyExHldCpbFld_A_b20_5";
BA_ "SystemSignalLongSymbol" SG_ 515 PB_1E1_CrsSpdLmtrSwStPVal_A_b1E_ "PB_1E1_CrsSpdLmtrSwStPVal_A_b1E_6";
BA_ "SystemSignalLongSymbol" SG_ 515 PB_0F1_BrkAppSnsrHmPosLrnd_A_b1C "PB_0F1_BrkAppSnsrHmPosLrnd_A_b1C_3";
BA_ "SystemSignalLongSymbol" SG_ 514 PB_1C4_AccPdlOvAtvProtVal_A_b14_ "PB_1C4_AccPdlOvAtvProtVal_A_b14_6";
BA_ "SystemSignalLongSymbol" SG_ 514 PB_1C4_AutBrkAccActPsPVal_A_b14_ "PB_1C4_AutBrkAccActPsPVal_A_b14_7";
BA_ "GenSigVtEn" SG_ 514 PB_2C3_EngTrqMinExtRngV_A_b13_0 "TRUE";
BA_ "GenSigVtName" SG_ 514 PB_2C3_EngTrqMinExtRngV_A_b13_0 "VtSig_VehOverGnd_V_EST_QF_ErA";
BA_ "GenSigCmt" SG_ 514 PB_2C3_EngTrqMinExtRngV_A_b13_0 "VehOverGnd_V_EST QF Error (ABS)";
BA_ "GenSigVtEn" SG_ 514 PB_0C9_PT_BPdDscrtInpStV_A_b13_1 "TRUE";
BA_ "GenSigVtName" SG_ 514 PB_0C9_PT_BPdDscrtInpStV_A_b13_1 "VtSig_VehYawComp_W_Actl_QF_ErA";
BA_ "GenSigCmt" SG_ 514 PB_0C9_PT_BPdDscrtInpStV_A_b13_1 "VehYawComp_W_Actl QF Error (ABS)";
BA_ "GenSigVtEn" SG_ 514 PB_1F5_TopTrvICltSwActV_A_b13_2 "TRUE";
BA_ "GenSigVtName" SG_ 514 PB_1F5_TopTrvICltSwActV_A_b13_2 "VtSig_PB_1F5_TopTrvICltSwActV_A_b13_2";
BA_ "GenSigCmt" SG_ 514 PB_1F5_TopTrvICltSwActV_A_b13_2 "PB_1F5_TopTrvICltSwActV_H_b13_2 (ABS)";
BA_ "GenSigVtEn" SG_ 514 PB_1F5_TransEstGearV_A_b13_3 "TRUE";
BA_ "GenSigVtName" SG_ 514 PB_1F5_TransEstGearV_A_b13_3 "VtSig_PB_1F5_TransEstGearV_A_b13_3";
BA_ "GenSigCmt" SG_ 514 PB_1F5_TransEstGearV_A_b13_3 "PB_1F5_TransEstGearV_A_b13_3 (ABS)";
BA_ "GenSigVtEn" SG_ 514 PB_1F5_TrnsEngdStateV_A_b13_4 "TRUE";
BA_ "GenSigVtName" SG_ 514 PB_1F5_TrnsEngdStateV_A_b13_4 "VtSig_CcAslButtnDeny_B_Actl_QFEA";
BA_ "GenSigCmt" SG_ 514 PB_1F5_TrnsEngdStateV_A_b13_4 "CcAslButtnDeny_B_Actl QF Error (SCCM)";
BA_ "GenSigVtEn" SG_ 514 PB_3E9_VehSpdAvgDrvnV_A_b13_5 "TRUE";
BA_ "GenSigVtName" SG_ 514 PB_3E9_VehSpdAvgDrvnV_A_b13_5 "VtSig_LaSwtchPos_D_Stat_QF_ErA";
BA_ "GenSigCmt" SG_ 514 PB_3E9_VehSpdAvgDrvnV_A_b13_5 "LaSwtchPos_D_Stat QF Error (SCCM)";
BA_ "GenSigVtEn" SG_ 514 PB_3E9_VehSpdAvgNDrvnV_A_b13_6 "TRUE";
BA_ "GenSigVtName" SG_ 514 PB_3E9_VehSpdAvgNDrvnV_A_b13_6 "VtSig_LaActDeny_B_Stat_QF_ErA";
BA_ "GenSigCmt" SG_ 514 PB_3E9_VehSpdAvgNDrvnV_A_b13_6 "LaActDeny_B_Actl QF Error (SCCM)";
BA_ "GenSigVtEn" SG_ 514 PB_1C4_ACCATCS_RqStat_A_b13_7 "TRUE";
BA_ "GenSigVtName" SG_ 514 PB_1C4_ACCATCS_RqStat_A_b13_7 "VtSig_VehYaw_W_Actl_QF_ErA";
BA_ "GenSigCmt" SG_ 514 PB_1C4_ACCATCS_RqStat_A_b13_7 "VehYaw_W_Actl QF Error (RCM)";
BA_ "GenSigVtEn" SG_ 514 PB_4F3_PPEIPTCfg2Miss_A_b12_0 "TRUE";
BA_ "GenSigCmt" SG_ 514 PB_4F3_PPEIPTCfg2Miss_A_b12_0 "SCCM_5 Missing Msg (LaSwtchPos_D_Stat)";
BA_ "GenSigVtName" SG_ 514 PB_4F3_PPEIPTCfg2Miss_A_b12_0 "VtSig_PB_4F3_PPEIPTCfg2Miss_A_b12_0";
BA_ "GenSigVtEn" SG_ 514 PB_1C4_ABAAPS_AccPosV_A_b12_1 "TRUE";
BA_ "GenSigCmt" SG_ 514 PB_1C4_ABAAPS_AccPosV_A_b12_1 "PB_1C4_ABAAPS_AccPosV_A_b12_1 (DrQltyDrv_D_StatGsm)";
BA_ "GenSigVtName" SG_ 514 PB_1C4_ABAAPS_AccPosV_A_b12_1 "VtSig_PB_1C4_ABAAPS_AccPosV_A_b12_1";
BA_ "GenSigVtEn" SG_ 514 PB_1C5_DrvIAxlTrqMaxV_A_b12_2 "TRUE";
BA_ "GenSigCmt" SG_ 514 PB_1C5_DrvIAxlTrqMaxV_A_b12_2 "ApedposPcActl_D_Qf QF Error (ECM)";
BA_ "GenSigVtName" SG_ 514 PB_1C5_DrvIAxlTrqMaxV_A_b12_2 "VtSig_ApedposPcActl_D_Qf_QF_ErA";
BA_ "GenSigVtEn" SG_ 514 PB_1C5_DrvIAxlTrqMinV_A_b12_3 "TRUE";
BA_ "GenSigVtName" SG_ 514 PB_1C5_DrvIAxlTrqMinV_A_b12_3 "VtSig_GearRvrse_D_Actl_QF_ErA";
BA_ "GenSigCmt" SG_ 514 PB_1C5_DrvIAxlTrqMinV_A_b12_3 "GearRvrse_D_Actl QF Error(ECM)";
BA_ "GenSigVtEn" SG_ 514 PB_1C5_DrvIntndAxlTrqV_A_b12_4 "TRUE";
BA_ "GenSigVtName" SG_ 514 PB_1C5_DrvIntndAxlTrqV_A_b12_4 "VtSig_VehVActlEng_D_Qf_QF_ErA";
BA_ "GenSigCmt" SG_ 514 PB_1C5_DrvIntndAxlTrqV_A_b12_4 "VehVActlEng_D_Qf QF Error(ECM)";
BA_ "GenSigVtEn" SG_ 514 PB_1C3_EngTrqActExtRngV_A_b12_5 "TRUE";
BA_ "GenSigVtName" SG_ 514 PB_1C3_EngTrqActExtRngV_A_b12_5 "VtSig_PB_1C3_EngTrqActExtRngV_A_b12_5";
BA_ "GenSigCmt" SG_ 514 PB_1C3_EngTrqActExtRngV_A_b12_5 "CcStat_D_Actl QF Error (ECM)";
BA_ "GenSigVtEn" SG_ 514 PB_1C3_EngTqDrRqExtRngV_A_b12_6 "TRUE";
BA_ "GenSigVtName" SG_ 514 PB_1C3_EngTqDrRqExtRngV_A_b12_6 "VtSig_GearLvrPos_D_Actl_QF_ErA";
BA_ "GenSigCmt" SG_ 514 PB_1C3_EngTqDrRqExtRngV_A_b12_6 "GearLvrPos_D_Actl QF Error (TCM)";
BA_ "GenSigVtEn" SG_ 514 PB_2C3_EngTrqMaxExtRngV_A_b12_7 "TRUE";
BA_ "GenSigVtName" SG_ 514 PB_2C3_EngTrqMaxExtRngV_A_b12_7 "VtSig_SteWhlCompAnEst_D_Qf_QFEA";
BA_ "GenSigCmt" SG_ 514 PB_2C3_EngTrqMaxExtRngV_A_b12_7 "SteWhlCompAnEst_D_Qf QF Error (ABS)";
BA_ "GenSigVtEn" SG_ 514 PB_0C9_PPEIEngGSt1Miss_A_b11_0 "TRUE";
BA_ "GenSigCmt" SG_ 514 PB_0C9_PPEIEngGSt1Miss_A_b11_0 "IPC_2 Missing Msg (MsgCntrDsplyOp_D_Rq)";
BA_ "GenSigVtName" SG_ 514 PB_0C9_PPEIEngGSt1Miss_A_b11_0 "VtSig_PB_2C3_PPEIEngTorqMiss_A_b11_0";
BA_ "GenSigVtEn" SG_ 514 PB_1C3_PPEIEngTrqSt2Miss_A_b11_1 "TRUE";
BA_ "GenSigCmt" SG_ 514 PB_1C3_PPEIEngTrqSt2Miss_A_b11_1 "HUD Missing Msg (Hud_B_Falt)";
BA_ "GenSigVtName" SG_ 514 PB_1C3_PPEIEngTrqSt2Miss_A_b11_1 "VtSig_PB_3E9_PPEIVehSpdMiss_A_b11_1";
BA_ "GenSigVtEn" SG_ 514 PB_1C4_PPEITrqReqStMiss_A_b11_2 "TRUE";
BA_ "GenSigCmt" SG_ 514 PB_1C4_PPEITrqReqStMiss_A_b11_2 "SECM Missing Msg (LaActDeny_B_Actl)";
BA_ "GenSigVtName" SG_ 514 PB_1C4_PPEITrqReqStMiss_A_b11_2 "VtSig_SSysDisabledInfoStored_A";
BA_ "GenSigVtEn" SG_ 514 PB_1C5_PPEIDrIAxTqStMiss_A_b11_3 "TRUE";
BA_ "GenSigCmt" SG_ 514 PB_1C5_PPEIDrIAxTqStMiss_A_b11_3 "PSCM Missing Msg (LaActDeny_B_Actl)";
BA_ "GenSigVtName" SG_ 514 PB_1C5_PPEIDrIAxTqStMiss_A_b11_3 "VtSig_PB_4F3_PPEIPTConfigMiss_A_b11_3";
BA_ "GenSigVtEn" SG_ 514 PB_1F5_PPEITrGenSt2Miss_A_b11_4 "TRUE";
BA_ "GenSigCmt" SG_ 514 PB_1F5_PPEITrGenSt2Miss_A_b11_4 "SCCM Missing Msg (CcAslButtnDeny_B_Actl)";
BA_ "GenSigVtName" SG_ 514 PB_1F5_PPEITrGenSt2Miss_A_b11_4 "VtSig_PB_1C4_ABAAPSAccPosV_A_b11_4";
BA_ "GenSigVtEn" SG_ 514 PB_2C3_PPEIEngTrqSt3Miss_A_b11_5 "TRUE";
BA_ "GenSigCmt" SG_ 514 PB_2C3_PPEIEngTrqSt3Miss_A_b11_5 "SCCM_2 Missing Msg (SteWhlRelInit2_An_Sns)";
BA_ "GenSigVtName" SG_ 514 PB_2C3_PPEIEngTrqSt3Miss_A_b11_5 "VtSig_PB_1C5_DrvIntndAxlTrqMaxV_A_b11_5";
BA_ "GenSigVtEn" SG_ 514 PB_3E9_PPEIVehSpdDisMiss_A_b11_6 "TRUE";
BA_ "GenSigCmt" SG_ 514 PB_3E9_PPEIVehSpdDisMiss_A_b11_6 "SCCM_3 Missing Msg (TurnLghtSwtch_D_Stat)";
BA_ "GenSigVtName" SG_ 514 PB_3E9_PPEIVehSpdDisMiss_A_b11_6 "VtSig_PB_1C5_DrvIntndAxlTrqMinV_A_b11_6";
BA_ "GenSigVtEn" SG_ 514 PB_4F1_PPEIPTConfMiss_A_b11_7 "TRUE";
BA_ "GenSigCmt" SG_ 514 PB_4F1_PPEIPTConfMiss_A_b11_7 "SCCM_4 Missing Msg (LaActDeny_B_Actl)";
BA_ "GenSigVtName" SG_ 514 PB_4F1_PPEIPTConfMiss_A_b11_7 "VtSig_PB_1C5_DrvIntndAxlTrqV_A_b11_7";
BA_ "GenSigVtEn" SG_ 514 MRRPCANIntComp_A_b10_0 "TRUE";
BA_ "GenSigVtName" SG_ 514 MRRPCANIntComp_A_b10_0 "VtSig_MRRPCANIntComp_A_b10_0";
BA_ "GenSigCmt" SG_ 514 MRRPCANIntComp_A_b10_0 "MRRPCANIntComp_A_b10_0";
BA_ "GenSigVtEn" SG_ 514 PCAN_330_IMULonAccSecAval_A_b10_ "TRUE";
BA_ "GenSigCmt" SG_ 514 PCAN_330_IMULonAccSecAval_A_b10_ "RCM  Missing Message (VehYaw_W_Actl)";
BA_ "GenSigVtName" SG_ 514 PCAN_330_IMULonAccSecAval_A_b10_ "VtSig_PCAN_330_IMUYawRtSecAval_A_b10_1";
BA_ "SystemSignalLongSymbol" SG_ 514 PCAN_330_IMULonAccSecAval_A_b10_ "PCAN_330_IMULonAccSecAval_A_b10_1";
BA_ "GenSigVtEn" SG_ 514 PCAN_340_IMUYawRtSecAval_A_b10_2 "TRUE";
BA_ "GenSigCmt" SG_ 514 PCAN_340_IMUYawRtSecAval_A_b10_2 "RCM_2 Missing Msg (VehLat2_A_Actl)";
BA_ "GenSigVtName" SG_ 514 PCAN_340_IMUYawRtSecAval_A_b10_2 "VtSig_PCAN_340_IMULatAccSecAval_A_b10_2";
BA_ "GenSigVtEn" SG_ 514 PCAN_340_IMULatAccSecAval_A_b10_ "TRUE";
BA_ "GenSigCmt" SG_ 514 PCAN_340_IMULatAccSecAval_A_b10_ "RCM_3 Missing Msg (VehLong2_A_Actl)";
BA_ "GenSigVtName" SG_ 514 PCAN_340_IMULatAccSecAval_A_b10_ "VtSig_PB_0C9_PPEIEngGenMiss_A_b10_3";
BA_ "SystemSignalLongSymbol" SG_ 514 PCAN_340_IMULatAccSecAval_A_b10_ "PCAN_340_IMULatAccSecAval_A_b10_3";
BA_ "GenSigVtEn" SG_ 514 PB_1E5_StrWhlAngSenTyp_A_b10_5 "TRUE";
BA_ "GenSigCmt" SG_ 514 PB_1E5_StrWhlAngSenTyp_A_b10_5 "BCM_2 Missing Msg (DrStatDrv_B_Actl)";
BA_ "GenSigVtName" SG_ 514 PB_1E5_StrWhlAngSenTyp_A_b10_5 "VtSig_PB_1C4_PPEITorqReqMiss_A_b10_5";
BA_ "GenSigVtEn" SG_ 513 FCMIndSTB_A_bF_0 "TRUE";
BA_ "GenSigVtName" SG_ 513 FCMIndSTB_A_bF_0 "VtSig_FCMIndSTB_A_bF_0";
BA_ "GenSigCmt" SG_ 513 FCMIndSTB_A_bF_0 "ECM_9 Missing Msg (Veh_V_ActlEng)";
BA_ "GenSigVtEn" SG_ 513 FCMIndSTGorOPN_A_bF_1 "TRUE";
BA_ "GenSigVtName" SG_ 513 FCMIndSTGorOPN_A_bF_1 "VtSig_FCMIndSTGorOPN_A_bF_1";
BA_ "GenSigCmt" SG_ 513 FCMIndSTGorOPN_A_bF_1 "TCM Missing Msg (GearLvrPos_D_Actl)";
BA_ "GenSigVtEn" SG_ 513 LKASwtchSTG_A_bF_2 "TRUE";
BA_ "GenSigVtName" SG_ 513 LKASwtchSTG_A_bF_2 "VtSig_LKAStchSTG_A";
BA_ "GenSigCmt" SG_ 513 LKASwtchSTG_A_bF_2 "ABS Missing Msg  (VehOverGnd_V_Est)";
BA_ "GenSigCmt" SG_ 513 MRRPCANMissingMsgHOST_A_bF_4 "MRRPCANMissingMsgHOST_A_bF_4";
BA_ "GenSigCmt" SG_ 513 MRRPCANMissingMsgVFP_A_bF_5 "MRRPCANMissingMsgVFP_A_bF_5";
BA_ "GenSigCmt" SG_ 513 MRRPCANRangeCheckVFP_A_bF_6 "MRRPCANRangeCheckVFP_A_bF_6";
BA_ "GenSigCmt" SG_ 513 MRRPCANInvalidDataVFP_A_bF_7 "MRRPCANInvalidDataVFP_A_bF_7";
BA_ "GenSigCmt" SG_ 513 VisionInternalError_A_bE_0 "VisionInternalError_A_bE_0";
BA_ "GenSigVtEn" SG_ 513 VINMismatch_A_bE_1 "TRUE";
BA_ "GenSigVtName" SG_ 513 VINMismatch_A_bE_1 "VtSig_VINMismatch_A";
BA_ "GenSigCmt" SG_ 513 VINMismatch_A_bE_1 "ECM_2 Missing Msg (GearRvrse_D_Actl)";
BA_ "GenSigVtEn" SG_ 513 ECUSWCalDataSetNotProg_A_bE_2 "TRUE";
BA_ "GenSigVtName" SG_ 513 ECUSWCalDataSetNotProg_A_bE_2 "VtSig_ECUSWCalDataSetNotProg_A";
BA_ "GenSigCmt" SG_ 513 ECUSWCalDataSetNotProg_A_bE_2 "ECM_3 Missing Msg (ApedPos_Pc_ActlArb)";
BA_ "GenSigVtEn" SG_ 513 VehConfNotProg_A_bE_3 "TRUE";
BA_ "GenSigVtName" SG_ 513 VehConfNotProg_A_bE_3 "VtSig_VehConfNotProg_A";
BA_ "GenSigCmt" SG_ 513 VehConfNotProg_A_bE_3 "ECM_4 Missing Msg (BpedDrvAppl_D_Actl)";
BA_ "GenSigVtEn" SG_ 513 VINNotProg_A_bE_4 "TRUE";
BA_ "GenSigVtName" SG_ 513 VINNotProg_A_bE_4 "VtSig_VINNotProg_A";
BA_ "GenSigCmt" SG_ 513 VINNotProg_A_bE_4 "ECM_5 Missing Msg (PrplTqMnSat_B_Actl)";
BA_ "GenSigVtEn" SG_ 513 CameraCalNotLearnt_A_bE_5 "TRUE";
BA_ "GenSigVtName" SG_ 513 CameraCalNotLearnt_A_bE_5 "VtSig_CameraCalNotLearnt_A_bE_5";
BA_ "GenSigCmt" SG_ 513 CameraCalNotLearnt_A_bE_5 "ECM_6 Missing Msg (CcOvrrdActv_B_Actl)";
BA_ "GenSigVtEn" SG_ 513 HostVCANBusOff_A_bE_6 "TRUE";
BA_ "GenSigVtName" SG_ 513 HostVCANBusOff_A_bE_6 "VtSig_HostVCANBusOff_A_bE_7";
BA_ "GenSigCmt" SG_ 513 HostVCANBusOff_A_bE_6 "ECM_8 Missing Msg (AirAmb_Te_ActlFilt)";
BA_ "GenSigVtEn" SG_ 513 SysDisabledInfoStored_A_bE_7 "TRUE";
BA_ "GenSigVtName" SG_ 513 SysDisabledInfoStored_A_bE_7 "VtSig_SysDisabledInfoStored_A";
BA_ "GenSigCmt" SG_ 513 SysDisabledInfoStored_A_bE_7 "ECM Missing Msg (AccEngStat_D_Actl)";
BA_ "GenSigCmt" SG_ 513 HostCoreSelftestFault_A_bD_0 "HostCoreSelftestFault_A_bD_0";
BA_ "GenSigCmt" SG_ 513 ECCSelfTestCheckFault_A_bD_1 "ECCSelfTestCheckFault_A_bD_1";
BA_ "GenSigCmt" SG_ 513 HostCoreExceptionFault_A_bD_2 "HostCoreExceptionFault_A_bD_2";
BA_ "GenSigCmt" SG_ 513 HostCtrConfigRegFault_A_bD_3 "HostCtrConfigRegFault_A_bD_3";
BA_ "GenSigCmt" SG_ 513 HostADCSelfTestFault_A_bD_4 "HostADCSelfTestFault_A_bD_4";
BA_ "GenSigCmt" SG_ 513 HostADCMonitorFault_A_bD_5 "HostADCMonitorFault_A_bD_5";
BA_ "GenSigCmt" SG_ 513 HostCVMResetFault_A_bD_6 "HostCVMResetFault_A_bD_6";
BA_ "GenSigCmt" SG_ 513 HostCVMSTsetFault_A_bD_7 "HostCVMSTsetFault_A_bD_7";
BA_ "GenSigVtEn" SG_ 513 AlignAdjustIncorrect_A_bC_0 "TRUE";
BA_ "GenSigVtName" SG_ 513 AlignAdjustIncorrect_A_bC_0 "VtSig_alignadjustincorr_A_bc_0";
BA_ "GenSigCmt" SG_ 513 AlignAdjustIncorrect_A_bC_0 "flr_alignadjustincorr";
BA_ "GenSigVtEn" SG_ 513 VisionRadar_Missaligned_A_bC_1 "TRUE";
BA_ "GenSigVtName" SG_ 513 VisionRadar_Missaligned_A_bC_1 "VtSig_VisionRadar_Misaligned_A_bC_1";
BA_ "GenSigCmt" SG_ 513 VisionRadar_Missaligned_A_bC_1 "flr_misalignment";
BA_ "GenSigVtEn" SG_ 513 Vision_OutOfFocus_Fault_A_bC_2 "TRUE";
BA_ "GenSigVtName" SG_ 513 Vision_OutOfFocus_Fault_A_bC_2 "VtSig_Vision_OutOfFocus_Fault_A";
BA_ "GenSigCmt" SG_ 513 Vision_OutOfFocus_Fault_A_bC_2 "Vision_OutOfFocus_Fault";
BA_ "GenSigVtEn" SG_ 513 Vision_OutOfCalibration_A_bC_3 "TRUE";
BA_ "GenSigVtName" SG_ 513 Vision_OutOfCalibration_A_bC_3 "VtSig_CameraAlignIncomplete_A";
BA_ "GenSigCmt" SG_ 513 Vision_OutOfCalibration_A_bC_3 "CameraAlignIncomplete";
BA_ "GenSigCmt" SG_ 513 HostISRConsistencyCheck_A_bC_5 "HostISRConsistencyCheck_A_bC_5";
BA_ "GenSigCmt" SG_ 513 ECCSelfTest_CF_A_bC_6 "ECCSelfTest_CF_A_bC_6";
BA_ "GenSigCmt" SG_ 513 ECCSelfTest_RAM_A_bC_7 "ECCSelfTest_RAM_A_bC_7";
BA_ "GenSigVtEn" SG_ 513 Smeared_Spots_fault_A_bB_0 "TRUE";
BA_ "GenSigVtName" SG_ 513 Smeared_Spots_fault_A_bB_0 "VtSig_Image_smearedSpots_A";
BA_ "GenSigCmt" SG_ 513 Smeared_Spots_fault_A_bB_0 "Image_smearedSpots";
BA_ "GenSigVtEn" SG_ 513 SelfGlare_fault_A_bB_1 "TRUE";
BA_ "GenSigVtName" SG_ 513 SelfGlare_fault_A_bB_1 "VtSig_Image_SelfGlare_A";
BA_ "GenSigCmt" SG_ 513 SelfGlare_fault_A_bB_1 "Image_SelfGlare";
BA_ "GenSigVtEn" SG_ 513 Low_Visibility_fault_A_bB_2 "TRUE";
BA_ "GenSigVtName" SG_ 513 Low_Visibility_fault_A_bB_2 "VtSig_Image_Low_visibility_A";
BA_ "GenSigCmt" SG_ 513 Low_Visibility_fault_A_bB_2 "Image_Low visibility";
BA_ "GenSigVtEn" SG_ 513 imager_pattern_fault_A_bB_4 "TRUE";
BA_ "GenSigVtName" SG_ 513 imager_pattern_fault_A_bB_4 "VtSig_imager_pattern_fault_A";
BA_ "GenSigCmt" SG_ 513 imager_pattern_fault_A_bB_4 "imager_pattern_fault";
BA_ "GenSigVtEn" SG_ 513 HostSWP2RAMCRCFlt_A_bB_5 "TRUE";
BA_ "GenSigVtName" SG_ 513 HostSWP2RAMCRCFlt_A_bB_5 "VtSig_HostSWP2RAMCRCFlt";
BA_ "GenSigCmt" SG_ 513 HostSWP2RAMCRCFlt_A_bB_5 "HostSWP2RAMCRCFlt";
BA_ "GenSigCmt" SG_ 513 VisionAlignIncomplete_A_bB_6 "VisionAlignIncomplete_A_bB_6";
BA_ "GenSigVtEn" SG_ 513 Full_Blockage_fault_A_bA_0 "TRUE";
BA_ "GenSigVtName" SG_ 513 Full_Blockage_fault_A_bA_0 "VtSig_vision_full_blockage_A";
BA_ "GenSigCmt" SG_ 513 Full_Blockage_fault_A_bA_0 "vision_full_blockage";
BA_ "GenSigVtEn" SG_ 513 Blurred_Image_fault_A_bA_1 "TRUE";
BA_ "GenSigVtName" SG_ 513 Blurred_Image_fault_A_bA_1 "VtSig_blur_image_failsafe_A";
BA_ "GenSigCmt" SG_ 513 Blurred_Image_fault_A_bA_1 "blur_image_failsafe";
BA_ "GenSigVtEn" SG_ 513 TD_Blockage_Fault_A_bA_2 "TRUE";
BA_ "GenSigVtName" SG_ 513 TD_Blockage_Fault_A_bA_2 "VtSig_TD_Blockage_Fault";
BA_ "GenSigCmt" SG_ 513 TD_Blockage_Fault_A_bA_2 "TD_Blockage_Fault";
BA_ "GenSigVtEn" SG_ 513 Splashes_fault_A_bA_3 "TRUE";
BA_ "GenSigVtName" SG_ 513 Splashes_fault_A_bA_3 "VtSig_Image_splashes_A";
BA_ "GenSigCmt" SG_ 513 Splashes_fault_A_bA_3 "Image_splashes";
BA_ "GenSigVtEn" SG_ 513 Low_Sun_fault_A_bA_4 "TRUE";
BA_ "GenSigVtName" SG_ 513 Low_Sun_fault_A_bA_4 "VtSig_Image_low_sun_A";
BA_ "GenSigCmt" SG_ 513 Low_Sun_fault_A_bA_4 "Image_low sun";
BA_ "GenSigVtEn" SG_ 513 Sun_Rays_faults_A_bA_5 "TRUE";
BA_ "GenSigVtName" SG_ 513 Sun_Rays_faults_A_bA_5 "VtSig_Image_SunRay_A";
BA_ "GenSigCmt" SG_ 513 Sun_Rays_faults_A_bA_5 "Image_SunRay";
BA_ "GenSigVtEn" SG_ 513 Foggy_Spots_fault_A_bA_6 "TRUE";
BA_ "GenSigVtName" SG_ 513 Foggy_Spots_fault_A_bA_6 "VtSig_Image_FoggySpot_A";
BA_ "GenSigCmt" SG_ 513 Foggy_Spots_fault_A_bA_6 "Image_FoggySpot";
BA_ "GenSigVtEn" SG_ 513 Spot_Rays_fault_A_bA_7 "TRUE";
BA_ "GenSigVtName" SG_ 513 Spot_Rays_fault_A_bA_7 "VtSig_Image_SpotRay_A";
BA_ "GenSigCmt" SG_ 513 Spot_Rays_fault_A_bA_7 "Image_SpotRay";
BA_ "GenSigCmt" SG_ 513 HostPLLStoppedFault_A_b9_0 "Reserved";
BA_ "GenSigCmt" SG_ 513 HostWatchDogSelftestFault_A_b9_1 "Reserved";
BA_ "GenSigVtEn" SG_ 513 VfpCamMalFunc_A_b9_2 "TRUE";
BA_ "GenSigVtName" SG_ 513 VfpCamMalFunc_A_b9_2 "VtSig_VfpCamMalFunc_A";
BA_ "GenSigCmt" SG_ 513 VfpCamMalFunc_A_b9_2 "VfpCamMalFunc";
BA_ "GenSigVtEn" SG_ 513 VfpCamCtrlFlt_A_b9_3 "TRUE";
BA_ "GenSigVtName" SG_ 513 VfpCamCtrlFlt_A_b9_3 "VtSig_VfpCamCtrlFlt_A";
BA_ "GenSigCmt" SG_ 513 VfpCamCtrlFlt_A_b9_3 "VfpCamCtrlFlt";
BA_ "GenSigVtEn" SG_ 513 VfpCamVdoFlt_A_b9_5 "TRUE";
BA_ "GenSigVtName" SG_ 513 VfpCamVdoFlt_A_b9_5 "VtSig_VfpCamVdoFlt_A";
BA_ "GenSigCmt" SG_ 513 VfpCamVdoFlt_A_b9_5 "VfpCamVdoFlt";
BA_ "GenSigVtEn" SG_ 513 Partial_Blockage_fault_A_b9_7 "TRUE";
BA_ "GenSigVtName" SG_ 513 Partial_Blockage_fault_A_b9_7 "VtSig_Image_Partial_blockage_A";
BA_ "GenSigCmt" SG_ 513 Partial_Blockage_fault_A_b9_7 "Image_Partial_blockage";
BA_ "GenSigVtEn" SG_ 513 CMBB_ACC_ValFault_A_b8_2 "TRUE";
BA_ "GenSigVtName" SG_ 513 CMBB_ACC_ValFault_A_b8_2 "VtSig_CMBB_ACC_ValFault_A";
BA_ "GenSigCmt" SG_ 513 CMBB_ACC_ValFault_A_b8_2 "CMBB_ACC_ValFault";
BA_ "GenSigVtEn" SG_ 513 HostSWResetMismatchFault_A_b8_3 "TRUE";
BA_ "GenSigVtName" SG_ 513 HostSWResetMismatchFault_A_b8_3 "VtSig_HostSWResetMismatchFault_A";
BA_ "GenSigCmt" SG_ 513 HostSWResetMismatchFault_A_b8_3 "HostSWResetMismatchFault";
BA_ "GenSigCmt" SG_ 513 CAN_BDU_Msg_Invalid_A_b8_4 "CAN_BDU_Msg_Invalid_A_b8_4";
BA_ "GenSigCmt" SG_ 513 HostCSIHPeripheralFault_A_b8_5 "Reserved";
BA_ "GenSigCmt" SG_ 513 HostCANPeripheralFault_A_b8_6 "Reserved";
BA_ "GenSigCmt" SG_ 513 HostHighSpdOscStopFault_A_b8_7 "Reserved";
BA_ "GenSigVtEn" SG_ 512 grab_issue_failure_A_b7_0 "TRUE";
BA_ "GenSigVtName" SG_ 512 grab_issue_failure_A_b7_0 "VtSig_grab_issue_failure_A_b7_0";
BA_ "GenSigCmt" SG_ 512 grab_issue_failure_A_b7_0 "grab_issue_failure_A_b7_0";
BA_ "GenSigVtEn" SG_ 512 grab_acquire_failure_A_b7_1 "TRUE";
BA_ "GenSigVtName" SG_ 512 grab_acquire_failure_A_b7_1 "VtSig_grab_acquire_failure_A_b7_1";
BA_ "GenSigCmt" SG_ 512 grab_acquire_failure_A_b7_1 "grab_acquire_failure_A_b7_1";
BA_ "GenSigVtEn" SG_ 512 grab_release_failure_A_b7_2 "TRUE";
BA_ "GenSigVtName" SG_ 512 grab_release_failure_A_b7_2 "VtSig_grab_release_failure_A_b7_2";
BA_ "GenSigCmt" SG_ 512 grab_release_failure_A_b7_2 "grab_release_failure_A_b7_2";
BA_ "GenSigVtEn" SG_ 512 VFP_subsystem_comm_fault_A_b7_3 "TRUE";
BA_ "GenSigVtName" SG_ 512 VFP_subsystem_comm_fault_A_b7_3 "VtSig_subsystem_comm_fault_A_b7_3";
BA_ "GenSigCmt" SG_ 512 VFP_subsystem_comm_fault_A_b7_3 "subsystem_comm_fault_A_b7_3";
BA_ "GenSigVtEn" SG_ 512 parameters_invalid_A_b7_4 "TRUE";
BA_ "GenSigVtName" SG_ 512 parameters_invalid_A_b7_4 "VtSig_parameters_invalid_A_b7_4";
BA_ "GenSigCmt" SG_ 512 parameters_invalid_A_b7_4 "parameters_invalid_A_b7_4";
BA_ "GenSigVtEn" SG_ 512 ThermistorOutOfRange_A_b7_5 "TRUE";
BA_ "GenSigVtName" SG_ 512 ThermistorOutOfRange_A_b7_5 "VtSig_ThermistorOutOfRange_A_b7_5";
BA_ "GenSigCmt" SG_ 512 ThermistorOutOfRange_A_b7_5 "ThermistorOutOfRange_A_b7_5";
BA_ "GenSigVtEn" SG_ 512 BatteryHighFault_Act_A_b7_6 "TRUE";
BA_ "GenSigVtName" SG_ 512 BatteryHighFault_Act_A_b7_6 "VtSig_BatteryHighFault_A_b7_6";
BA_ "GenSigCmt" SG_ 512 BatteryHighFault_Act_A_b7_6 "Battery High Fault_A_b7_6";
BA_ "GenSigVtEn" SG_ 512 BatteryLowFault_Act_A_b7_7 "TRUE";
BA_ "GenSigVtName" SG_ 512 BatteryLowFault_Act_A_b7_7 "VtSig_BatteryLowFault_A_b7_7";
BA_ "GenSigCmt" SG_ 512 BatteryLowFault_Act_A_b7_7 "Battery Low Fault_A_b7_7";
BA_ "GenSigVtEn" SG_ 512 VFPCoreDumpFault_A_b6_0 "TRUE";
BA_ "GenSigVtName" SG_ 512 VFPCoreDumpFault_A_b6_0 "VtSig_VFPCoreDumpFault_A_b6_0";
BA_ "GenSigCmt" SG_ 512 VFPCoreDumpFault_A_b6_0 "VFPCoreDumpFault_A_b6_0";
BA_ "GenSigCmt" SG_ 512 DDROverTemp_A_b6_1 "Reserved";
BA_ "GenSigVtEn" SG_ 512 BusOffPCAN_A_b6_3 "TRUE";
BA_ "GenSigVtName" SG_ 512 BusOffPCAN_A_b6_3 "VtSig_BusOffPCAN_A_b6_3";
BA_ "GenSigCmt" SG_ 512 BusOffPCAN_A_b6_3 "Bus off PCAN";
BA_ "GenSigVtEn" SG_ 512 init_vdi_failure_A_b6_5 "TRUE";
BA_ "GenSigVtName" SG_ 512 init_vdi_failure_A_b6_5 "VtSig_init_vdi_failure_A_b6_5";
BA_ "GenSigCmt" SG_ 512 init_vdi_failure_A_b6_5 "init_vdi_failure";
BA_ "GenSigVtEn" SG_ 512 init_I2C_failure_A_b6_6 "TRUE";
BA_ "GenSigVtName" SG_ 512 init_I2C_failure_A_b6_6 "VtSig_init_I2C_failure_A_b6_6";
BA_ "GenSigCmt" SG_ 512 init_I2C_failure_A_b6_6 "init_I2C_failure";
BA_ "GenSigVtEn" SG_ 512 grab_no_free_header_failure_A_b6 "TRUE";
BA_ "GenSigVtName" SG_ 512 grab_no_free_header_failure_A_b6 "VtSig_grab_no_free_header_fail_A_b6_7";
BA_ "GenSigCmt" SG_ 512 grab_no_free_header_failure_A_b6 "grab_no_free_header_failure";
BA_ "SystemSignalLongSymbol" SG_ 512 grab_no_free_header_failure_A_b6 "grab_no_free_header_failure_A_b6_7";
BA_ "GenSigVtEn" SG_ 512 HostSpiCRC_A_b5_0 "TRUE";
BA_ "GenSigVtName" SG_ 512 HostSpiCRC_A_b5_0 "VtSig_HostSpiCRC_A_b5_0";
BA_ "GenSigCmt" SG_ 512 HostSpiCRC_A_b5_0 "HostSpiCRC_A_b5_0";
BA_ "GenSigVtEn" SG_ 512 VFPSpiFrameFormatError_A_b5_1 "TRUE";
BA_ "GenSigVtName" SG_ 512 VFPSpiFrameFormatError_A_b5_1 "VtSig_VFPSpiFrameFormatError_A_b5_1";
BA_ "GenSigCmt" SG_ 512 VFPSpiFrameFormatError_A_b5_1 "VFPSpiFrameFormatError_A_b5_1";
BA_ "GenSigVtEn" SG_ 512 VFPSpiMsgFormatError_A_b5_2 "TRUE";
BA_ "GenSigVtName" SG_ 512 VFPSpiMsgFormatError_A_b5_2 "VtSig_VFPSpiMsgFormalError_A_b5_2";
BA_ "GenSigCmt" SG_ 512 VFPSpiMsgFormatError_A_b5_2 "VFPSpiMsgFormatError_A_b5_2";
BA_ "GenSigVtEn" SG_ 512 VFPSpiMsgTimeout_A_b5_3 "TRUE";
BA_ "GenSigVtName" SG_ 512 VFPSpiMsgTimeout_A_b5_3 "VtSig_VFPSpiMsgTimeout_A_b5_3";
BA_ "GenSigCmt" SG_ 512 VFPSpiMsgTimeout_A_b5_3 "VFPSpiMsgTimeout_A_b5_3";
BA_ "GenSigVtEn" SG_ 512 VFPModeFault_A_b5_4 "TRUE";
BA_ "GenSigVtName" SG_ 512 VFPModeFault_A_b5_4 "VtSig_VFPModeFault_A_b5_4";
BA_ "GenSigCmt" SG_ 512 VFPModeFault_A_b5_4 "VFPModeFault_A_b5_4";
BA_ "GenSigVtEn" SG_ 512 VFPSpiCRC_A_b5_5 "TRUE";
BA_ "GenSigVtName" SG_ 512 VFPSpiCRC_A_b5_5 "VtSig_VFPSpiCRC_A_b5_5";
BA_ "GenSigCmt" SG_ 512 VFPSpiCRC_A_b5_5 "VFPSpiCRC_A_b5_5";
BA_ "GenSigVtEn" SG_ 512 SpiIpcCommReset_A_b5_6 "TRUE";
BA_ "GenSigVtName" SG_ 512 SpiIpcCommReset_A_b5_6 "VtSig_SpiIpcCommReset_A_b5_6";
BA_ "GenSigCmt" SG_ 512 SpiIpcCommReset_A_b5_6 "SpiIpcCommReset_A_b5_6";
BA_ "GenSigVtEn" SG_ 512 VFPInitTimeout_A_b5_7 "TRUE";
BA_ "GenSigVtName" SG_ 512 VFPInitTimeout_A_b5_7 "VtSig_VFPInitTimeout_A_b5_7";
BA_ "GenSigCmt" SG_ 512 VFPInitTimeout_A_b5_7 "VFPInitTimeout_A_b5_7";
BA_ "GenSigVtEn" SG_ 512 v2_8_ImagerInterfaceFault_A_b4_0 "TRUE";
BA_ "GenSigVtName" SG_ 512 v2_8_ImagerInterfaceFault_A_b4_0 "VtSig_v2.8_ImagerInterfaceFault_A_b4_0";
BA_ "GenSigCmt" SG_ 512 v2_8_ImagerInterfaceFault_A_b4_0 "2.8V_ImagerInterfaceFault_A_b4_0";
BA_ "GenSigVtEn" SG_ 512 v1_8_SupplyOutOfRangeFault_A_b4_ "TRUE";
BA_ "GenSigVtName" SG_ 512 v1_8_SupplyOutOfRangeFault_A_b4_ "VtSig_v1_8_SupplyOutOfRangeF_A_b4_1";
BA_ "GenSigCmt" SG_ 512 v1_8_SupplyOutOfRangeFault_A_b4_ "1.8 Supply out of range Fault";
BA_ "SystemSignalLongSymbol" SG_ 512 v1_8_SupplyOutOfRangeFault_A_b4_ "v1_8_SupplyOutOfRangeFault_A_b4_1";
BA_ "GenSigVtEn" SG_ 512 v1_2_SupplyOutOfRangeFault_A_b4_ "TRUE";
BA_ "GenSigVtName" SG_ 512 v1_2_SupplyOutOfRangeFault_A_b4_ "VtSig_v1_2_SupplyOutOfRangeF_A_b4_2";
BA_ "GenSigCmt" SG_ 512 v1_2_SupplyOutOfRangeFault_A_b4_ "1.2 Supply out of range Fault";
BA_ "SystemSignalLongSymbol" SG_ 512 v1_2_SupplyOutOfRangeFault_A_b4_ "v1_2_SupplyOutOfRangeFault_A_b4_2";
BA_ "GenSigVtEn" SG_ 512 HostSpiFrameFormatError_A_b4_3 "TRUE";
BA_ "GenSigVtName" SG_ 512 HostSpiFrameFormatError_A_b4_3 "VtSig_HostSpiFrameFormatError_A_b4_3";
BA_ "GenSigCmt" SG_ 512 HostSpiFrameFormatError_A_b4_3 "HostSpiFrameFormatError_A_b4_3";
BA_ "GenSigVtEn" SG_ 512 HostSpiMsgFormatError_A_b4_4 "TRUE";
BA_ "GenSigVtName" SG_ 512 HostSpiMsgFormatError_A_b4_4 "VtSig_HostSpiMsgFomatError_A_b4_4";
BA_ "GenSigCmt" SG_ 512 HostSpiMsgFormatError_A_b4_4 "HostSpiMsgFormatError_A_b4_4";
BA_ "GenSigVtEn" SG_ 512 HostSpiMsgTimeout_A_b4_5 "TRUE";
BA_ "GenSigVtName" SG_ 512 HostSpiMsgTimeout_A_b4_5 "VtSig_HostSpiMsgTimeout_A_b4_5";
BA_ "GenSigCmt" SG_ 512 HostSpiMsgTimeout_A_b4_5 "HostSpiMsgTimeout_A_b4_5";
BA_ "GenSigVtEn" SG_ 512 SPIVersionMismatch_A_b4_6 "TRUE";
BA_ "GenSigVtName" SG_ 512 SPIVersionMismatch_A_b4_6 "VtSig_SPIVersionMismatch_A_b4_6";
BA_ "GenSigCmt" SG_ 512 SPIVersionMismatch_A_b4_6 "Control Module Software #3 not programmed";
BA_ "GenSigVtEn" SG_ 512 HostSpiTxError_A_b4_7 "TRUE";
BA_ "GenSigVtName" SG_ 512 HostSpiTxError_A_b4_7 "VtSig_HostSpiTxError_A_b4_7";
BA_ "GenSigCmt" SG_ 512 HostSpiTxError_A_b4_7 "HostSpiTxError";
BA_ "GenSigCmt" SG_ 512 VFPBootOverTemp_A_b3_0 "Reserved";
BA_ "GenSigVtEn" SG_ 512 HostRAMECC_A_b3_1 "TRUE";
BA_ "GenSigVtName" SG_ 512 HostRAMECC_A_b3_1 "VtSig_HostRAMECC_A_b3_1";
BA_ "GenSigCmt" SG_ 512 HostRAMECC_A_b3_1 "Host RAM ECC [continuous]";
BA_ "GenSigVtEn" SG_ 512 HostInstructionSetCheckFault_A_b "TRUE";
BA_ "GenSigVtName" SG_ 512 HostInstructionSetCheckFault_A_b "VtSig_HostInstructionSetCheckF_A_b3_2";
BA_ "GenSigCmt" SG_ 512 HostInstructionSetCheckFault_A_b "Host Instruction Set Check Fault";
BA_ "SystemSignalLongSymbol" SG_ 512 HostInstructionSetCheckFault_A_b "HostInstructionSetCheckFault_A_b3_2";
BA_ "GenSigVtEn" SG_ 512 VfpBistMemRFlt_A_b3_3 "TRUE";
BA_ "GenSigVtName" SG_ 512 VfpBistMemRFlt_A_b3_3 "VtSig_VfpBistMemRFlt_A_b3_3";
BA_ "GenSigCmt" SG_ 512 VfpBistMemRFlt_A_b3_3 "VfpBistMemRFlt_b3_3   [vfp+flr]";
BA_ "GenSigVtEn" SG_ 512 HostOscillatorStopped_A_b3_4 "TRUE";
BA_ "GenSigVtName" SG_ 512 HostOscillatorStopped_A_b3_4 "VtSig_HostOscillatorStopped_A_b3_4";
BA_ "GenSigCmt" SG_ 512 HostOscillatorStopped_A_b3_4 "HostOscillatorStopped_A_b3_4";
BA_ "GenSigVtEn" SG_ 512 HostStackOverflowFault_A_b3_5 "TRUE";
BA_ "GenSigVtName" SG_ 512 HostStackOverflowFault_A_b3_5 "VtSig_HostStackoverflowFault_A_b3_5";
BA_ "GenSigCmt" SG_ 512 HostStackOverflowFault_A_b3_5 "HostStackOverflowFault_A_b3_5";
BA_ "GenSigVtEn" SG_ 512 HostCOPFault_A_b3_6 "TRUE";
BA_ "GenSigVtName" SG_ 512 HostCOPFault_A_b3_6 "VtSig_HostCOPFault_A_b3_6";
BA_ "GenSigCmt" SG_ 512 HostCOPFault_A_b3_6 "Host COP Fault";
BA_ "GenSigVtEn" SG_ 512 v5_0_SupplyOutOfRangeFault_A_b3_ "TRUE";
BA_ "GenSigVtName" SG_ 512 v5_0_SupplyOutOfRangeFault_A_b3_ "VtSig_v5_0_SupplyOutOfRangeFault_A_b3_7";
BA_ "GenSigCmt" SG_ 512 v5_0_SupplyOutOfRangeFault_A_b3_ "5.0 Supply out of range Fault";
BA_ "SystemSignalLongSymbol" SG_ 512 v5_0_SupplyOutOfRangeFault_A_b3_ "v5_0_SupplyOutOfRangeFault_A_b3_7";
BA_ "GenSigVtEn" SG_ 512 VfpDDRFlt_A_b2_0 "TRUE";
BA_ "GenSigVtName" SG_ 512 VfpDDRFlt_A_b2_0 "VtSig_VfpDDRFlt_A_b2_0";
BA_ "GenSigCmt" SG_ 512 VfpDDRFlt_A_b2_0 "VfpDDRFlt_H_b2_0   [vfp+flr]";
BA_ "GenSigVtEn" SG_ 512 DdrRamCrc_A_b2_1 "TRUE";
BA_ "GenSigVtName" SG_ 512 DdrRamCrc_A_b2_1 "VtSig_DdrRamCrc_A_b2_1";
BA_ "GenSigCmt" SG_ 512 DdrRamCrc_A_b2_1 "DDR RAM CRC";
BA_ "GenSigVtEn" SG_ 512 VfpBootFlt_A_b2_2 "TRUE";
BA_ "GenSigVtName" SG_ 512 VfpBootFlt_A_b2_2 "VtSig_VfpBootFlt_A_b2_2";
BA_ "GenSigCmt" SG_ 512 VfpBootFlt_A_b2_2 "VfpBootFlt   [vfp+flr]";
BA_ "GenSigVtEn" SG_ 512 VfpCoreFlt_A_b2_3 "TRUE";
BA_ "GenSigVtName" SG_ 512 VfpCoreFlt_A_b2_3 "VtSig_VfpCoreFlt_A_b2_3";
BA_ "GenSigCmt" SG_ 512 VfpCoreFlt_A_b2_3 "VfpCoreFlt   [vfp+flr]";
BA_ "GenSigVtEn" SG_ 512 HostCodeFlashECC_A_b2_4 "TRUE";
BA_ "GenSigVtName" SG_ 512 HostCodeFlashECC_A_b2_4 "VtSig_HostCodeFlashECC_A_b2_4";
BA_ "GenSigCmt" SG_ 512 HostCodeFlashECC_A_b2_4 "Host Code Flash ECC  [continuous]";
BA_ "GenSigVtEn" SG_ 512 HostDataFlashECC_A_b2_5 "TRUE";
BA_ "GenSigVtName" SG_ 512 HostDataFlashECC_A_b2_5 "VtSig_HostDataFlashECC_A_b2_5";
BA_ "GenSigCmt" SG_ 512 HostDataFlashECC_A_b2_5 "Host Data Flash ECC  [continuous]";
BA_ "GenSigVtEn" SG_ 512 SerialFlashPowerUpFail_A_b2_6 "TRUE";
BA_ "GenSigVtName" SG_ 512 SerialFlashPowerUpFail_A_b2_6 "VtSig_SerialFlashPowerUpFail_A_b2_6";
BA_ "GenSigCmt" SG_ 512 SerialFlashPowerUpFail_A_b2_6 "SerialFlashPowerUpFail_A_b2_6";
BA_ "GenSigVtEn" SG_ 512 HostRamFault_A_b2_7 "TRUE";
BA_ "GenSigVtName" SG_ 512 HostRamFault_A_b2_7 "VtSig_HostRamFault_A_b2_7";
BA_ "GenSigCmt" SG_ 512 HostRamFault_A_b2_7 "HostRamFault [start up]";
BA_ "GenSigVtEn" SG_ 512 KAMChecksumFault_A_b1_0 "TRUE";
BA_ "GenSigVtName" SG_ 512 KAMChecksumFault_A_b1_0 "VtSig_KAMChecksumFault_A_b1_0";
BA_ "GenSigCmt" SG_ 512 KAMChecksumFault_A_b1_0 "KAMChecksumFault_A_b1_0";
BA_ "GenSigVtEn" SG_ 512 HostApplicationCRC_A_b1_1 "TRUE";
BA_ "GenSigVtName" SG_ 512 HostApplicationCRC_A_b1_1 "VtSig_HostApplicationCRC_A_b1_1";
BA_ "GenSigCmt" SG_ 512 HostApplicationCRC_A_b1_1 "HostApplicationCRC_A_b1_1";
BA_ "GenSigVtEn" SG_ 512 HostCalibrationCRC_A_b1_2 "TRUE";
BA_ "GenSigVtName" SG_ 512 HostCalibrationCRC_A_b1_2 "VtSig_HostCalibrationCRC_A_b1_2";
BA_ "GenSigCmt" SG_ 512 HostCalibrationCRC_A_b1_2 "HostCalibrationCRC_A_b1_2";
BA_ "GenSigVtEn" SG_ 512 VFPApplicationChecksum_A_b1_3 "TRUE";
BA_ "GenSigVtName" SG_ 512 VFPApplicationChecksum_A_b1_3 "VtSig_VFPApplicationChecksum_A_b1_3";
BA_ "GenSigCmt" SG_ 512 VFPApplicationChecksum_A_b1_3 "VFPApplicationChecksum_A_b1_3";
BA_ "GenSigVtEn" SG_ 512 VFPCalibrationChecksum_A_b1_4 "TRUE";
BA_ "GenSigVtName" SG_ 512 VFPCalibrationChecksum_A_b1_4 "VtSig_HostCalCompleteAndComp_A_b1_4";
BA_ "GenSigCmt" SG_ 512 VFPCalibrationChecksum_A_b1_4 "VFPCalibrationChecksum_A_b1_4";
BA_ "GenSigCmt" SG_ 512 HostCalComplAndCompat_A_b1_5 "VFP Calibration Checksum";
BA_ "GenSigVtEn" SG_ 512 HostCalComplAndCompat_A_b1_5 "TRUE";
BA_ "GenSigVtName" SG_ 512 HostCalComplAndCompat_A_b1_5 "VtSig_HostCalComplAndCompat_A_b1_5";
BA_ "GenSigVtEn" SG_ 512 VFPAppComplAndCompat_A_b1_6 "TRUE";
BA_ "GenSigVtName" SG_ 512 VFPAppComplAndCompat_A_b1_6 "VtSig_VFPAppCompleteAndComp_A_b1_6";
BA_ "GenSigCmt" SG_ 512 VFPAppComplAndCompat_A_b1_6 "VFPAppComplAndCompat_A_b1_6";
BA_ "GenSigVtEn" SG_ 512 InvalidAHBCSensParams_A_b1_7 "TRUE";
BA_ "GenSigVtName" SG_ 512 InvalidAHBCSensParams_A_b1_7 "VtSig_InvalidAHBCSensParams_A_b1_7";
BA_ "GenSigCmt" SG_ 512 InvalidAHBCSensParams_A_b1_7 "InvalidAHBCSensParams_A_b1_7";
BA_ "GenSigVtEn" SG_ 512 VFPCalComplCompatSWP3_A_b0_1 "TRUE";
BA_ "GenSigVtName" SG_ 512 VFPCalComplCompatSWP3_A_b0_1 "VtSig_VFPCalComplCompatSWP3_A_b0_1";
BA_ "GenSigCmt" SG_ 512 VFPCalComplCompatSWP3_A_b0_1 "VFPCalComplCompatSWP3_A_b0_1";
BA_ "GenSigVtEn" SG_ 512 VFPCalComplCompatSWP5_A_b0_2 "TRUE";
BA_ "GenSigVtName" SG_ 512 VFPCalComplCompatSWP5_A_b0_2 "VtSig_VFPCalComplCompatSWP5_A_b0_2";
BA_ "GenSigCmt" SG_ 512 VFPCalComplCompatSWP5_A_b0_2 "VFPCalComplCompatSWP5_A_b0_2";
BA_ "GenSigVtEn" SG_ 512 SystemOverTemperature_A_b0_3 "TRUE";
BA_ "GenSigVtName" SG_ 512 SystemOverTemperature_A_b0_3 "VtSig_SystemOverTemperature_A_b0_3";
BA_ "GenSigCmt" SG_ 512 SystemOverTemperature_A_b0_3 "SystemOverTemperature_A_b0_3";
BA_ "GenSigVtEn" SG_ 512 OnBdThermOvrTemp_A_b0_4 "TRUE";
BA_ "GenSigCmt" SG_ 512 OnBdThermOvrTemp_A_b0_4 "OnBdThermOvrTemp_A_b0_4";
BA_ "GenSigVtName" SG_ 512 OnBdThermOvrTemp_A_b0_4 "VtSig_OnBdThermOvrTemp_A_b0_4";
BA_ "GenSigVtEn" SG_ 512 VFPMIPSOverTemp_A_b0_5 "TRUE";
BA_ "GenSigCmt" SG_ 512 VFPMIPSOverTemp_A_b0_5 "VFPMIPSOverTemp_A_b0_5";
BA_ "GenSigVtName" SG_ 512 VFPMIPSOverTemp_A_b0_5 "VtSig_VFPMIPSOverTemp_A_b0_5";
BA_ "GenSigVtEn" SG_ 512 VFPVMPOverTemp_A_b0_6 "TRUE";
BA_ "GenSigCmt" SG_ 512 VFPVMPOverTemp_A_b0_6 "VFPVMPOverTemp_A_b0_6";
BA_ "GenSigVtName" SG_ 512 VFPVMPOverTemp_A_b0_6 "VtSig_VFPVMPOverTemp_A_b0_6";
BA_ "GenSigVtEn" SG_ 512 VFPImagerOverTemp_A_b0_7 "TRUE";
BA_ "GenSigCmt" SG_ 512 VFPImagerOverTemp_A_b0_7 "VFPImagerOverTemp_A_b0_7";
BA_ "GenSigVtName" SG_ 512 VFPImagerOverTemp_A_b0_7 "VtSig_VFPImageroverTemp_A_b0_7";
BA_ "GenSigCmt" SG_ 1795 Cnt_Mesp_Successful_Requests "Counter of MESP successful requests";
BA_ "GenSigSendType" SG_ 1795 Cnt_Mesp_Successful_Requests 1;
BA_ "GenSigCmt" SG_ 1795 Cnt_Mesp_Response_Tx_Error "Counter of MESP response transmitted error";
BA_ "GenSigSendType" SG_ 1795 Cnt_Mesp_Response_Tx_Error 1;
BA_ "GenSigCmt" SG_ 1795 Cnt_Invalid_Service "Counter of invalid services";
BA_ "GenSigSendType" SG_ 1795 Cnt_Invalid_Service 1;
BA_ "GenSigCmt" SG_ 1795 Cnt_Invalid_Params "Counter of invalid parameters";
BA_ "GenSigSendType" SG_ 1795 Cnt_Invalid_Params 1;
BA_ "GenSigCmt" SG_ 1795 Cnt_Invalid_MsgTag "Counter of invalid messages tag";
BA_ "GenSigSendType" SG_ 1795 Cnt_Invalid_MsgTag 1;
BA_ "GenSigCmt" SG_ 1795 Cnt_Invalid_Mesp_Requests "Counter of invalid MESP requests";
BA_ "GenSigSendType" SG_ 1795 Cnt_Invalid_Mesp_Requests 1;
BA_ "GenSigCmt" SG_ 1795 Cnt_Invalid_Function "Counter of invalid functions";
BA_ "GenSigSendType" SG_ 1795 Cnt_Invalid_Function 1;
BA_ "GenSigCmt" SG_ 1795 Cnt_Incorrect_Msg_Length "Counter of incorrect message length";
BA_ "GenSigSendType" SG_ 1795 Cnt_Incorrect_Msg_Length 1;
BA_ "GenSigVtEn" SG_ 1794 Service "TRUE";
BA_ "GenSigVtName" SG_ 1794 Service "VtSig_Service";
BA_ "GenSigCmt" SG_ 1794 Service "Service";
BA_ "GenSigSendType" SG_ 1794 Service 1;
BA_ "GenSigCmt" SG_ 1794 mesp_req_ret_status "MESP request last retained status";
BA_ "GenSigSendType" SG_ 1794 mesp_req_ret_status 1;
BA_ "GenSigCmt" SG_ 1794 mainstate_or_ct_type "Main state or CT type";
BA_ "GenSigSendType" SG_ 1794 mainstate_or_ct_type 1;
BA_ "GenSigCmt" SG_ 1794 ct_version "CT version";
BA_ "GenSigSendType" SG_ 1794 ct_version 1;
BA_ "GenSigCmt" SG_ 1794 Counter "MESP response counter";
BA_ "GenSigSendType" SG_ 1794 Counter 1;
BA_ "GenSigCmt" SG_ 1792 VFP_SPI_fifoNonEmpty "Updated if message length of a received message is greater than the maximum receive buffer length";
BA_ "GenSigCmt" SG_ 1792 VFP_SPI_RX_Counter "A counter that increments every time the VFP receives a SPI message";
BA_ "GenSigCmt" SG_ 1792 VFP_SPI_sequenceErrorCounter "The number of SPI frames that have been received that have a checksum error in the header";
BA_ "GenSigCmt" SG_ 1792 VFP_SPI_formatErrorCounter "The number of SPI frames that have been received that have a a valid header checksum but have a frame header format error";
BA_ "GenSigCmt" SG_ 1792 VFP_SPI_dataCRCErrorCounter "The number of SPI frames that have been received that have a CRC error in the DCS field";
BA_ "GenSigCmt" SG_ 1792 VFP_SPI_busyFrames "Number of frames currently in transit";
BA_ "GenSigCmt" SG_ 1792 VFP_SPI_sendFailedErrorCounter "Updated if the SPI driver failed to send an application message";
BA_ "GenSigVtEn" SG_ 1536 GPIO_12_16 "TRUE";
BA_ "GenSigVtName" SG_ 1536 GPIO_12_16 "VtSig_GPIO_12_16";
BA_ "GenSigCmt" SG_ 1536 GPIO_12_16 "GPIO 12-16 (GPIO 12 is the LSB)";
BA_ "GenSigSendType" SG_ 1536 GPIO_12_16 1;
BA_ "GenSigCmt" SG_ 1536 CAN_VFP_PROGRAMMING_STATE "Programming state of flash memory";
BA_ "GenSigSendType" SG_ 1536 CAN_VFP_PROGRAMMING_STATE 1;
BA_ "GenSigCmt" SG_ 1536 CAN_VFP_BOOT_MINOR_REV "Boot manager minor version";
BA_ "GenSigSendType" SG_ 1536 CAN_VFP_BOOT_MINOR_REV 1;
BA_ "GenSigCmt" SG_ 1536 CAN_VFP_BOOT_MAJOR_REV "Boot manager major version";
BA_ "GenSigSendType" SG_ 1536 CAN_VFP_BOOT_MAJOR_REV 1;
BA_ "GenSigCmt" SG_ 1536 CAN_VFP_BOOT_LOOP_CTR "Message counter";
BA_ "GenSigSendType" SG_ 1536 CAN_VFP_BOOT_LOOP_CTR 1;
BA_ "GenSigCmt" SG_ 1536 CAN_VFP_BOOT_FIELD_VER "Boot manager patch version";
BA_ "GenSigSendType" SG_ 1536 CAN_VFP_BOOT_FIELD_VER 1;
BA_ "GenSigCmt" SG_ 538 CAN_IPC_TIMESTAMP_VIS "The timestamp when the VFP transmitted the IPC msg in VFP clock time";
BA_ "GenSigSendType" SG_ 538 CAN_IPC_TIMESTAMP_VIS 1;
BA_ "GenSigCmt" SG_ 538 CAN_IPC_REF_INDEX_VIS "The second reference index for the data associated with the IPC msg";
BA_ "GenSigSendType" SG_ 538 CAN_IPC_REF_INDEX_VIS 1;
BA_ "GenSigCmt" SG_ 538 CAN_IPC_REF_INDEX_2_VIS "A reference index associated with the transmitted data";
BA_ "GenSigSendType" SG_ 538 CAN_IPC_REF_INDEX_2_VIS 1;
BA_ "GenSigCmt" SG_ 531 CAN_IPC_TIMESTAMP_FUS "The timestamp when the VFP transmitted the IPC msg in VFP clock time";
BA_ "GenSigSendType" SG_ 531 CAN_IPC_TIMESTAMP_FUS 1;
BA_ "GenSigCmt" SG_ 531 CAN_IPC_REF_INDEX_FUS "The second reference index for the data associated with the IPC msg";
BA_ "GenSigSendType" SG_ 531 CAN_IPC_REF_INDEX_FUS 1;
BA_ "GenSigCmt" SG_ 531 CAN_IPC_REF_INDEX_2_FUS "A reference index associated with the transmitted data";
BA_ "GenSigSendType" SG_ 531 CAN_IPC_REF_INDEX_2_FUS 1;
BA_ "GenSigCmt" SG_ 536 CAN_IPC_TIMESTAMP_TSEL "The timestamp when the VFP transmitted the IPC msg in VFP clock time";
BA_ "GenSigSendType" SG_ 536 CAN_IPC_TIMESTAMP_TSEL 1;
BA_ "GenSigCmt" SG_ 536 CAN_IPC_REF_INDEX_TSEL "The second reference index for the data associated with the IPC msg";
BA_ "GenSigSendType" SG_ 536 CAN_IPC_REF_INDEX_TSEL 1;
BA_ "GenSigCmt" SG_ 536 CAN_IPC_REF_INDEX_2_TSEL "A reference index associated with the transmitted data";
BA_ "GenSigSendType" SG_ 536 CAN_IPC_REF_INDEX_2_TSEL 1;
BA_ "GenSigCmt" SG_ 533 CAN_IPC_TIMESTAMP_OBJ "The timestamp when the VFP transmitted the IPC msg in VFP clock time";
BA_ "GenSigSendType" SG_ 533 CAN_IPC_TIMESTAMP_OBJ 1;
BA_ "GenSigCmt" SG_ 533 CAN_IPC_REF_INDEX_OBJ "The second reference index for the data associated with the IPC msg";
BA_ "GenSigSendType" SG_ 533 CAN_IPC_REF_INDEX_OBJ 1;
BA_ "GenSigCmt" SG_ 535 CAN_IPC_TIMESTAMP_TRAFF "The timestamp when the VFP transmitted the IPC msg in VFP clock time";
BA_ "GenSigSendType" SG_ 535 CAN_IPC_TIMESTAMP_TRAFF 1;
BA_ "GenSigCmt" SG_ 535 CAN_IPC_REF_INDEX_TRAFF "The second reference index for the data associated with the IPC msg";
BA_ "GenSigSendType" SG_ 535 CAN_IPC_REF_INDEX_TRAFF 1;
BA_ "GenSigCmt" SG_ 535 CAN_IPC_REF_INDEX_2_TRAFF "A reference index associated with the transmitted data";
BA_ "GenSigSendType" SG_ 535 CAN_IPC_REF_INDEX_2_TRAFF 1;
BA_ "GenSigCmt" SG_ 532 CAN_IPC_TIMESTAMP_LIGHT "The timestamp when the VFP transmitted the IPC msg in VFP clock time";
BA_ "GenSigSendType" SG_ 532 CAN_IPC_TIMESTAMP_LIGHT 1;
BA_ "GenSigCmt" SG_ 532 CAN_IPC_REF_INDEX_LIGHT "The second reference index for the data associated with the IPC msg";
BA_ "GenSigSendType" SG_ 532 CAN_IPC_REF_INDEX_LIGHT 1;
BA_ "GenSigCmt" SG_ 534 CAN_IPC_TIMESTAMP_ROAD "The timestamp when the VFP transmitted the IPC msg in VFP clock time";
BA_ "GenSigSendType" SG_ 534 CAN_IPC_TIMESTAMP_ROAD 1;
BA_ "GenSigCmt" SG_ 534 CAN_IPC_REF_INDEX_ROAD "The second reference index for the data associated with the IPC msg";
BA_ "GenSigSendType" SG_ 534 CAN_IPC_REF_INDEX_ROAD 1;
BA_ "GenSigCmt" SG_ 1793 SPI_RX_OVERRUN_COUNTER "Counter that increment for each received overrun that occurs in the physical SPI driver";
BA_ "GenSigCmt" SG_ 1793 SPI_DATA_CONSISTENCY_COUNTER "The purpose of the data consistency check is to ensure that the data physically sent as output signal is identical to the original data that was copied to the shift register";
BA_ "GenSigCmt" SG_ 1793 TP_DLL_RX_ERROR_COUNTER "Counter that increment for each error that occurs in the IPC layer";
BA_ "GenSigCmt" SG_ 1793 IPC_MESSAGE_GOOD_TX_COUNTER "Counter of the correctly transmitted messages from the Host";
BA_ "GenSigCmt" SG_ 1793 IPC_ERROR_COUNTER "Counter that increment for each error that occurs in the TP/DLL layer";
BA_ "GenSigCmt" SG_ 1793 IPC_MESSAGE_GOOD_RX_COUNTER "Counter of the correctly received messages from the VFP";
BA_ "GenSigCmt" SG_ 523 CAN_VFP_SW_PATCH_REV "The Minor revision number for the VFP software in BCD. Development/ internal releases";
BA_ "GenSigCmt" SG_ 523 CAN_VFP_SW_MINOR_REV "The minor version number for the VFP software in BCD";
BA_ "GenSigCmt" SG_ 523 CAN_VFP_SW_MAJOR_REV "The major version number for the VFP software in BCD";
BA_ "GenSigVtEn" SG_ 524 ddrTemperature "TRUE";
BA_ "GenSigVtName" SG_ 524 ddrTemperature "VtSig_ddrTemperature";
BA_ "GenSigCmt" SG_ 524 ddrTemperature "DDR Temperature status";
BA_ "GenSigVtEn" SG_ 524 vmpTemperature "TRUE";
BA_ "GenSigVtName" SG_ 524 vmpTemperature "VtSig_vmpTemperature";
BA_ "GenSigCmt" SG_ 524 vmpTemperature "VMP temperature";
BA_ "GenSigVtEn" SG_ 524 mipsTemperature "TRUE";
BA_ "GenSigVtName" SG_ 524 mipsTemperature "VtSig_mipsTemperature";
BA_ "GenSigCmt" SG_ 524 mipsTemperature "MIPS temperature";
BA_ "GenSigVtEn" SG_ 524 imagerTemperature "TRUE";
BA_ "GenSigVtName" SG_ 524 imagerTemperature "VtSig_imagerTemperature";
BA_ "GenSigCmt" SG_ 524 imagerTemperature "Imager temperature";
BA_ "GenSigCmt" SG_ 518 Reg5VOutU "5 volt supply";
BA_ "GenSigCmt" SG_ 518 Reg1V8OutU "1.8 volt supply";
BA_ "GenSigCmt" SG_ 518 Reg1V2OutU "1.2 volt supply";
BA_ "GenSigCmt" SG_ 518 FrntCamU "2.8 volt supply for the camera";
BA_ "GenSigCmt" SG_ 518 VBattU "Raw supply voltage";
BA_ "GenSigCmt" SG_ 518 PwrRfU "Filtered supply voltage";
BA_ "GenSigCmt" SG_ 518 EcuOnBdT "ECU on board temperature";
BA_ "GenSigCmt" SG_ 542 CAN_VISION_TRIGGER_TIMESTAMP "The index of the camera image captured by the VFP";
BA_ "GenSigCmt" SG_ 542 CAN_CAMERA_IMAGE_INDEX_VFP "The timestamp when the Vision subsystem provided new information in VFP clock time";
BA_ "GenSigVtEn" SG_ 544 Vision_VFP_Mode "TRUE";
BA_ "GenSigVtName" SG_ 544 Vision_VFP_Mode "VtSig_vision_sensor_state";
BA_ "GenSigCmt" SG_ 544 Vision_VFP_Mode "Determines whether the vision sensor is enables or disabled";
BA_ "GenSigVtEn" SG_ 544 Internal_VFP_mode "TRUE";
BA_ "GenSigVtName" SG_ 544 Internal_VFP_mode "VtSig_sensor_app_state";
BA_ "GenSigCmt" SG_ 544 Internal_VFP_mode "The Operating Modes for the VFP";
BA_ "GenSigCmt" SG_ 540 CWMP_RELEASE_REV "The major version number for the Host software in BCD";
BA_ "GenSigCmt" SG_ 540 CWMP_PROMOTE_REV "The Promote revision number for the Host software in BCD";
BA_ "GenSigCmt" SG_ 540 CWMP_FIELD_REV "The field revision number for the Host software in BCD";
BA_ "GenSigCmt" SG_ 540 CWMP_BOOT_RELEASE_REV "The major version number for the Host software in BCD";
BA_ "GenSigCmt" SG_ 540 CWMP_BOOT_PROMOTE_REV "The Promote revision number for the Host bootloader software in BCD";
BA_ "GenSigCmt" SG_ 540 CWMP_BOOT_FIELD_REV "The field revision number for the Host bootloader software in BCD";
BA_ "GenSigCmt" SG_ 1029 CAN_CAMERA_IMAGE_TIMESTAMP_CWMP "The timestamp when the Camera Image Index was captured in CWMP clock time";
BA_ "GenSigCmt" SG_ 1029 CAN_CAMERA_IMAGE_INDEX_CWMP "The index of the camera image captured by the VFP";
BA_ "GenSigSendType" SG_ 753 xcp_cwmp_slave_cto_byte_7 1;
BA_ "GenSigSendType" SG_ 753 xcp_cwmp_slave_cto_byte_6 1;
BA_ "GenSigSendType" SG_ 753 xcp_cwmp_slave_cto_byte_5 1;
BA_ "GenSigSendType" SG_ 753 xcp_cwmp_slave_cto_byte_4 1;
BA_ "GenSigSendType" SG_ 753 xcp_cwmp_slave_cto_byte_3 1;
BA_ "GenSigSendType" SG_ 753 xcp_cwmp_slave_cto_byte_2 1;
BA_ "GenSigSendType" SG_ 753 xcp_cwmp_slave_cto_byte_1 1;
BA_ "GenSigSendType" SG_ 753 xcp_cwmp_slave_cto_byte_0 1;
BA_ "GenSigSendType" SG_ 752 xcp_cwmp_master_cto_byte_7 1;
BA_ "GenSigSendType" SG_ 752 xcp_cwmp_master_cto_byte_6 1;
BA_ "GenSigSendType" SG_ 752 xcp_cwmp_master_cto_byte_5 1;
BA_ "GenSigSendType" SG_ 752 xcp_cwmp_master_cto_byte_4 1;
BA_ "GenSigSendType" SG_ 752 xcp_cwmp_master_cto_byte_3 1;
BA_ "GenSigSendType" SG_ 752 xcp_cwmp_master_cto_byte_2 1;
BA_ "GenSigSendType" SG_ 752 xcp_cwmp_master_cto_byte_1 1;
BA_ "GenSigSendType" SG_ 752 xcp_cwmp_master_cto_byte_0 1;
BA_ "GenSigSendType" SG_ 737 xcp_vfp_slave_cto_byte_7 1;
BA_ "GenSigSendType" SG_ 737 xcp_vfp_slave_cto_byte_6 1;
BA_ "GenSigSendType" SG_ 737 xcp_vfp_slave_cto_byte_5 1;
BA_ "GenSigSendType" SG_ 737 xcp_vfp_slave_cto_byte_4 1;
BA_ "GenSigSendType" SG_ 737 xcp_vfp_slave_cto_byte_3 1;
BA_ "GenSigSendType" SG_ 737 xcp_vfp_slave_cto_byte_2 1;
BA_ "GenSigSendType" SG_ 737 xcp_vfp_slave_cto_byte_1 1;
BA_ "GenSigSendType" SG_ 737 xcp_vfp_slave_cto_byte_0 1;
BA_ "GenSigSendType" SG_ 736 xcp_vfp_master_cto_byte_7 1;
BA_ "GenSigSendType" SG_ 736 xcp_vfp_master_cto_byte_6 1;
BA_ "GenSigSendType" SG_ 736 xcp_vfp_master_cto_byte_5 1;
BA_ "GenSigSendType" SG_ 736 xcp_vfp_master_cto_byte_4 1;
BA_ "GenSigSendType" SG_ 736 xcp_vfp_master_cto_byte_3 1;
BA_ "GenSigSendType" SG_ 736 xcp_vfp_master_cto_byte_2 1;
BA_ "GenSigSendType" SG_ 736 xcp_vfp_master_cto_byte_1 1;
BA_ "GenSigSendType" SG_ 736 xcp_vfp_master_cto_byte_0 1;
BA_ "GenSigCmt" SG_ 1088 CAN_INSTCAN_VERSION_MINOR "The minor version number of the PCAN interface";
BA_ "GenSigCmt" SG_ 1088 CAN_INSTCAN_VERSION_MAJOR "The major version number of the PCAN interface";
BA_ "GenSigCmt" SG_ 1088 CAN_VEHICLE_YAW_RATE "The compensated yaw rate received on the vehicle network";
BA_ "GenSigCmt" SG_ 1088 CAN_VEHICLE_SPEED "The raw vehicle speed received on the vehicle network";
BA_ "GenSigCmt" SG_ 517 CWMP_CPU_IDLE_TIME "CPU idle time";
BA_ "GenSigCmt" SG_ 517 CAN_CWMP_CYCLE_INDEX_CYCLE "The cycle index for LROS task execution";
BA_ "GenSigCmt" SG_ 517 CAN_CAMERA_IMAGE_INDEX_USED "The index of the camera image captured by the VFP used by LROS SWC";
BA_ "GenSigVtEn" SG_ 539 CAN_VFP_RST "TRUE";
BA_ "GenSigVtName" SG_ 539 CAN_VFP_RST "VtSig_CAN_VFP_RST";
BA_ "GenSigCmt" SG_ 539 CAN_VFP_RST "Status of VFP reset line controlled by the host";
BA_ "GenSigVtEn" SG_ 539 CAN_VFP_RST_POR "TRUE";
BA_ "GenSigVtName" SG_ 539 CAN_VFP_RST_POR "VtSig_CAN_VFP_RST_POR";
BA_ "GenSigCmt" SG_ 539 CAN_VFP_RST_POR "Status of VFP reset line controlled by the host";
BA_ "GenSigVtEn" SG_ 539 CAN_VFP_IO_STS "TRUE";
BA_ "GenSigVtName" SG_ 539 CAN_VFP_IO_STS "VtSig_CAN_VFP_IO_STS";
BA_ "GenSigCmt" SG_ 539 CAN_VFP_IO_STS "Host reporting of VFP IO Status lines";
BA_ "GenSigCmt" SG_ 539 LrosTjaConfErrCnt "Number of illegal object TJA confidences detected at the LROS";
BA_ "GenSigCmt" SG_ 539 LrosCmbbConfErrCnt "Number of illegal object primary CMbB confidences detected at the LROS";
BA_ "GenSigCmt" SG_ 1028 CAN_CAMERA_IMAGE_TIMESTAMP_SYNC "The timestamp when the Camera Image Index was captured in VFP clock time";
BA_ "GenSigCmt" SG_ 1028 CAN_CAMERA_IMAGE_INDEX_SYNC "The index of the camera image captured by the VFP";
BA_ "GenSigCmt" SG_ 1024 CAN_VFP_TIMESTAMP "The timestamp of the VFP clock when it transmitted a sync pulse from the VFP";
BA_ "GenSigCmt" SG_ 1024 CAN_CWMP_TIMESTAMP "The timestamp of the CWMP clock when it received a sync pulse from the VFP";
BA_ "GenSigSendType" SG_ 1926 PCA_VAC_MessageCounter 1;
BA_ "GenSigSendType" SG_ 1926 PCA_VAC_XOLC_ETSEL 1;
BA_ "GenSigSendType" SG_ 1926 PCA_VAC_XOHP_ETSEL 1;
BA_ "GenSigSendType" SG_ 1921 PCA_SAB_Age 1;
BA_ "GenSigSendType" SG_ 1921 PCA_SAB_MOVEMENT 1;
BA_ "GenSigSendType" SG_ 1921 PCA_SAB_Width 1;
BA_ "GenSigSendType" SG_ 1921 PCA_SAB_visTrkID 1;
BA_ "GenSigSendType" SG_ 1921 PCA_SAB_FcwConfidence 1;
BA_ "GenSigSendType" SG_ 1921 PCA_SAB_CmbbPrimaryConfidence 1;
BA_ "GenSigVtEn" SG_ 1921 PCA_SAB_DetectionSensor "TRUE";
BA_ "GenSigVtName" SG_ 1921 PCA_SAB_DetectionSensor "VtSig_PCA_SAB_DetectionSensor";
BA_ "GenSigSendType" SG_ 1921 PCA_SAB_DetectionSensor 1;
BA_ "GenSigVtEn" SG_ 1921 PCA_SAB_Status "TRUE";
BA_ "GenSigVtName" SG_ 1921 PCA_SAB_Status "VtSig_PCA_SAB_DCVc_Status";
BA_ "GenSigSendType" SG_ 1921 PCA_SAB_Status 1;
BA_ "GenSigSendType" SG_ 1921 PCA_SAB_Stage_age 1;
BA_ "GenSigVtEn" SG_ 1921 PCA_SAB_Object_class "TRUE";
BA_ "GenSigVtName" SG_ 1921 PCA_SAB_Object_class "VtSig_PCA_SAB_DCVc_object_class";
BA_ "GenSigSendType" SG_ 1921 PCA_SAB_Object_class 1;
BA_ "GenSigSendType" SG_ 1921 PCA_SAB_A_lat_obj 1;
BA_ "GenSigSendType" SG_ 1922 PCA_SAC_MessageCounter 1;
BA_ "GenSigSendType" SG_ 1922 PCA_SAC_XOLC_ETSEL 1;
BA_ "GenSigSendType" SG_ 1922 PCA_SAC_XOHP_ETSEL 1;
BA_ "GenSigSendType" SG_ 1924 PCA_VAA_V_long_obj 1;
BA_ "GenSigSendType" SG_ 1924 PCA_VAA_V_lat_obj 1;
BA_ "GenSigSendType" SG_ 1924 PCA_VAA_TrackID 1;
BA_ "GenSigSendType" SG_ 1924 PCA_VAA_L_long_rel 1;
BA_ "GenSigSendType" SG_ 1924 PCA_VAA_L_lat_rel 1;
BA_ "GenSigSendType" SG_ 1924 PCA_VAA_A_long_obj 1;
BA_ "GenSigSendType" SG_ 1925 PCA_VAB_Age 1;
BA_ "GenSigSendType" SG_ 1925 PCA_VAB_MOVEMENT 1;
BA_ "GenSigSendType" SG_ 1925 PCA_VAB_Width 1;
BA_ "GenSigSendType" SG_ 1925 PCA_VAB_visTrkID 1;
BA_ "GenSigSendType" SG_ 1925 PCA_VAB_FcwConfidence 1;
BA_ "GenSigSendType" SG_ 1925 PCA_VAB_CmbbPrimaryConfidence 1;
BA_ "GenSigVtEn" SG_ 1925 PCA_VAB_DetectionSensor "TRUE";
BA_ "GenSigVtName" SG_ 1925 PCA_VAB_DetectionSensor "VtSig_PCA_VAB_DetectionSensor";
BA_ "GenSigSendType" SG_ 1925 PCA_VAB_DetectionSensor 1;
BA_ "GenSigSendType" SG_ 1925 PCA_VAB_Stage_age 1;
BA_ "GenSigVtEn" SG_ 1925 PCA_VAB_Object_class "TRUE";
BA_ "GenSigVtName" SG_ 1925 PCA_VAB_Object_class "VtSig_PCA_VAB_DCVc_object_class";
BA_ "GenSigSendType" SG_ 1925 PCA_VAB_Object_class 1;
BA_ "GenSigSendType" SG_ 1925 PCA_VAB_A_lat_obj 1;
BA_ "GenSigSendType" SG_ 1920 PCA_SAA_V_long_obj 1;
BA_ "GenSigSendType" SG_ 1920 PCA_SAA_V_lat_obj 1;
BA_ "GenSigSendType" SG_ 1920 PCA_SAA_TrackID 1;
BA_ "GenSigSendType" SG_ 1920 PCA_SAA_L_long_rel 1;
BA_ "GenSigSendType" SG_ 1920 PCA_SAA_L_lat_rel 1;
BA_ "GenSigSendType" SG_ 1920 PCA_SAA_A_long_obj 1;
BA_ "GenSigSendType" SG_ 260 ETSEL_common_2_MessageCounter 1;
BA_ "GenSigSendType" SG_ 260 V_Host_Long_front 1;
BA_ "GenSigSendType" SG_ 260 V_Host_Lat_front 1;
BA_ "GenSigSendType" SG_ 260 LROSYawRate 1;
VAL_ 1863 RTS2C_MC_object_class 10 "unidentified vehicle" 9 "bicycle" 8 "general on-road object" 7 "animal" 6 "tree" 5 "pole" 4 "pedestrian" 3 "truck" 2 "motorcycle" 1 "car" 0 "undetermined" ;
VAL_ 1866 RTS3A_Status 6 "coasted" 5 "updated" 4 "new updated" 3 "new coasted" 2 "new" 1 "merged" 0 "invalid" ;
VAL_ 1866 RTS3A_DetectionSensor 3 "tracklets and vision" 2 "vision only" 1 "multiple tracklets" 0 "single tracklet" ;
VAL_ 1868 RTS3C_MC_object_class 10 "unidentified vehicle" 9 "bicycle" 8 "general on-road object" 7 "animal" 6 "tree" 5 "pole" 4 "pedestrian" 3 "truck" 2 "motorcycle" 1 "car" 0 "undetermined" ;
VAL_ 1871 RTS4A_DetectionSensor 3 "tracklets and vision" 2 "vision only" 1 "multiple tracklets" 0 "single tracklet" ;
VAL_ 1871 RTS4A_Status 6 "coasted" 5 "updated" 4 "new updated" 3 "new coasted" 2 "new" 1 "merged" 0 "invalid" ;
VAL_ 1873 RTS4C_MC_object_class 10 "unidentified vehicle" 9 "bicycle" 8 "general on-road object" 7 "animal" 6 "tree" 5 "pole" 4 "pedestrian" 3 "truck" 2 "motorcycle" 1 "car" 0 "undetermined" ;
VAL_ 521 PB_2C3_EngTrqMinExtRngV_H_b13_0 0 "No Fault" 1 "Fault Present" ;
VAL_ 521 PB_0C9_PT_BPdDscrtInpStV_H_b13_1 0 "No Fault" 1 "Fault Present" ;
VAL_ 521 PB_1F5_TopTrvICltSwActV_H_b13_2 0 "No Fault" 1 "Fault Present" ;
VAL_ 521 PB_1F5_TransEstGearV_H_b13_3 0 "No Fault" 1 "Fault Present" ;
VAL_ 521 PB_1F5_TrnsEngdStateV_H_b13_4 0 "No Fault" 1 "Fault Present" ;
VAL_ 521 PB_3E9_VehSpdAvgDrvnV_H_b13_5 0 "No Fault" 1 "Fault Present" ;
VAL_ 521 PB_3E9_VehSpdAvgNDrvnV_H_b13_6 0 "No Fault" 1 "Fault Present" ;
VAL_ 521 PB_1C4_ACCATCS_RqStat_H_b13_7 0 "No Fault" 1 "Fault Present" ;
VAL_ 521 PB_4F3_PPEIPTCfg2Miss_H_b12_0 0 "No Fault" 1 "Fault Present" ;
VAL_ 521 PB_1C4_ABAAPS_AccPosV_H_b12_1 0 "No Fault" 1 "Fault Present" ;
VAL_ 521 PB_1C5_DrvIAxlTrqMaxV_H_b12_2 0 "No Fault" 1 "Fault Present" ;
VAL_ 521 PB_1C5_DrvIAxlTrqMinV_H_b12_3 0 "No Fault" 1 "Fault Present" ;
VAL_ 521 PB_1C5_DrvIntndAxlTrqV_H_b12_4 0 "No Fault" 1 "Fault Present" ;
VAL_ 521 PB_1C3_EngTrqActExtRngV_H_b12_5 0 "No Fault" 1 "Fault Present" ;
VAL_ 521 PB_1C3_EngTqDrRqExtRngV_H_b12_6 0 "No Fault" 1 "Fault Present" ;
VAL_ 521 PB_2C3_EngTrqMaxExtRngV_H_b12_7 0 "No Fault" 1 "Faut Present" ;
VAL_ 521 PB_0C9_PPEIEngGSt1Miss_H_b11_0 0 "No Fault" 1 "Fault Present" ;
VAL_ 521 PB_1C3_PPEIEngTrqSt2Miss_H_b11_1 0 "No Fault" 1 "Fault Present" ;
VAL_ 521 PB_1C4_PPEITrqReqStMiss_H_b11_2 0 "No Fault" 1 "Fault Present" ;
VAL_ 521 PB_1C5_PPEIDrIAxTqStMiss_H_b11_3 0 "No Fault" 1 "Fault Present" ;
VAL_ 521 PB_1F5_PPEITrGenSt2Miss_H_b11_4 0 "No Fault" 1 "Fault Present" ;
VAL_ 521 PB_2C3_PPEIEngTrqSt3Miss_H_b11_5 0 "No Fault" 1 "Fault Present" ;
VAL_ 521 PB_3E9_PPEIVehSpdDisMiss_H_b11_6 0 "No Fault" 1 "Fault Present" ;
VAL_ 521 PB_4F1_PPEIPTConfMiss_H_b11_7 0 "No Fault" 1 "Fault Present" ;
VAL_ 521 MRRPCANIntComp_H_b10_0 0 "No Fault" 1 "Fault Present" ;
VAL_ 521 PCAN_330_IMULonAccSecAval_H_b10_ 0 "No Fault" 1 "Fault Present" ;
VAL_ 521 PCAN_340_IMUYawRtSecAval_H_b10_2 0 "No Fault" 1 "Fault Present" ;
VAL_ 521 PCAN_340_IMULatAccSecAval_H_b10_ 0 "No Fault" 1 "Fault Present" ;
VAL_ 521 PB_1E5_StrWhlAngSenTyp_H_b10_5 0 "No Fault" 1 "Fault Present" ;
VAL_ 520 FCMIndSTB_H_bF_0 0 "No Fault" 1 "Fault Present" ;
VAL_ 520 FCMIndSTGorOPN_H_bF_1 0 "No Fault" 1 "Fault Present" ;
VAL_ 520 LKASwtchSTG_H_bF_2 0 "No Fault" 1 "Fault Present" ;
VAL_ 520 MRRPCANMissingMsgHOST_H_bF_4 0 "No Fault" 1 "Fault Present" ;
VAL_ 520 MRRPCANMissingMsgVFP_H_bF_5 0 "No Fault" 1 "Fault Present" ;
VAL_ 520 MRRPCANRangeCheckVFP_H_bF_6 0 "No Fault" 1 "Fault Present" ;
VAL_ 520 MRRPCANInvalidDataVFP_H_bF_7 0 "No Fault" 1 "Fault Present" ;
VAL_ 520 VisionInternalError_H_bE_0 0 "No Fault" 1 "Fault Present" ;
VAL_ 520 VINMismatch_H_bE_1 0 "No Fault" 1 "Fault Present" ;
VAL_ 520 ECUSWCalDataSetNotProg_H_bE_2 0 "No Fault" 1 "Fault Present" ;
VAL_ 520 VehConfNotProg_H_bE_3 0 "No Fault" 1 "Fault Present" ;
VAL_ 520 VINNotProg_H_bE_4 0 "No Fault" 1 "Fault Present" ;
VAL_ 520 CameraCalNotLearnt_H_bE_5 0 "No Fault" 1 "Fault Present" ;
VAL_ 520 HostVCANBusOff_H_bE_6 0 "No Fault" 1 "Fault Present" ;
VAL_ 520 SysDisabledInfoStored_H_bE_7 0 "No Fault" 1 "Fault Present" ;
VAL_ 520 HostCoreSelftestFault_H_bD_0 0 "No Fault" 1 "Fault Present" ;
VAL_ 520 ECCSelfTestCheckFault_H_bD_1 0 "No Fault" 1 "Fault Present" ;
VAL_ 520 HostCoreExceptionFault_H_bD_2 0 "No Fault" 1 "Fault Present" ;
VAL_ 520 HostCtrConfigRegFault_H_bD_3 0 "No Fault" 1 "Fault Present" ;
VAL_ 520 HostADCSelfTestFault_H_bD_4 0 "No Fault" 1 "Fault Present" ;
VAL_ 520 HostADCMonitorFault_H_bD_5 0 "No Fault" 1 "Fault Present" ;
VAL_ 520 HostCVMResetFault_H_bD_6 0 "No Fault" 1 "Fault Present" ;
VAL_ 520 HostCVMSTsetFault_H_bD_7 0 "No Fault" 1 "Fault Present" ;
VAL_ 520 AlignAdjustIncorrect_H_bC_0 0 "No Fault" 1 "Fault Present" ;
VAL_ 520 VisionRadar_Missaligned_H_bC_1 0 "No Fault" 1 "Fault Present" ;
VAL_ 520 Vision_OutOfFocus_Fault_H_bC_2 0 "No Fault" 1 "Fault Present" ;
VAL_ 520 Vision_OutOfCalibration_H_bC_3 0 "No Fault" 1 "Fautl Present" ;
VAL_ 520 HostISRConsistencyCheck_H_bC_5 0 "No Fault" 1 "Fault Present" ;
VAL_ 520 ECCSelfTest_CF_H_bC_6 0 "No Fault" 1 "Fault Present" ;
VAL_ 520 ECCSelfTest_RAM_H_bC_7 0 "No Fault" 1 "Fault Present" ;
VAL_ 520 Smeared_Spots_fault_H_bB_0 0 "No Fault" 1 "Fault Present" ;
VAL_ 520 SelfGlare_fault_H_bB_1 0 "No Fault" 1 "Fault Present" ;
VAL_ 520 Low_Visibility_fault_H_bB_2 0 "No Fault" 1 "Fault Present" ;
VAL_ 520 imager_pattern_fault_H_bB_4 0 "No Fault" 1 "Fault Present" ;
VAL_ 520 HostSWP2RAMCRCFlt_H_bB_5 0 "No Fault" 1 "Fault Present" ;
VAL_ 520 VisionAlignIncomplete_H_bB_6 0 "No Fault" 1 "Fault Present" ;
VAL_ 520 Full_Blockage_fault_H_bA_0 0 "No Fault" 1 "Fault Present" ;
VAL_ 520 Blurred_Image_fault_H_bA_1 2 "No Fault" 1 "Fault Present" ;
VAL_ 520 TD_Blockage_Fault_H_bA_2 0 "No Fault" 1 "Fault Present" ;
VAL_ 520 Splashes_fault_H_bA_3 0 "No Fault" 1 "Fault Present" ;
VAL_ 520 Low_Sun_fault_H_bA_4 0 "No Fault" 1 "Fault Present" ;
VAL_ 520 Sun_Rays_faults_H_bA_5 0 "No Fault" 1 "Fault Present" ;
VAL_ 520 Foggy_Spots_fault_H_bA_6 0 "No Fault" 1 "Fault Present" ;
VAL_ 520 Spot_Rays_fault_H_bA_7 0 "No Fault" 1 "Fault Present" ;
VAL_ 520 HostPLLStoppedFault_H_b9_0 0 "No Fault" 1 "Fault Present" ;
VAL_ 520 HostWatchDogSelftestFault_H_b9_1 0 "No Fault" 1 "Fault Present" ;
VAL_ 520 VfpCamMalFunc_H_b9_2 0 "No Fault" 1 "Fault Present" ;
VAL_ 520 VfpCamCtrlFlt_H_b9_3 0 "No Fault" 1 "Fault Present" ;
VAL_ 520 VfpCamVdoFlt_H_b9_5 0 "No Fault" 1 "Fault Present" ;
VAL_ 520 Partial_Blockage_fault_H_b9_7 0 "No Fault" 1 "Fault Present" ;
VAL_ 520 CMBB_ACC_ValFault_H_b8_2 0 "No Fault" 1 "Fault Present" ;
VAL_ 520 HostSWResetMismatchFault_H_b8_3 0 "No Fault" 1 "Fault Present" ;
VAL_ 520 CAN_BDU_Msg_Invalid_H_b8_4 0 "No Fault" 1 "Fault Present" ;
VAL_ 520 HostCSIHPeripheralFault_H_b8_5 0 "No Fault" 1 "Fault Present" ;
VAL_ 520 HostCANPeripheralFault_H_b8_6 0 "No Fault" 1 "Fault Present" ;
VAL_ 520 HostHighSpdOscStopFault_H_b8_7 0 "No Fault" 1 "Fault Present" ;
VAL_ 519 grab_issue_failure_H_b7_0 0 "No Fault" 1 "Fault Present" ;
VAL_ 519 grab_acquire_failure_H_b7_1 0 "No Fault" 1 "Fault Present" ;
VAL_ 519 grab_release_failure_H_b7_2 0 "No Fault" 1 "Fault Present" ;
VAL_ 519 VFP_subsystem_comm_fault_H_b7_3 0 "No Fault" 1 "Fault Present" ;
VAL_ 519 parameters_invalid_H_b7_4 0 "No Fault" 1 "Fault Present" ;
VAL_ 519 ThermistorOutOfRange_H_b7_5 0 "No Fault" 1 "Fault Present" ;
VAL_ 519 BatteryHighFault_H_b7_6 0 "No Fault" 1 "Fault Present" ;
VAL_ 519 BatteryLowFault_H_b7_7 0 "No Fault" 1 "Fault Present" ;
VAL_ 519 VFPCoreDumpFault_H_b6_0 0 "No Fault" 1 "Fault Present" ;
VAL_ 519 DDROverTemp_H_b6_1 0 "No Fault" 1 "Fault Present" ;
VAL_ 519 BusOffPCAN_H_b6_3 0 "No Fault" 1 "Fault Present" ;
VAL_ 519 init_vdi_failure_H_b6_5 0 "No Fault" 1 "Fault Present" ;
VAL_ 519 init_I2C_failure_H_b6_6 0 "No Fault" 1 "Fault Present" ;
VAL_ 519 grab_no_free_header_failure_H_b6 0 "No Fault" 1 "Fault Present" ;
VAL_ 519 HostSpiCRC_H_b5_0 0 "No Fault" 1 "Fault Present" ;
VAL_ 519 VFPSpiFrameFormatError_H_b5_1 0 "No Fault" 1 "Fault Present" ;
VAL_ 519 VFPSpiMsgFormatError_H_b5_2 0 "No Fault" 1 "Fault Present" ;
VAL_ 519 VFPSpiMsgTimeout_H_b5_3 0 "No Fault" 1 "Fault Present" ;
VAL_ 519 VFPModeFault_H_b5_4 0 "No Fault" 1 "Fault Present" ;
VAL_ 519 VFPSpiCRC_H_b5_5 0 "No Fault" 1 "Fault Present" ;
VAL_ 519 SpiIpcCommReset_H_b5_6 0 "No Fault " 1 "Fault Present" ;
VAL_ 519 VFPInitTimeout_H_b5_7 0 "No Fault" 1 "Fault Present" ;
VAL_ 519 v2_8_ImagerInterfaceFault_H_b4_0 0 "No Fault" 1 "Fault Present" ;
VAL_ 519 v1_8_SupplyOutOfRangeFault_H_b4_ 0 "No Fault" 1 "Fault Present" ;
VAL_ 519 v1_2_SupplyOutOfRangeFault_H_b4_ 0 "No Fault" 1 "Fault Present" ;
VAL_ 519 HostSpiFrameFormatError_H_b4_3 0 "No Fault" 1 "Fault Present" ;
VAL_ 519 HostSpiMsgFormatError_H_b4_4 0 "No Fault" 1 "Fault Present" ;
VAL_ 519 HostSpiMsgTimeout_H_b4_5 0 "No Fault" 1 "Fault Present" ;
VAL_ 519 SPIVersionMismatch_H_b4_6 0 "No Fault" 1 "Fault Present" ;
VAL_ 519 HostSpiTxError_H_b4_7 0 "No Fault" 1 "Fault Present" ;
VAL_ 519 VFPBootOverTemp_H_b3_0 0 "No Fault" 1 "Fault Present" ;
VAL_ 519 HostRAMECC_H_b3_1 0 "No Fault" 1 "Fault Present" ;
VAL_ 519 HostInstructionSetCheckFault_H_b 0 "No Fault" 1 "Fault Present" ;
VAL_ 519 VfpBistMemRFlt_H_b3_3 0 "No Fault" 1 "Fault Present" ;
VAL_ 519 HostOscillatorStopped_H_b3_4 0 "No Fault" 1 "Fault Present" ;
VAL_ 519 HostStackOverflowFault_H_b3_5 0 "No Fault" 1 "Fault Present" ;
VAL_ 519 HostCOPFault_H_b3_6 0 "No Fault" 1 "Fault Present" ;
VAL_ 519 v5_0_SupplyOutOfRangeFault_H_b3_ 0 "No Fault" 1 "Fault Present" ;
VAL_ 519 VfpDDRFlt_H_b2_0 0 "No Fault" 1 "Fault Present" ;
VAL_ 519 DdrRamCrc_H_b2_1 0 "No Fault" 1 "Fault Present" ;
VAL_ 519 VfpBootFlt_H_b2_2 0 "No Fault" 1 "Fault Present" ;
VAL_ 519 VfpCoreFlt_H_b2_3 0 "No Fault" 1 "Fault Present" ;
VAL_ 519 HostCodeFlashECC_H_b2_4 0 "No Fault" 1 "Fault Present" ;
VAL_ 519 HostDataFlashECC_H_b2_5 0 "No Fault" 1 "Fault Present" ;
VAL_ 519 SerialFlashPowerUpFail_H_b2_6 0 "No Fault" 1 "Fault Present" ;
VAL_ 519 HostRamFault_H_b2_7 0 "No Fault" 1 "Fault Present" ;
VAL_ 519 KAMChecksumFault_H_b1_0 0 "No Fault" 1 "Fault Present" ;
VAL_ 519 HostApplicationCRC_H_b1_1 0 "No Fault" 1 "Fault Present" ;
VAL_ 519 HostCalibrationCRC_H_b1_2 0 "No Fault" 1 "Fault Present" ;
VAL_ 519 VFPApplicationChecksum_H_b1_3 0 "No Fault" 1 "Fault Present" ;
VAL_ 519 VFPCalibrationChecksum_H_b1_4 0 "No Fault" 1 "Fault Present" ;
VAL_ 519 HostCalComplAndCompat_H_b1_5 0 "No Fault" 1 "Fault Present" ;
VAL_ 519 VFPAppComplAndCompat_H_b1_6 0 "No Fault" 1 "Fault Present" ;
VAL_ 519 InvalidAHBCSensParams_H_b1_7 0 "No Fault" 1 "Fault Present" ;
VAL_ 519 VFPCalComplCompatSWP3_H_b0_1 0 "No Fault" 1 "Fault Present" ;
VAL_ 519 VFPCalComplCompatSWP5_H_b0_2 0 "No Fault" 1 "Fault Present" ;
VAL_ 519 SystemOverTemperature_H_b0_3 0 "No Fault" 1 "Fault Present" ;
VAL_ 519 OnBdThermOvrTemp_H_b0_4 0 "No Fault" 1 "Fault Present" ;
VAL_ 519 VFPMIPSOverTemp_H_b0_5 0 "No Fault" 1 "Fault Present" ;
VAL_ 519 VFPVMPOverTemp_H_b0_6 0 "No Fault" 1 "Fault Present" ;
VAL_ 519 VFPImagerOverTemp_H_b0_7 0 "No Fault" 1 "Fault Present" ;
VAL_ 514 PB_2C3_EngTrqMinExtRngV_A_b13_0 0 "No Fault" 1 "Fault Present" ;
VAL_ 514 PB_0C9_PT_BPdDscrtInpStV_A_b13_1 0 "No Fault" 1 "Fault Present" ;
VAL_ 514 PB_1F5_TopTrvICltSwActV_A_b13_2 0 "No Fault" 1 "Fault Present" ;
VAL_ 514 PB_1F5_TransEstGearV_A_b13_3 0 "No Fault" 1 "Fault Present" ;
VAL_ 514 PB_1F5_TrnsEngdStateV_A_b13_4 0 "No Fault" 1 "Fault Present" ;
VAL_ 514 PB_3E9_VehSpdAvgDrvnV_A_b13_5 0 "No Fault" 1 "Fault Present" ;
VAL_ 514 PB_3E9_VehSpdAvgNDrvnV_A_b13_6 0 "No Fault" 1 "Fault Present" ;
VAL_ 514 PB_1C4_ACCATCS_RqStat_A_b13_7 0 "No Fault" 1 "Fault Present" ;
VAL_ 514 PB_4F3_PPEIPTCfg2Miss_A_b12_0 0 "No Fault" 1 "Fault Present" ;
VAL_ 514 PB_1C4_ABAAPS_AccPosV_A_b12_1 0 "No Fault" 1 "Fault Present" ;
VAL_ 514 PB_1C5_DrvIAxlTrqMaxV_A_b12_2 0 "No Fault" 1 "Fault Present" ;
VAL_ 514 PB_1C5_DrvIAxlTrqMinV_A_b12_3 0 "No Fault" 1 "Fault Present" ;
VAL_ 514 PB_1C5_DrvIntndAxlTrqV_A_b12_4 0 "No Fault" 1 "Fault Present" ;
VAL_ 514 PB_1C3_EngTrqActExtRngV_A_b12_5 0 "No Fault" 1 "Fault Present" ;
VAL_ 514 PB_1C3_EngTqDrRqExtRngV_A_b12_6 0 "No Fault" 1 "Fault Present" ;
VAL_ 514 PB_2C3_EngTrqMaxExtRngV_A_b12_7 0 "No Fault" 1 "Fault Present" ;
VAL_ 514 PB_0C9_PPEIEngGSt1Miss_A_b11_0 0 "No Fault" 1 "Fault Present" ;
VAL_ 514 PB_1C3_PPEIEngTrqSt2Miss_A_b11_1 0 "No Fault" 1 "Fault Present" ;
VAL_ 514 PB_1C4_PPEITrqReqStMiss_A_b11_2 0 "No Fault" 1 "Fault Present" ;
VAL_ 514 PB_1C5_PPEIDrIAxTqStMiss_A_b11_3 0 "No Fault" 1 "Fault Present" ;
VAL_ 514 PB_1F5_PPEITrGenSt2Miss_A_b11_4 0 "No Fault" 1 "Fault Present" ;
VAL_ 514 PB_2C3_PPEIEngTrqSt3Miss_A_b11_5 0 "No Fault" 1 "Fault Present" ;
VAL_ 514 PB_3E9_PPEIVehSpdDisMiss_A_b11_6 0 "No Fault" 1 "Fault Present" ;
VAL_ 514 PB_4F1_PPEIPTConfMiss_A_b11_7 0 "No Fault" 1 "Fault Present" ;
VAL_ 514 MRRPCANIntComp_A_b10_0 0 "No Fault" 1 "Fault Present" ;
VAL_ 514 PCAN_330_IMULonAccSecAval_A_b10_ 0 "No Fault" 1 "Fault Present" ;
VAL_ 514 PCAN_340_IMUYawRtSecAval_A_b10_2 0 "No Fault" 1 "Fault Present" ;
VAL_ 514 PCAN_340_IMULatAccSecAval_A_b10_ 0 "No Fault" 1 "Fault Present" ;
VAL_ 514 PB_1E5_StrWhlAngSenTyp_A_b10_5 0 "No Fault" 1 "Fault Present" ;
VAL_ 513 FCMIndSTB_A_bF_0 0 "No Fault" 1 "Fault Present" ;
VAL_ 513 FCMIndSTGorOPN_A_bF_1 0 "No Fault" 1 "Fault Present" ;
VAL_ 513 LKASwtchSTG_A_bF_2 0 "No Fault" 1 "Fault Present" ;
VAL_ 513 MRRPCANMissingMsgHOST_A_bF_4 0 "No Fault" 1 "Fault Present" ;
VAL_ 513 MRRPCANMissingMsgVFP_A_bF_5 0 "No Fault" 1 "Fault Present" ;
VAL_ 513 MRRPCANRangeCheckVFP_A_bF_6 0 "No Fault" 1 "Fault Present" ;
VAL_ 513 MRRPCANInvalidDataVFP_A_bF_7 0 "No Fault" 1 "Fault Present" ;
VAL_ 513 VisionInternalError_A_bE_0 0 "No Fault" 1 "Fault Present" ;
VAL_ 513 VINMismatch_A_bE_1 0 "No Fault" 1 "Fault Present" ;
VAL_ 513 ECUSWCalDataSetNotProg_A_bE_2 0 "No Fault" 1 "Fault Present" ;
VAL_ 513 VehConfNotProg_A_bE_3 0 "No Fault" 1 "Fault Present" ;
VAL_ 513 VINNotProg_A_bE_4 0 "No Fault" 1 "Fault Present" ;
VAL_ 513 CameraCalNotLearnt_A_bE_5 0 "No Fault" 1 "Fault Present" ;
VAL_ 513 HostVCANBusOff_A_bE_6 0 "No Fault" 1 "Fault Present" ;
VAL_ 513 SysDisabledInfoStored_A_bE_7 0 "No Fault" 1 "Fault Present" ;
VAL_ 513 HostCoreSelftestFault_A_bD_0 0 "No Fault" 1 "Fault Present" ;
VAL_ 513 ECCSelfTestCheckFault_A_bD_1 0 "No Fault" 1 "Fault Present" ;
VAL_ 513 HostCoreExceptionFault_A_bD_2 0 "No Fault" 1 "Fault Present" ;
VAL_ 513 HostCtrConfigRegFault_A_bD_3 0 "No Fault" 1 "Fault Present" ;
VAL_ 513 HostADCSelfTestFault_A_bD_4 0 "No Fault" 1 "Fault Present" ;
VAL_ 513 HostADCMonitorFault_A_bD_5 0 "No Fault" 1 "Fault Present" ;
VAL_ 513 HostCVMResetFault_A_bD_6 0 "No Fault" 1 "Fault Present" ;
VAL_ 513 HostCVMSTsetFault_A_bD_7 0 "No Fault" 1 "Fault Present" ;
VAL_ 513 AlignAdjustIncorrect_A_bC_0 0 "No Fault" 1 "Fault Present" ;
VAL_ 513 VisionRadar_Missaligned_A_bC_1 0 "No Fault" 1 "Fault Present" ;
VAL_ 513 Vision_OutOfFocus_Fault_A_bC_2 0 "No Fault" 1 "Fault Present" ;
VAL_ 513 Vision_OutOfCalibration_A_bC_3 0 "No Fault" 1 "Fault Present" ;
VAL_ 513 HostISRConsistencyCheck_A_bC_5 0 "No Fault" 1 "Fault Present" ;
VAL_ 513 ECCSelfTest_CF_A_bC_6 0 "No Fault" 1 "Fault Present" ;
VAL_ 513 ECCSelfTest_RAM_A_bC_7 0 "No Fault" 1 "Fault Present" ;
VAL_ 513 Smeared_Spots_fault_A_bB_0 0 "No Fault" 1 "Fault Present" ;
VAL_ 513 SelfGlare_fault_A_bB_1 0 "No Fault" 1 "Fault Present" ;
VAL_ 513 Low_Visibility_fault_A_bB_2 0 "No Fault" 1 "Fault Present" ;
VAL_ 513 imager_pattern_fault_A_bB_4 0 "No Fault" 1 "Fault Present" ;
VAL_ 513 HostSWP2RAMCRCFlt_A_bB_5 0 "No Fault" 1 "Fault Present" ;
VAL_ 513 VisionAlignIncomplete_A_bB_6 0 "No Fault" 1 "Fault Present" ;
VAL_ 513 Full_Blockage_fault_A_bA_0 0 "No Fault" 1 "Fault Present" ;
VAL_ 513 Blurred_Image_fault_A_bA_1 0 "No Fault" 1 "Fault Present" ;
VAL_ 513 TD_Blockage_Fault_A_bA_2 0 "No Fault" 1 "Fault Present" ;
VAL_ 513 Splashes_fault_A_bA_3 0 "No Fault" 1 "Fault Present" ;
VAL_ 513 Low_Sun_fault_A_bA_4 0 "No Fault" 1 "Fault Present" ;
VAL_ 513 Sun_Rays_faults_A_bA_5 0 "No Fault" 1 "Fault Present" ;
VAL_ 513 Foggy_Spots_fault_A_bA_6 0 "No Fault" 1 "Fault Present" ;
VAL_ 513 Spot_Rays_fault_A_bA_7 0 "No Fault" 1 "Fault Present" ;
VAL_ 513 HostPLLStoppedFault_A_b9_0 0 "No Fault" 1 "Fault Present" ;
VAL_ 513 HostWatchDogSelftestFault_A_b9_1 0 "No Fault" 1 "Fault Present" ;
VAL_ 513 VfpCamMalFunc_A_b9_2 0 "No Fault" 1 "Fault Present" ;
VAL_ 513 VfpCamCtrlFlt_A_b9_3 0 "No Fault" 1 "Fault Present" ;
VAL_ 513 VfpCamVdoFlt_A_b9_5 0 "No Fault" 1 "Fault Present" ;
VAL_ 513 Partial_Blockage_fault_A_b9_7 0 "No Fault" 1 "Fault Present" ;
VAL_ 513 CMBB_ACC_ValFault_A_b8_2 0 "No Fault" 1 "Fault Present" ;
VAL_ 513 HostSWResetMismatchFault_A_b8_3 0 "No Fault" 1 "Fault Present" ;
VAL_ 513 CAN_BDU_Msg_Invalid_A_b8_4 0 "No Fault" 1 "Fault Present" ;
VAL_ 513 HostCSIHPeripheralFault_A_b8_5 0 "No Fault" 1 "Fault Present" ;
VAL_ 513 HostCANPeripheralFault_A_b8_6 0 "No Fault" 1 "Fault Present" ;
VAL_ 513 HostHighSpdOscStopFault_A_b8_7 0 "No Fault" 1 "Fault Present" ;
VAL_ 512 grab_issue_failure_A_b7_0 0 "No Fault" 1 "Fault Present" ;
VAL_ 512 grab_acquire_failure_A_b7_1 0 "No Fault" 1 "Fault Present" ;
VAL_ 512 grab_release_failure_A_b7_2 0 "No Fault" 1 "Fault Present" ;
VAL_ 512 VFP_subsystem_comm_fault_A_b7_3 0 "No Fault" 1 "Fault Present" ;
VAL_ 512 parameters_invalid_A_b7_4 0 "No Fault" 1 "Fault Present" ;
VAL_ 512 ThermistorOutOfRange_A_b7_5 0 "No Fault" 1 "Fault Present" ;
VAL_ 512 BatteryHighFault_Act_A_b7_6 0 "No Fault" 1 "Fault Present" ;
VAL_ 512 BatteryLowFault_Act_A_b7_7 0 "No Fault" 1 "Fault Present" ;
VAL_ 512 VFPCoreDumpFault_A_b6_0 0 "No Fault" 1 "Fault Present" ;
VAL_ 512 DDROverTemp_A_b6_1 0 "No Fault" 1 "Fault Present" ;
VAL_ 512 BusOffPCAN_A_b6_3 0 "No Fault" 1 "Fault Present" ;
VAL_ 512 init_vdi_failure_A_b6_5 0 "No Fault" 1 "Fault Present" ;
VAL_ 512 init_I2C_failure_A_b6_6 0 "No Fault" 1 "Fault Present" ;
VAL_ 512 grab_no_free_header_failure_A_b6 0 "No Fault" 1 "Fault Present" ;
VAL_ 512 HostSpiCRC_A_b5_0 0 "No Fault" 1 "Fault Present" ;
VAL_ 512 VFPSpiFrameFormatError_A_b5_1 0 "No Fault" 1 "Fault Present" ;
VAL_ 512 VFPSpiMsgFormatError_A_b5_2 0 "No Fault" 1 "Fault Present" ;
VAL_ 512 VFPSpiMsgTimeout_A_b5_3 0 "No Fault" 1 "Fault Present" ;
VAL_ 512 VFPModeFault_A_b5_4 0 "No Fault" 1 "Fault Present" ;
VAL_ 512 VFPSpiCRC_A_b5_5 0 "No Fault" 1 "Fault Present" ;
VAL_ 512 SpiIpcCommReset_A_b5_6 0 "No Fault" 1 "Fault Present" ;
VAL_ 512 VFPInitTimeout_A_b5_7 0 "No Fault" 1 "Fault Present" ;
VAL_ 512 v2_8_ImagerInterfaceFault_A_b4_0 0 "No Fault" 1 "Fault Present" ;
VAL_ 512 v1_8_SupplyOutOfRangeFault_A_b4_ 0 "No Fault" 1 "Fault Present" ;
VAL_ 512 v1_2_SupplyOutOfRangeFault_A_b4_ 0 "No Fault" 1 "Fault Present" ;
VAL_ 512 HostSpiFrameFormatError_A_b4_3 0 "No Fault" 1 "Fault Present" ;
VAL_ 512 HostSpiMsgFormatError_A_b4_4 0 "No Fault" 1 "Fault Present" ;
VAL_ 512 HostSpiMsgTimeout_A_b4_5 0 "No Fault" 1 "Fault Present" ;
VAL_ 512 SPIVersionMismatch_A_b4_6 0 "No Fault" 1 "Fault Present" ;
VAL_ 512 HostSpiTxError_A_b4_7 0 "No Fault" 1 "Fault Present" ;
VAL_ 512 VFPBootOverTemp_A_b3_0 0 "No Fault" 1 "Fault Present" ;
VAL_ 512 HostRAMECC_A_b3_1 0 "No Fault" 1 "Fault Present" ;
VAL_ 512 HostInstructionSetCheckFault_A_b 0 "No Fault" 1 "Fault Present" ;
VAL_ 512 VfpBistMemRFlt_A_b3_3 0 "No Fault" 1 "Fault Present" ;
VAL_ 512 HostOscillatorStopped_A_b3_4 0 "No Fault" 1 "Fault Present" ;
VAL_ 512 HostStackOverflowFault_A_b3_5 0 "No Fault" 1 "Fault Present" ;
VAL_ 512 HostCOPFault_A_b3_6 0 "No Fault" 1 "Fault Present" ;
VAL_ 512 v5_0_SupplyOutOfRangeFault_A_b3_ 0 "No Fault" 1 "Fault Present" ;
VAL_ 512 VfpDDRFlt_A_b2_0 0 "No Fault" 1 "Fault Present" ;
VAL_ 512 DdrRamCrc_A_b2_1 0 "No Fault" 1 "Fault Present" ;
VAL_ 512 VfpBootFlt_A_b2_2 0 "No Fault" 1 "Fault Present" ;
VAL_ 512 VfpCoreFlt_A_b2_3 0 "No Fault" 1 "Fault Present" ;
VAL_ 512 HostCodeFlashECC_A_b2_4 0 "No Fault" 1 "Fault Present" ;
VAL_ 512 HostDataFlashECC_A_b2_5 0 "No Fault" 1 "Fault Present" ;
VAL_ 512 SerialFlashPowerUpFail_A_b2_6 0 "No Fault" 1 "Fault Present" ;
VAL_ 512 HostRamFault_A_b2_7 0 "No Fault" 1 "Fault Present" ;
VAL_ 512 KAMChecksumFault_A_b1_0 0 "No Fault" 1 "Fault Present" ;
VAL_ 512 HostApplicationCRC_A_b1_1 0 "No Fault" 1 "Fault Present" ;
VAL_ 512 HostCalibrationCRC_A_b1_2 0 "No Fault" 1 "Fault Present" ;
VAL_ 512 VFPApplicationChecksum_A_b1_3 0 "No Fault" 1 "Faul Present" ;
VAL_ 512 VFPCalibrationChecksum_A_b1_4 0 "No Fault" 1 "Fault Present" ;
VAL_ 512 HostCalComplAndCompat_A_b1_5 0 "No Fault" 1 "Fault Present" ;
VAL_ 512 VFPAppComplAndCompat_A_b1_6 0 "No Fault" 1 "Fault Present" ;
VAL_ 512 InvalidAHBCSensParams_A_b1_7 0 "No Fault" 1 "Fault Present" ;
VAL_ 512 VFPCalComplCompatSWP3_A_b0_1 0 "No Fault" 1 "Fault Present" ;
VAL_ 512 VFPCalComplCompatSWP5_A_b0_2 0 "No Fault" 1 "Fault Present" ;
VAL_ 512 SystemOverTemperature_A_b0_3 0 "No Fault" 1 "Fault Present" ;
VAL_ 512 OnBdThermOvrTemp_A_b0_4 0 "No Fault" 1 "Fault Present" ;
VAL_ 512 VFPMIPSOverTemp_A_b0_5 0 "No Fault" 1 "Fault Present" ;
VAL_ 512 VFPVMPOverTemp_A_b0_6 0 "No Fault" 1 "Fault Present" ;
VAL_ 512 VFPImagerOverTemp_A_b0_7 0 "No Fault" 1 "Fault Present" ;
VAL_ 1794 Service 9 "START_DIAGNOSTICS" 8 "SEND_PARAMS_SPC" 7 "SEND_PARAMS_TAC" 6 "SEND_PARAMS_VISION" 5 "SWITCH_STATE_SPC" 4 "SWITCH_STATE_TAC" 3 "SWITCH_STATE_VISION" 2 "GET_EYEQ_MAIN_STATE" 1 "RESET_EYEQ" ;
VAL_ 1536 GPIO_12_16 31 "TBD" 30 "TBD" 29 "TBD" 28 "BIST Fault" 27 "Boot CS Fault" 26 " DDR Fault" 25 "Load Boot fault" 24 "App Block Fault" 23 "App Block CS Fault" 22 "SWP3 Missing" 21 "SWP3 CS Fault" 20 "MEST CS Fault" 19 "MEST DDR Fault" 18 "TBD" 17 "TBD" 16 "TBD" 15 "Boot Mode" 14 "TBD" 13 "TBD" 12 "TBD" 11 "TBD" 10 "Completed Boot" 9 "Completed DDR SWP3 CRC" 8 "Completed DDR App CRC" 7 "Initiated DDR Initial Part Num" 6 "Entered DDR Execution" 5 "Completed Flash Boot DDR CRC" 4 "Completed Flash DDR Check" 3 "Completed Flash Boot CRC" 2 "Completed Flash BIST" 1 "Completed Flash DDR Init" 0 "Initial Default Value" ;
VAL_ 524 ddrTemperature 7 "DDR_TEMP_UNKNOWN" 4 "DDR_TEMP_ERROR" 3 "DDR_TEMP_ABOVE_85C" 2 "DDR_TEMP_ABOVE_SPEC" 1 "DDR_TEMP_BELOW_SPEC" 0 "DDR_TEMP_RANGE_OK" ;
VAL_ 524 vmpTemperature 128 "Unknown" ;
VAL_ 524 mipsTemperature 128 "Unknown" ;
VAL_ 524 imagerTemperature 128 "Unknown" ;
VAL_ 544 Vision_VFP_Mode 4 "DIAG" 3 "TAC" 2 "SPC" 1 "APP" 0 "INIT" ;
VAL_ 544 Internal_VFP_mode 3 "Pending SPC" 2 "Pending TAC" 1 "Pending APP" 0 "Route from API" ;
VAL_ 539 CAN_VFP_RST 1 "Asserting reset" 0 "Released from reset" ;
VAL_ 539 CAN_VFP_RST_POR 1 "Asserting reset" 0 "Released from reset" ;
VAL_ 539 CAN_VFP_IO_STS 30 "VFP_CORE_DUMP_COMPLETE" 29 "VFP_CORE_DUMP_IN_PROGRESS" 24 "APP_BLK_FAULT" 23 "APP_BLK_CRC_FAULT" 22 "SWP3_MISSING" 21 "SWP3_CRC_FAULT" 20 "MEST_CRC_FAULT" 19 "MEST_DDR_FAULT" 15 "BOOT_MODE" 10 "BOOT_SUCCESS_COMPLETE" 9 "SWP3_CRC32_OK" 8 "CRC32_BLK_OK" 7 "PART_NUMBERS_SENT_SPI" 6 "BOOT_PROCESS_STARTED" ;
VAL_ 1921 PCA_SAB_DetectionSensor 3 "tracklets and vision" 2 "vision only" 1 "multiple tracklets" 0 "single tracklet" ;
VAL_ 1921 PCA_SAB_Status 6 "coasted" 5 "updated" 4 "new updated" 3 "new coasted" 2 "new" 1 "merged" 0 "invalid" ;
VAL_ 1921 PCA_SAB_Object_class 10 "unidentified vehicle" 9 "bicycle" 8 "general on-road object" 7 "animal" 6 "tree" 5 "pole" 4 "pedestrian" 3 "truck" 2 "motorcycle" 1 "car" 0 "undetermined" ;
VAL_ 1925 PCA_VAB_DetectionSensor 3 "tracklets and vision" 2 "vision only" 1 "multiple tracklets" 0 "single tracklet" ;
VAL_ 1925 PCA_VAB_Object_class 10 "unidentified vehicle" 9 "bicycle" 8 "general on-road object" 7 "animal" 6 "tree" 5 "pole" 4 "pedestrian" 3 "truck" 2 "motorcycle" 1 "car" 0 "undetermined" ;
